VERSION ""

NS_ :

BS_:

BU_: ICC DVR EPC BBCM EAMP CMSM SBOX FLZCU_HCU_IC FLZCU_IC HCU_IC FLZCU_Signal_IC CGW TBOX BNCM CWC FRZCU

BO_ 1364 ICC_RISD_44: 64 ICC
 SG_ ICC_RISD_FrameCounter : 1|2@0+ (1,0) [0|3] "" Vector__XXX
 SG_ ICC_RISD_RollingCounter : 3|2@0+ (1,0) [0|3] "" Vector__XXX
 SG_ ICC_RISD_Pixel1_OnOff : 8|1@0+ (1,0) [0|1] "" Vector__XXX
 SG_ ICC_RISD_Pixel2_OnOff : 9|1@0+ (1,0) [0|1] "" Vector__XXX
 SG_ ICC_RISD_Pixel3_OnOff : 10|1@0+ (1,0) [0|1] "" Vector__XXX
 SG_ ICC_RISD_Pixel4_OnOff : 11|1@0+ (1,0) [0|1] "" Vector__XXX
 SG_ ICC_RISD_Pixel5_OnOff : 12|1@0+ (1,0) [0|1] "" Vector__XXX
 SG_ ICC_RISD_Pixel6_OnOff : 13|1@0+ (1,0) [0|1] "" Vector__XXX
 SG_ ICC_RISD_Pixel7_OnOff : 14|1@0+ (1,0) [0|1] "" Vector__XXX
 SG_ ICC_RISD_Pixel8_OnOff : 15|1@0+ (1,0) [0|1] "" Vector__XXX
 SG_ ICC_RISD_Pixel9_OnOff : 16|1@0+ (1,0) [0|1] "" Vector__XXX
 SG_ ICC_RISD_Pixel10_OnOff : 17|1@0+ (1,0) [0|1] "" Vector__XXX
 SG_ ICC_RISD_Pixel11_OnOff : 18|1@0+ (1,0) [0|1] "" Vector__XXX
 SG_ ICC_RISD_Pixel12_OnOff : 19|1@0+ (1,0) [0|1] "" Vector__XXX
 SG_ ICC_RISD_Pixel13_OnOff : 20|1@0+ (1,0) [0|1] "" Vector__XXX
 SG_ ICC_RISD_Pixel14_OnOff : 21|1@0+ (1,0) [0|1] "" Vector__XXX
 SG_ ICC_RISD_Pixel15_OnOff : 22|1@0+ (1,0) [0|1] "" Vector__XXX
 SG_ ICC_RISD_Pixel16_OnOff : 23|1@0+ (1,0) [0|1] "" Vector__XXX
 SG_ ICC_RISD_Pixel17_OnOff : 24|1@0+ (1,0) [0|1] "" Vector__XXX
 SG_ ICC_RISD_Pixel18_OnOff : 25|1@0+ (1,0) [0|1] "" Vector__XXX
 SG_ ICC_RISD_Pixel19_OnOff : 26|1@0+ (1,0) [0|1] "" Vector__XXX
 SG_ ICC_RISD_Pixel20_OnOff : 27|1@0+ (1,0) [0|1] "" Vector__XXX
 SG_ ICC_RISD_Pixel21_OnOff : 28|1@0+ (1,0) [0|1] "" Vector__XXX
 SG_ ICC_RISD_Pixel22_OnOff : 29|1@0+ (1,0) [0|1] "" Vector__XXX
 SG_ ICC_RISD_Pixel23_OnOff : 30|1@0+ (1,0) [0|1] "" Vector__XXX
 SG_ ICC_RISD_Pixel24_OnOff : 31|1@0+ (1,0) [0|1] "" Vector__XXX
 SG_ ICC_RISD_Pixel25_OnOff : 32|1@0+ (1,0) [0|1] "" Vector__XXX
 SG_ ICC_RISD_Pixel26_OnOff : 33|1@0+ (1,0) [0|1] "" Vector__XXX
 SG_ ICC_RISD_Pixel27_OnOff : 34|1@0+ (1,0) [0|1] "" Vector__XXX
 SG_ ICC_RISD_Pixel28_OnOff : 35|1@0+ (1,0) [0|1] "" Vector__XXX
 SG_ ICC_RISD_Pixel29_OnOff : 36|1@0+ (1,0) [0|1] "" Vector__XXX
 SG_ ICC_RISD_Pixel30_OnOff : 37|1@0+ (1,0) [0|1] "" Vector__XXX
 SG_ ICC_RISD_Pixel31_OnOff : 38|1@0+ (1,0) [0|1] "" Vector__XXX
 SG_ ICC_RISD_Pixel32_OnOff : 39|1@0+ (1,0) [0|1] "" Vector__XXX
 SG_ ICC_RISD_Pixel33_OnOff : 40|1@0+ (1,0) [0|1] "" Vector__XXX
 SG_ ICC_RISD_Pixel34_OnOff : 41|1@0+ (1,0) [0|1] "" Vector__XXX
 SG_ ICC_RISD_Pixel35_OnOff : 42|1@0+ (1,0) [0|1] "" Vector__XXX
 SG_ ICC_RISD_Pixel36_OnOff : 43|1@0+ (1,0) [0|1] "" Vector__XXX
 SG_ ICC_RISD_Pixel37_OnOff : 44|1@0+ (1,0) [0|1] "" Vector__XXX
 SG_ ICC_RISD_Pixel38_OnOff : 45|1@0+ (1,0) [0|1] "" Vector__XXX
 SG_ ICC_RISD_Pixel39_OnOff : 46|1@0+ (1,0) [0|1] "" Vector__XXX
 SG_ ICC_RISD_Pixel40_OnOff : 47|1@0+ (1,0) [0|1] "" Vector__XXX
 SG_ ICC_RISD_Pixel41_OnOff : 48|1@0+ (1,0) [0|1] "" Vector__XXX
 SG_ ICC_RISD_Pixel42_OnOff : 49|1@0+ (1,0) [0|1] "" Vector__XXX
 SG_ ICC_RISD_Pixel43_OnOff : 50|1@0+ (1,0) [0|1] "" Vector__XXX
 SG_ ICC_RISD_Pixel44_OnOff : 51|1@0+ (1,0) [0|1] "" Vector__XXX
 SG_ ICC_RISD_Pixel45_OnOff : 52|1@0+ (1,0) [0|1] "" Vector__XXX
 SG_ ICC_RISD_Pixel46_OnOff : 53|1@0+ (1,0) [0|1] "" Vector__XXX
 SG_ ICC_RISD_Pixel47_OnOff : 54|1@0+ (1,0) [0|1] "" Vector__XXX
 SG_ ICC_RISD_Pixel48_OnOff : 55|1@0+ (1,0) [0|1] "" Vector__XXX
 SG_ ICC_RISD_Pixel49_OnOff : 56|1@0+ (1,0) [0|1] "" Vector__XXX
 SG_ ICC_RISD_Pixel50_OnOff : 57|1@0+ (1,0) [0|1] "" Vector__XXX
 SG_ ICC_RISD_Pixel51_OnOff : 58|1@0+ (1,0) [0|1] "" Vector__XXX
 SG_ ICC_RISD_Pixel52_OnOff : 59|1@0+ (1,0) [0|1] "" Vector__XXX
 SG_ ICC_RISD_Pixel53_OnOff : 60|1@0+ (1,0) [0|1] "" Vector__XXX
 SG_ ICC_RISD_Pixel54_OnOff : 61|1@0+ (1,0) [0|1] "" Vector__XXX
 SG_ ICC_RISD_Pixel55_OnOff : 62|1@0+ (1,0) [0|1] "" Vector__XXX
 SG_ ICC_RISD_Pixel56_OnOff : 63|1@0+ (1,0) [0|1] "" Vector__XXX
 SG_ ICC_RISD_Pixel57_OnOff : 64|1@0+ (1,0) [0|1] "" Vector__XXX
 SG_ ICC_RISD_Pixel58_OnOff : 65|1@0+ (1,0) [0|1] "" Vector__XXX
 SG_ ICC_RISD_Pixel59_OnOff : 66|1@0+ (1,0) [0|1] "" Vector__XXX
 SG_ ICC_RISD_Pixel60_OnOff : 67|1@0+ (1,0) [0|1] "" Vector__XXX
 SG_ ICC_RISD_Pixel61_OnOff : 68|1@0+ (1,0) [0|1] "" Vector__XXX
 SG_ ICC_RISD_Pixel62_OnOff : 69|1@0+ (1,0) [0|1] "" Vector__XXX
 SG_ ICC_RISD_Pixel63_OnOff : 70|1@0+ (1,0) [0|1] "" Vector__XXX
 SG_ ICC_RISD_Pixel64_OnOff : 71|1@0+ (1,0) [0|1] "" Vector__XXX
 SG_ ICC_RISD_Pixel65_OnOff : 72|1@0+ (1,0) [0|1] "" Vector__XXX
 SG_ ICC_RISD_Pixel66_OnOff : 73|1@0+ (1,0) [0|1] "" Vector__XXX
 SG_ ICC_RISD_Pixel67_OnOff : 74|1@0+ (1,0) [0|1] "" Vector__XXX
 SG_ ICC_RISD_Pixel68_OnOff : 75|1@0+ (1,0) [0|1] "" Vector__XXX
 SG_ ICC_RISD_Pixel69_OnOff : 76|1@0+ (1,0) [0|1] "" Vector__XXX
 SG_ ICC_RISD_Pixel70_OnOff : 77|1@0+ (1,0) [0|1] "" Vector__XXX
 SG_ ICC_RISD_Pixel71_OnOff : 78|1@0+ (1,0) [0|1] "" Vector__XXX
 SG_ ICC_RISD_Pixel72_OnOff : 79|1@0+ (1,0) [0|1] "" Vector__XXX
 SG_ ICC_RISD_Pixel73_OnOff : 80|1@0+ (1,0) [0|1] "" Vector__XXX
 SG_ ICC_RISD_Pixel74_OnOff : 81|1@0+ (1,0) [0|1] "" Vector__XXX
 SG_ ICC_RISD_Pixel75_OnOff : 82|1@0+ (1,0) [0|1] "" Vector__XXX
 SG_ ICC_RISD_Pixel76_OnOff : 83|1@0+ (1,0) [0|1] "" Vector__XXX
 SG_ ICC_RISD_Pixel77_OnOff : 84|1@0+ (1,0) [0|1] "" Vector__XXX
 SG_ ICC_RISD_Pixel78_OnOff : 85|1@0+ (1,0) [0|1] "" Vector__XXX
 SG_ ICC_RISD_Pixel79_OnOff : 86|1@0+ (1,0) [0|1] "" Vector__XXX
 SG_ ICC_RISD_Pixel80_OnOff : 87|1@0+ (1,0) [0|1] "" Vector__XXX
 SG_ ICC_RISD_Pixel81_OnOff : 88|1@0+ (1,0) [0|1] "" Vector__XXX
 SG_ ICC_RISD_Pixel82_OnOff : 89|1@0+ (1,0) [0|1] "" Vector__XXX
 SG_ ICC_RISD_Pixel83_OnOff : 90|1@0+ (1,0) [0|1] "" Vector__XXX
 SG_ ICC_RISD_Pixel84_OnOff : 91|1@0+ (1,0) [0|1] "" Vector__XXX
 SG_ ICC_RISD_Pixel85_OnOff : 92|1@0+ (1,0) [0|1] "" Vector__XXX
 SG_ ICC_RISD_Pixel86_OnOff : 93|1@0+ (1,0) [0|1] "" Vector__XXX
 SG_ ICC_RISD_Pixel87_OnOff : 94|1@0+ (1,0) [0|1] "" Vector__XXX
 SG_ ICC_RISD_Pixel88_OnOff : 95|1@0+ (1,0) [0|1] "" Vector__XXX
 SG_ ICC_RISD_Pixel89_OnOff : 96|1@0+ (1,0) [0|1] "" Vector__XXX
 SG_ ICC_RISD_Pixel90_OnOff : 97|1@0+ (1,0) [0|1] "" Vector__XXX
 SG_ ICC_RISD_Pixel91_OnOff : 98|1@0+ (1,0) [0|1] "" Vector__XXX
 SG_ ICC_RISD_Pixel92_OnOff : 99|1@0+ (1,0) [0|1] "" Vector__XXX
 SG_ ICC_RISD_Pixel93_OnOff : 100|1@0+ (1,0) [0|1] "" Vector__XXX
 SG_ ICC_RISD_Pixel94_OnOff : 101|1@0+ (1,0) [0|1] "" Vector__XXX
 SG_ ICC_RISD_Pixel95_OnOff : 102|1@0+ (1,0) [0|1] "" Vector__XXX
 SG_ ICC_RISD_Pixel96_OnOff : 103|1@0+ (1,0) [0|1] "" Vector__XXX
 SG_ ICC_RISD_Pixel97_OnOff : 104|1@0+ (1,0) [0|1] "" Vector__XXX
 SG_ ICC_RISD_Pixel98_OnOff : 105|1@0+ (1,0) [0|1] "" Vector__XXX
 SG_ ICC_RISD_Pixel99_OnOff : 106|1@0+ (1,0) [0|1] "" Vector__XXX
 SG_ ICC_RISD_Pixel100_OnOff : 107|1@0+ (1,0) [0|1] "" Vector__XXX
 SG_ ICC_RISD_Pixel101_OnOff : 108|1@0+ (1,0) [0|1] "" Vector__XXX
 SG_ ICC_RISD_Pixel102_OnOff : 109|1@0+ (1,0) [0|1] "" Vector__XXX
 SG_ ICC_RISD_Pixel103_OnOff : 110|1@0+ (1,0) [0|1] "" Vector__XXX
 SG_ ICC_RISD_Pixel104_OnOff : 111|1@0+ (1,0) [0|1] "" Vector__XXX
 SG_ ICC_RISD_Pixel105_OnOff : 112|1@0+ (1,0) [0|1] "" Vector__XXX
 SG_ ICC_RISD_Pixel106_OnOff : 113|1@0+ (1,0) [0|1] "" Vector__XXX
 SG_ ICC_RISD_Pixel107_OnOff : 114|1@0+ (1,0) [0|1] "" Vector__XXX
 SG_ ICC_RISD_Pixel108_OnOff : 115|1@0+ (1,0) [0|1] "" Vector__XXX
 SG_ ICC_RISD_Pixel109_OnOff : 116|1@0+ (1,0) [0|1] "" Vector__XXX
 SG_ ICC_RISD_Pixel110_OnOff : 117|1@0+ (1,0) [0|1] "" Vector__XXX
 SG_ ICC_RISD_Pixel111_OnOff : 118|1@0+ (1,0) [0|1] "" Vector__XXX
 SG_ ICC_RISD_Pixel112_OnOff : 119|1@0+ (1,0) [0|1] "" Vector__XXX
 SG_ ICC_RISD_Pixel113_OnOff : 120|1@0+ (1,0) [0|1] "" Vector__XXX
 SG_ ICC_RISD_Pixel114_OnOff : 121|1@0+ (1,0) [0|1] "" Vector__XXX
 SG_ ICC_RISD_Pixel115_OnOff : 122|1@0+ (1,0) [0|1] "" Vector__XXX
 SG_ ICC_RISD_Pixel116_OnOff : 123|1@0+ (1,0) [0|1] "" Vector__XXX
 SG_ ICC_RISD_Pixel117_OnOff : 124|1@0+ (1,0) [0|1] "" Vector__XXX
 SG_ ICC_RISD_Pixel118_OnOff : 125|1@0+ (1,0) [0|1] "" Vector__XXX
 SG_ ICC_RISD_Pixel119_OnOff : 126|1@0+ (1,0) [0|1] "" Vector__XXX
 SG_ ICC_RISD_Pixel120_OnOff : 127|1@0+ (1,0) [0|1] "" Vector__XXX
 SG_ ICC_RISD_Pixel121_OnOff : 128|1@0+ (1,0) [0|1] "" Vector__XXX
 SG_ ICC_RISD_Pixel122_OnOff : 129|1@0+ (1,0) [0|1] "" Vector__XXX
 SG_ ICC_RISD_Pixel123_OnOff : 130|1@0+ (1,0) [0|1] "" Vector__XXX
 SG_ ICC_RISD_Pixel124_OnOff : 131|1@0+ (1,0) [0|1] "" Vector__XXX
 SG_ ICC_RISD_Pixel125_OnOff : 132|1@0+ (1,0) [0|1] "" Vector__XXX
 SG_ ICC_RISD_Pixel126_OnOff : 133|1@0+ (1,0) [0|1] "" Vector__XXX
 SG_ ICC_RISD_Pixel127_OnOff : 134|1@0+ (1,0) [0|1] "" Vector__XXX
 SG_ ICC_RISD_Pixel128_OnOff : 135|1@0+ (1,0) [0|1] "" Vector__XXX
 SG_ ICC_RISD_Pixel129_OnOff : 136|1@0+ (1,0) [0|1] "" Vector__XXX
 SG_ ICC_RISD_Pixel130_OnOff : 137|1@0+ (1,0) [0|1] "" Vector__XXX
 SG_ ICC_RISD_Pixel131_OnOff : 138|1@0+ (1,0) [0|1] "" Vector__XXX
 SG_ ICC_RISD_Pixel132_OnOff : 139|1@0+ (1,0) [0|1] "" Vector__XXX
 SG_ ICC_RISD_Pixel133_OnOff : 140|1@0+ (1,0) [0|1] "" Vector__XXX
 SG_ ICC_RISD_Pixel134_OnOff : 141|1@0+ (1,0) [0|1] "" Vector__XXX
 SG_ ICC_RISD_Pixel135_OnOff : 142|1@0+ (1,0) [0|1] "" Vector__XXX
 SG_ ICC_RISD_Pixel136_OnOff : 143|1@0+ (1,0) [0|1] "" Vector__XXX
 SG_ ICC_RISD_Pixel137_OnOff : 144|1@0+ (1,0) [0|1] "" Vector__XXX
 SG_ ICC_RISD_Pixel138_OnOff : 145|1@0+ (1,0) [0|1] "" Vector__XXX
 SG_ ICC_RISD_Pixel139_OnOff : 146|1@0+ (1,0) [0|1] "" Vector__XXX
 SG_ ICC_RISD_Pixel140_OnOff : 147|1@0+ (1,0) [0|1] "" Vector__XXX
 SG_ ICC_RISD_Pixel141_OnOff : 148|1@0+ (1,0) [0|1] "" Vector__XXX
 SG_ ICC_RISD_Pixel142_OnOff : 149|1@0+ (1,0) [0|1] "" Vector__XXX
 SG_ ICC_RISD_Pixel143_OnOff : 150|1@0+ (1,0) [0|1] "" Vector__XXX
 SG_ ICC_RISD_Pixel144_OnOff : 151|1@0+ (1,0) [0|1] "" Vector__XXX
 SG_ ICC_RISD_Pixel145_OnOff : 152|1@0+ (1,0) [0|1] "" Vector__XXX
 SG_ ICC_RISD_Pixel146_OnOff : 153|1@0+ (1,0) [0|1] "" Vector__XXX
 SG_ ICC_RISD_Pixel147_OnOff : 154|1@0+ (1,0) [0|1] "" Vector__XXX
 SG_ ICC_RISD_Pixel148_OnOff : 155|1@0+ (1,0) [0|1] "" Vector__XXX
 SG_ ICC_RISD_Pixel149_OnOff : 156|1@0+ (1,0) [0|1] "" Vector__XXX
 SG_ ICC_RISD_Pixel150_OnOff : 157|1@0+ (1,0) [0|1] "" Vector__XXX
 SG_ ICC_RISD_Pixel151_OnOff : 158|1@0+ (1,0) [0|1] "" Vector__XXX
 SG_ ICC_RISD_Pixel152_OnOff : 159|1@0+ (1,0) [0|1] "" Vector__XXX
 SG_ ICC_RISD_Pixel153_OnOff : 160|1@0+ (1,0) [0|1] "" Vector__XXX
 SG_ ICC_RISD_Pixel154_OnOff : 161|1@0+ (1,0) [0|1] "" Vector__XXX
 SG_ ICC_RISD_Pixel155_OnOff : 162|1@0+ (1,0) [0|1] "" Vector__XXX
 SG_ ICC_RISD_Pixel156_OnOff : 163|1@0+ (1,0) [0|1] "" Vector__XXX
 SG_ ICC_RISD_Pixel157_OnOff : 164|1@0+ (1,0) [0|1] "" Vector__XXX
 SG_ ICC_RISD_Pixel158_OnOff : 165|1@0+ (1,0) [0|1] "" Vector__XXX
 SG_ ICC_RISD_Pixel159_OnOff : 166|1@0+ (1,0) [0|1] "" Vector__XXX
 SG_ ICC_RISD_Pixel160_OnOff : 167|1@0+ (1,0) [0|1] "" Vector__XXX
 SG_ ICC_RISD_Pixel161_OnOff : 168|1@0+ (1,0) [0|1] "" Vector__XXX
 SG_ ICC_RISD_Pixel162_OnOff : 169|1@0+ (1,0) [0|1] "" Vector__XXX
 SG_ ICC_RISD_Pixel163_OnOff : 170|1@0+ (1,0) [0|1] "" Vector__XXX
 SG_ ICC_RISD_Pixel164_OnOff : 171|1@0+ (1,0) [0|1] "" Vector__XXX
 SG_ ICC_RISD_Pixel165_OnOff : 172|1@0+ (1,0) [0|1] "" Vector__XXX
 SG_ ICC_RISD_Pixel166_OnOff : 173|1@0+ (1,0) [0|1] "" Vector__XXX
 SG_ ICC_RISD_Pixel167_OnOff : 174|1@0+ (1,0) [0|1] "" Vector__XXX
 SG_ ICC_RISD_Pixel168_OnOff : 175|1@0+ (1,0) [0|1] "" Vector__XXX
 SG_ ICC_RISD_Pixel169_OnOff : 176|1@0+ (1,0) [0|1] "" Vector__XXX
 SG_ ICC_RISD_Pixel170_OnOff : 177|1@0+ (1,0) [0|1] "" Vector__XXX
 SG_ ICC_RISD_Pixel171_OnOff : 178|1@0+ (1,0) [0|1] "" Vector__XXX
 SG_ ICC_RISD_Pixel172_OnOff : 179|1@0+ (1,0) [0|1] "" Vector__XXX
 SG_ ICC_RISD_Pixel173_OnOff : 180|1@0+ (1,0) [0|1] "" Vector__XXX
 SG_ ICC_RISD_Pixel174_OnOff : 181|1@0+ (1,0) [0|1] "" Vector__XXX
 SG_ ICC_RISD_Pixel175_OnOff : 182|1@0+ (1,0) [0|1] "" Vector__XXX
 SG_ ICC_RISD_Pixel176_OnOff : 183|1@0+ (1,0) [0|1] "" Vector__XXX
 SG_ ICC_RISD_Pixel177_OnOff : 184|1@0+ (1,0) [0|1] "" Vector__XXX
 SG_ ICC_RISD_Pixel178_OnOff : 185|1@0+ (1,0) [0|1] "" Vector__XXX
 SG_ ICC_RISD_Pixel179_OnOff : 186|1@0+ (1,0) [0|1] "" Vector__XXX
 SG_ ICC_RISD_Pixel180_OnOff : 187|1@0+ (1,0) [0|1] "" Vector__XXX
 SG_ ICC_RISD_Pixel181_OnOff : 188|1@0+ (1,0) [0|1] "" Vector__XXX
 SG_ ICC_RISD_Pixel182_OnOff : 189|1@0+ (1,0) [0|1] "" Vector__XXX
 SG_ ICC_RISD_Pixel183_OnOff : 190|1@0+ (1,0) [0|1] "" Vector__XXX
 SG_ ICC_RISD_Pixel184_OnOff : 191|1@0+ (1,0) [0|1] "" Vector__XXX
 SG_ ICC_RISD_Pixel185_OnOff : 192|1@0+ (1,0) [0|1] "" Vector__XXX
 SG_ ICC_RISD_Pixel186_OnOff : 193|1@0+ (1,0) [0|1] "" Vector__XXX
 SG_ ICC_RISD_Pixel187_OnOff : 194|1@0+ (1,0) [0|1] "" Vector__XXX
 SG_ ICC_RISD_Pixel188_OnOff : 195|1@0+ (1,0) [0|1] "" Vector__XXX
 SG_ ICC_RISD_Pixel189_OnOff : 196|1@0+ (1,0) [0|1] "" Vector__XXX
 SG_ ICC_RISD_Pixel190_OnOff : 197|1@0+ (1,0) [0|1] "" Vector__XXX
 SG_ ICC_RISD_Pixel191_OnOff : 198|1@0+ (1,0) [0|1] "" Vector__XXX
 SG_ ICC_RISD_Pixel192_OnOff : 199|1@0+ (1,0) [0|1] "" Vector__XXX
 SG_ ICC_RISD_Pixel193_OnOff : 200|1@0+ (1,0) [0|1] "" Vector__XXX
 SG_ ICC_RISD_Pixel194_OnOff : 201|1@0+ (1,0) [0|1] "" Vector__XXX
 SG_ ICC_RISD_Pixel195_OnOff : 202|1@0+ (1,0) [0|1] "" Vector__XXX
 SG_ ICC_RISD_Pixel196_OnOff : 203|1@0+ (1,0) [0|1] "" Vector__XXX
 SG_ ICC_RISD_Pixel197_OnOff : 204|1@0+ (1,0) [0|1] "" Vector__XXX
 SG_ ICC_RISD_Pixel198_OnOff : 205|1@0+ (1,0) [0|1] "" Vector__XXX
 SG_ ICC_RISD_Pixel199_OnOff : 206|1@0+ (1,0) [0|1] "" Vector__XXX
 SG_ ICC_RISD_Pixel200_OnOff : 207|1@0+ (1,0) [0|1] "" Vector__XXX
 SG_ ICC_RISD_Pixel201_OnOff : 208|1@0+ (1,0) [0|1] "" Vector__XXX
 SG_ ICC_RISD_Pixel202_OnOff : 209|1@0+ (1,0) [0|1] "" Vector__XXX
 SG_ ICC_RISD_Pixel203_OnOff : 210|1@0+ (1,0) [0|1] "" Vector__XXX
 SG_ ICC_RISD_Pixel204_OnOff : 211|1@0+ (1,0) [0|1] "" Vector__XXX
 SG_ ICC_RISD_Pixel205_OnOff : 212|1@0+ (1,0) [0|1] "" Vector__XXX
 SG_ ICC_RISD_Pixel206_OnOff : 213|1@0+ (1,0) [0|1] "" Vector__XXX
 SG_ ICC_RISD_Pixel207_OnOff : 214|1@0+ (1,0) [0|1] "" Vector__XXX
 SG_ ICC_RISD_Pixel208_OnOff : 215|1@0+ (1,0) [0|1] "" Vector__XXX
 SG_ ICC_RISD_Pixel209_OnOff : 216|1@0+ (1,0) [0|1] "" Vector__XXX
 SG_ ICC_RISD_Pixel210_OnOff : 217|1@0+ (1,0) [0|1] "" Vector__XXX
 SG_ ICC_RISD_Pixel211_OnOff : 218|1@0+ (1,0) [0|1] "" Vector__XXX
 SG_ ICC_RISD_Pixel212_OnOff : 219|1@0+ (1,0) [0|1] "" Vector__XXX
 SG_ ICC_RISD_Pixel213_OnOff : 220|1@0+ (1,0) [0|1] "" Vector__XXX
 SG_ ICC_RISD_Pixel214_OnOff : 221|1@0+ (1,0) [0|1] "" Vector__XXX
 SG_ ICC_RISD_Pixel215_OnOff : 222|1@0+ (1,0) [0|1] "" Vector__XXX
 SG_ ICC_RISD_Pixel216_OnOff : 223|1@0+ (1,0) [0|1] "" Vector__XXX
 SG_ ICC_RISD_Pixel217_OnOff : 224|1@0+ (1,0) [0|1] "" Vector__XXX
 SG_ ICC_RISD_Pixel218_OnOff : 225|1@0+ (1,0) [0|1] "" Vector__XXX
 SG_ ICC_RISD_Pixel219_OnOff : 226|1@0+ (1,0) [0|1] "" Vector__XXX
 SG_ ICC_RISD_Pixel220_OnOff : 227|1@0+ (1,0) [0|1] "" Vector__XXX
 SG_ ICC_RISD_Pixel221_OnOff : 228|1@0+ (1,0) [0|1] "" Vector__XXX
 SG_ ICC_RISD_Pixel222_OnOff : 229|1@0+ (1,0) [0|1] "" Vector__XXX
 SG_ ICC_RISD_Pixel223_OnOff : 230|1@0+ (1,0) [0|1] "" Vector__XXX
 SG_ ICC_RISD_Pixel224_OnOff : 231|1@0+ (1,0) [0|1] "" Vector__XXX
 SG_ ICC_RISD_Pixel225_OnOff : 232|1@0+ (1,0) [0|1] "" Vector__XXX
 SG_ ICC_RISD_Pixel226_OnOff : 233|1@0+ (1,0) [0|1] "" Vector__XXX
 SG_ ICC_RISD_Pixel227_OnOff : 234|1@0+ (1,0) [0|1] "" Vector__XXX
 SG_ ICC_RISD_Pixel228_OnOff : 235|1@0+ (1,0) [0|1] "" Vector__XXX
 SG_ ICC_RISD_Pixel229_OnOff : 236|1@0+ (1,0) [0|1] "" Vector__XXX
 SG_ ICC_RISD_Pixel230_OnOff : 237|1@0+ (1,0) [0|1] "" Vector__XXX
 SG_ ICC_RISD_Pixel231_OnOff : 238|1@0+ (1,0) [0|1] "" Vector__XXX
 SG_ ICC_RISD_Pixel232_OnOff : 239|1@0+ (1,0) [0|1] "" Vector__XXX
 SG_ ICC_RISD_Pixel233_OnOff : 240|1@0+ (1,0) [0|1] "" Vector__XXX
 SG_ ICC_RISD_Pixel234_OnOff : 241|1@0+ (1,0) [0|1] "" Vector__XXX
 SG_ ICC_RISD_Pixel235_OnOff : 242|1@0+ (1,0) [0|1] "" Vector__XXX
 SG_ ICC_RISD_Pixel236_OnOff : 243|1@0+ (1,0) [0|1] "" Vector__XXX
 SG_ ICC_RISD_Pixel237_OnOff : 244|1@0+ (1,0) [0|1] "" Vector__XXX
 SG_ ICC_RISD_Pixel238_OnOff : 245|1@0+ (1,0) [0|1] "" Vector__XXX
 SG_ ICC_RISD_Pixel239_OnOff : 246|1@0+ (1,0) [0|1] "" Vector__XXX
 SG_ ICC_RISD_Pixel240_OnOff : 247|1@0+ (1,0) [0|1] "" Vector__XXX
 SG_ ICC_RISD_Pixel241_OnOff : 248|1@0+ (1,0) [0|1] "" Vector__XXX
 SG_ ICC_RISD_Pixel242_OnOff : 249|1@0+ (1,0) [0|1] "" Vector__XXX
 SG_ ICC_RISD_Pixel243_OnOff : 250|1@0+ (1,0) [0|1] "" Vector__XXX
 SG_ ICC_RISD_Pixel244_OnOff : 251|1@0+ (1,0) [0|1] "" Vector__XXX
 SG_ ICC_RISD_Pixel245_OnOff : 252|1@0+ (1,0) [0|1] "" Vector__XXX
 SG_ ICC_RISD_Pixel246_OnOff : 253|1@0+ (1,0) [0|1] "" Vector__XXX
 SG_ ICC_RISD_Pixel247_OnOff : 254|1@0+ (1,0) [0|1] "" Vector__XXX
 SG_ ICC_RISD_Pixel248_OnOff : 255|1@0+ (1,0) [0|1] "" Vector__XXX
 SG_ ICC_RISD_Pixel249_OnOff : 256|1@0+ (1,0) [0|1] "" Vector__XXX
 SG_ ICC_RISD_Pixel250_OnOff : 257|1@0+ (1,0) [0|1] "" Vector__XXX
 SG_ ICC_RISD_Pixel251_OnOff : 258|1@0+ (1,0) [0|1] "" Vector__XXX
 SG_ ICC_RISD_Pixel252_OnOff : 259|1@0+ (1,0) [0|1] "" Vector__XXX
 SG_ ICC_RISD_Pixel253_OnOff : 260|1@0+ (1,0) [0|1] "" Vector__XXX
 SG_ ICC_RISD_Pixel254_OnOff : 261|1@0+ (1,0) [0|1] "" Vector__XXX
 SG_ ICC_RISD_Pixel255_OnOff : 262|1@0+ (1,0) [0|1] "" Vector__XXX
 SG_ ICC_RISD_Pixel256_OnOff : 263|1@0+ (1,0) [0|1] "" Vector__XXX
 SG_ ICC_RISD_Pixel257_OnOff : 264|1@0+ (1,0) [0|1] "" Vector__XXX
 SG_ ICC_RISD_Pixel258_OnOff : 265|1@0+ (1,0) [0|1] "" Vector__XXX
 SG_ ICC_RISD_Pixel259_OnOff : 266|1@0+ (1,0) [0|1] "" Vector__XXX
 SG_ ICC_RISD_Pixel260_OnOff : 267|1@0+ (1,0) [0|1] "" Vector__XXX
 SG_ ICC_RISD_Pixel261_OnOff : 268|1@0+ (1,0) [0|1] "" Vector__XXX
 SG_ ICC_RISD_Pixel262_OnOff : 269|1@0+ (1,0) [0|1] "" Vector__XXX
 SG_ ICC_RISD_Pixel263_OnOff : 270|1@0+ (1,0) [0|1] "" Vector__XXX
 SG_ ICC_RISD_Pixel264_OnOff : 271|1@0+ (1,0) [0|1] "" Vector__XXX
 SG_ ICC_RISD_Pixel265_OnOff : 272|1@0+ (1,0) [0|1] "" Vector__XXX
 SG_ ICC_RISD_Pixel266_OnOff : 273|1@0+ (1,0) [0|1] "" Vector__XXX
 SG_ ICC_RISD_Pixel267_OnOff : 274|1@0+ (1,0) [0|1] "" Vector__XXX
 SG_ ICC_RISD_Pixel268_OnOff : 275|1@0+ (1,0) [0|1] "" Vector__XXX
 SG_ ICC_RISD_Pixel269_OnOff : 276|1@0+ (1,0) [0|1] "" Vector__XXX
 SG_ ICC_RISD_Pixel270_OnOff : 277|1@0+ (1,0) [0|1] "" Vector__XXX
 SG_ ICC_RISD_Pixel271_OnOff : 278|1@0+ (1,0) [0|1] "" Vector__XXX
 SG_ ICC_RISD_Pixel272_OnOff : 279|1@0+ (1,0) [0|1] "" Vector__XXX
 SG_ ICC_RISD_Pixel273_OnOff : 280|1@0+ (1,0) [0|1] "" Vector__XXX
 SG_ ICC_RISD_Pixel274_OnOff : 281|1@0+ (1,0) [0|1] "" Vector__XXX
 SG_ ICC_RISD_Pixel275_OnOff : 282|1@0+ (1,0) [0|1] "" Vector__XXX
 SG_ ICC_RISD_Pixel276_OnOff : 283|1@0+ (1,0) [0|1] "" Vector__XXX
 SG_ ICC_RISD_Pixel277_OnOff : 284|1@0+ (1,0) [0|1] "" Vector__XXX
 SG_ ICC_RISD_Pixel278_OnOff : 285|1@0+ (1,0) [0|1] "" Vector__XXX
 SG_ ICC_RISD_Pixel279_OnOff : 286|1@0+ (1,0) [0|1] "" Vector__XXX
 SG_ ICC_RISD_Pixel280_OnOff : 287|1@0+ (1,0) [0|1] "" Vector__XXX
 SG_ ICC_RISD_Pixel281_OnOff : 288|1@0+ (1,0) [0|1] "" Vector__XXX
 SG_ ICC_RISD_Pixel282_OnOff : 289|1@0+ (1,0) [0|1] "" Vector__XXX
 SG_ ICC_RISD_Pixel283_OnOff : 290|1@0+ (1,0) [0|1] "" Vector__XXX
 SG_ ICC_RISD_Pixel284_OnOff : 291|1@0+ (1,0) [0|1] "" Vector__XXX
 SG_ ICC_RISD_Pixel285_OnOff : 292|1@0+ (1,0) [0|1] "" Vector__XXX
 SG_ ICC_RISD_Pixel286_OnOff : 293|1@0+ (1,0) [0|1] "" Vector__XXX
 SG_ ICC_RISD_Pixel287_OnOff : 294|1@0+ (1,0) [0|1] "" Vector__XXX
 SG_ ICC_RISD_Pixel288_OnOff : 295|1@0+ (1,0) [0|1] "" Vector__XXX
 SG_ ICC_RISD_Pixel289_OnOff : 296|1@0+ (1,0) [0|1] "" Vector__XXX
 SG_ ICC_RISD_Pixel290_OnOff : 297|1@0+ (1,0) [0|1] "" Vector__XXX
 SG_ ICC_RISD_Pixel291_OnOff : 298|1@0+ (1,0) [0|1] "" Vector__XXX
 SG_ ICC_RISD_Pixel292_OnOff : 299|1@0+ (1,0) [0|1] "" Vector__XXX
 SG_ ICC_RISD_Pixel293_OnOff : 300|1@0+ (1,0) [0|1] "" Vector__XXX
 SG_ ICC_RISD_Pixel294_OnOff : 301|1@0+ (1,0) [0|1] "" Vector__XXX
 SG_ ICC_RISD_Pixel295_OnOff : 302|1@0+ (1,0) [0|1] "" Vector__XXX
 SG_ ICC_RISD_Pixel296_OnOff : 303|1@0+ (1,0) [0|1] "" Vector__XXX
 SG_ ICC_RISD_Pixel297_OnOff : 304|1@0+ (1,0) [0|1] "" Vector__XXX
 SG_ ICC_RISD_Pixel298_OnOff : 305|1@0+ (1,0) [0|1] "" Vector__XXX
 SG_ ICC_RISD_Pixel299_OnOff : 306|1@0+ (1,0) [0|1] "" Vector__XXX
 SG_ ICC_RISD_Pixel300_OnOff : 307|1@0+ (1,0) [0|1] "" Vector__XXX
 SG_ ICC_RISD_Pixel301_OnOff : 308|1@0+ (1,0) [0|1] "" Vector__XXX
 SG_ ICC_RISD_Pixel302_OnOff : 309|1@0+ (1,0) [0|1] "" Vector__XXX
 SG_ ICC_RISD_Pixel303_OnOff : 310|1@0+ (1,0) [0|1] "" Vector__XXX
 SG_ ICC_RISD_Pixel304_OnOff : 311|1@0+ (1,0) [0|1] "" Vector__XXX
 SG_ ICC_RISD_Pixel305_OnOff : 312|1@0+ (1,0) [0|1] "" Vector__XXX
 SG_ ICC_RISD_Pixel306_OnOff : 313|1@0+ (1,0) [0|1] "" Vector__XXX
 SG_ ICC_RISD_Pixel307_OnOff : 314|1@0+ (1,0) [0|1] "" Vector__XXX
 SG_ ICC_RISD_Pixel308_OnOff : 315|1@0+ (1,0) [0|1] "" Vector__XXX
 SG_ ICC_RISD_Pixel309_OnOff : 316|1@0+ (1,0) [0|1] "" Vector__XXX
 SG_ ICC_RISD_Pixel310_OnOff : 317|1@0+ (1,0) [0|1] "" Vector__XXX
 SG_ ICC_RISD_Pixel311_OnOff : 318|1@0+ (1,0) [0|1] "" Vector__XXX
 SG_ ICC_RISD_Pixel312_OnOff : 319|1@0+ (1,0) [0|1] "" Vector__XXX
 SG_ ICC_RISD_Pixel313_OnOff : 320|1@0+ (1,0) [0|1] "" Vector__XXX
 SG_ ICC_RISD_Pixel314_OnOff : 321|1@0+ (1,0) [0|1] "" Vector__XXX
 SG_ ICC_RISD_Pixel315_OnOff : 322|1@0+ (1,0) [0|1] "" Vector__XXX
 SG_ ICC_RISD_Pixel316_OnOff : 323|1@0+ (1,0) [0|1] "" Vector__XXX
 SG_ ICC_RISD_Pixel317_OnOff : 324|1@0+ (1,0) [0|1] "" Vector__XXX
 SG_ ICC_RISD_Pixel318_OnOff : 325|1@0+ (1,0) [0|1] "" Vector__XXX
 SG_ ICC_RISD_Pixel319_OnOff : 326|1@0+ (1,0) [0|1] "" Vector__XXX
 SG_ ICC_RISD_Pixel320_OnOff : 327|1@0+ (1,0) [0|1] "" Vector__XXX
 SG_ ICC_RISD_Pixel321_OnOff : 328|1@0+ (1,0) [0|1] "" Vector__XXX
 SG_ ICC_RISD_Pixel322_OnOff : 329|1@0+ (1,0) [0|1] "" Vector__XXX
 SG_ ICC_RISD_Pixel323_OnOff : 330|1@0+ (1,0) [0|1] "" Vector__XXX
 SG_ ICC_RISD_Pixel324_OnOff : 331|1@0+ (1,0) [0|1] "" Vector__XXX
 SG_ ICC_RISD_Pixel325_OnOff : 332|1@0+ (1,0) [0|1] "" Vector__XXX
 SG_ ICC_RISD_Pixel326_OnOff : 333|1@0+ (1,0) [0|1] "" Vector__XXX
 SG_ ICC_RISD_Pixel327_OnOff : 334|1@0+ (1,0) [0|1] "" Vector__XXX
 SG_ ICC_RISD_Pixel328_OnOff : 335|1@0+ (1,0) [0|1] "" Vector__XXX
 SG_ ICC_RISD_Pixel329_OnOff : 336|1@0+ (1,0) [0|1] "" Vector__XXX
 SG_ ICC_RISD_Pixel330_OnOff : 337|1@0+ (1,0) [0|1] "" Vector__XXX
 SG_ ICC_RISD_Pixel331_OnOff : 338|1@0+ (1,0) [0|1] "" Vector__XXX
 SG_ ICC_RISD_Pixel332_OnOff : 339|1@0+ (1,0) [0|1] "" Vector__XXX
 SG_ ICC_RISD_Pixel333_OnOff : 340|1@0+ (1,0) [0|1] "" Vector__XXX
 SG_ ICC_RISD_Pixel334_OnOff : 341|1@0+ (1,0) [0|1] "" Vector__XXX
 SG_ ICC_RISD_Pixel335_OnOff : 342|1@0+ (1,0) [0|1] "" Vector__XXX
 SG_ ICC_RISD_Pixel336_OnOff : 343|1@0+ (1,0) [0|1] "" Vector__XXX
 SG_ ICC_RISD_Pixel337_OnOff : 344|1@0+ (1,0) [0|1] "" Vector__XXX
 SG_ ICC_RISD_Pixel338_OnOff : 345|1@0+ (1,0) [0|1] "" Vector__XXX
 SG_ ICC_RISD_Pixel339_OnOff : 346|1@0+ (1,0) [0|1] "" Vector__XXX
 SG_ ICC_RISD_Pixel340_OnOff : 347|1@0+ (1,0) [0|1] "" Vector__XXX
 SG_ ICC_RISD_Pixel341_OnOff : 348|1@0+ (1,0) [0|1] "" Vector__XXX
 SG_ ICC_RISD_Pixel342_OnOff : 349|1@0+ (1,0) [0|1] "" Vector__XXX
 SG_ ICC_RISD_Pixel343_OnOff : 350|1@0+ (1,0) [0|1] "" Vector__XXX
 SG_ ICC_RISD_Pixel344_OnOff : 351|1@0+ (1,0) [0|1] "" Vector__XXX
 SG_ ICC_RISD_Pixel345_OnOff : 352|1@0+ (1,0) [0|1] "" Vector__XXX
 SG_ ICC_RISD_Pixel346_OnOff : 353|1@0+ (1,0) [0|1] "" Vector__XXX
 SG_ ICC_RISD_Pixel347_OnOff : 354|1@0+ (1,0) [0|1] "" Vector__XXX
 SG_ ICC_RISD_Pixel348_OnOff : 355|1@0+ (1,0) [0|1] "" Vector__XXX
 SG_ ICC_RISD_Pixel349_OnOff : 356|1@0+ (1,0) [0|1] "" Vector__XXX
 SG_ ICC_RISD_Pixel350_OnOff : 357|1@0+ (1,0) [0|1] "" Vector__XXX
 SG_ ICC_RISD_Pixel351_OnOff : 358|1@0+ (1,0) [0|1] "" Vector__XXX
 SG_ ICC_RISD_Pixel352_OnOff : 359|1@0+ (1,0) [0|1] "" Vector__XXX
 SG_ ICC_RISD_Pixel353_OnOff : 360|1@0+ (1,0) [0|1] "" Vector__XXX
 SG_ ICC_RISD_Pixel354_OnOff : 361|1@0+ (1,0) [0|1] "" Vector__XXX
 SG_ ICC_RISD_Pixel355_OnOff : 362|1@0+ (1,0) [0|1] "" Vector__XXX
 SG_ ICC_RISD_Pixel356_OnOff : 363|1@0+ (1,0) [0|1] "" Vector__XXX
 SG_ ICC_RISD_Pixel357_OnOff : 364|1@0+ (1,0) [0|1] "" Vector__XXX
 SG_ ICC_RISD_Pixel358_OnOff : 365|1@0+ (1,0) [0|1] "" Vector__XXX
 SG_ ICC_RISD_Pixel359_OnOff : 366|1@0+ (1,0) [0|1] "" Vector__XXX
 SG_ ICC_RISD_Pixel360_OnOff : 367|1@0+ (1,0) [0|1] "" Vector__XXX
 SG_ ICC_RISD_Pixel361_OnOff : 368|1@0+ (1,0) [0|1] "" Vector__XXX
 SG_ ICC_RISD_Pixel362_OnOff : 369|1@0+ (1,0) [0|1] "" Vector__XXX
 SG_ ICC_RISD_Pixel363_OnOff : 370|1@0+ (1,0) [0|1] "" Vector__XXX
 SG_ ICC_RISD_Pixel364_OnOff : 371|1@0+ (1,0) [0|1] "" Vector__XXX
 SG_ ICC_RISD_Pixel365_OnOff : 372|1@0+ (1,0) [0|1] "" Vector__XXX
 SG_ ICC_RISD_Pixel366_OnOff : 373|1@0+ (1,0) [0|1] "" Vector__XXX
 SG_ ICC_RISD_Pixel367_OnOff : 374|1@0+ (1,0) [0|1] "" Vector__XXX
 SG_ ICC_RISD_Pixel368_OnOff : 375|1@0+ (1,0) [0|1] "" Vector__XXX
 SG_ ICC_RISD_Pixel369_OnOff : 376|1@0+ (1,0) [0|1] "" Vector__XXX
 SG_ ICC_RISD_Pixel370_OnOff : 377|1@0+ (1,0) [0|1] "" Vector__XXX
 SG_ ICC_RISD_Pixel371_OnOff : 378|1@0+ (1,0) [0|1] "" Vector__XXX
 SG_ ICC_RISD_Pixel372_OnOff : 379|1@0+ (1,0) [0|1] "" Vector__XXX
 SG_ ICC_RISD_Pixel373_OnOff : 380|1@0+ (1,0) [0|1] "" Vector__XXX
 SG_ ICC_RISD_Pixel374_OnOff : 381|1@0+ (1,0) [0|1] "" Vector__XXX
 SG_ ICC_RISD_Pixel375_OnOff : 382|1@0+ (1,0) [0|1] "" Vector__XXX
 SG_ ICC_RISD_Pixel376_OnOff : 383|1@0+ (1,0) [0|1] "" Vector__XXX
 SG_ ICC_RISD_Pixel377_OnOff : 384|1@0+ (1,0) [0|1] "" Vector__XXX
 SG_ ICC_RISD_Pixel378_OnOff : 385|1@0+ (1,0) [0|1] "" Vector__XXX
 SG_ ICC_RISD_Pixel379_OnOff : 386|1@0+ (1,0) [0|1] "" Vector__XXX
 SG_ ICC_RISD_Pixel380_OnOff : 387|1@0+ (1,0) [0|1] "" Vector__XXX
 SG_ ICC_RISD_Pixel381_OnOff : 388|1@0+ (1,0) [0|1] "" Vector__XXX
 SG_ ICC_RISD_Pixel382_OnOff : 389|1@0+ (1,0) [0|1] "" Vector__XXX
 SG_ ICC_RISD_Pixel383_OnOff : 390|1@0+ (1,0) [0|1] "" Vector__XXX
 SG_ ICC_RISD_Pixel384_OnOff : 391|1@0+ (1,0) [0|1] "" Vector__XXX
 SG_ ICC_RISD_Pixel385_OnOff : 392|1@0+ (1,0) [0|1] "" Vector__XXX
 SG_ ICC_RISD_Pixel386_OnOff : 393|1@0+ (1,0) [0|1] "" Vector__XXX
 SG_ ICC_RISD_Pixel387_OnOff : 394|1@0+ (1,0) [0|1] "" Vector__XXX
 SG_ ICC_RISD_Pixel388_OnOff : 395|1@0+ (1,0) [0|1] "" Vector__XXX
 SG_ ICC_RISD_Pixel389_OnOff : 396|1@0+ (1,0) [0|1] "" Vector__XXX
 SG_ ICC_RISD_Pixel390_OnOff : 397|1@0+ (1,0) [0|1] "" Vector__XXX
 SG_ ICC_RISD_Pixel391_OnOff : 398|1@0+ (1,0) [0|1] "" Vector__XXX
 SG_ ICC_RISD_Pixel392_OnOff : 399|1@0+ (1,0) [0|1] "" Vector__XXX
 SG_ ICC_RISD_Pixel393_OnOff : 400|1@0+ (1,0) [0|1] "" Vector__XXX
 SG_ ICC_RISD_Pixel394_OnOff : 401|1@0+ (1,0) [0|1] "" Vector__XXX
 SG_ ICC_RISD_Pixel395_OnOff : 402|1@0+ (1,0) [0|1] "" Vector__XXX
 SG_ ICC_RISD_Pixel396_OnOff : 403|1@0+ (1,0) [0|1] "" Vector__XXX
 SG_ ICC_RISD_Pixel397_OnOff : 404|1@0+ (1,0) [0|1] "" Vector__XXX
 SG_ ICC_RISD_Pixel398_OnOff : 405|1@0+ (1,0) [0|1] "" Vector__XXX
 SG_ ICC_RISD_Pixel399_OnOff : 406|1@0+ (1,0) [0|1] "" Vector__XXX
 SG_ ICC_RISD_Pixel400_OnOff : 407|1@0+ (1,0) [0|1] "" Vector__XXX
 SG_ ICC_RISD_Pixel401_OnOff : 408|1@0+ (1,0) [0|1] "" Vector__XXX
 SG_ ICC_RISD_Pixel402_OnOff : 409|1@0+ (1,0) [0|1] "" Vector__XXX
 SG_ ICC_RISD_Pixel403_OnOff : 410|1@0+ (1,0) [0|1] "" Vector__XXX
 SG_ ICC_RISD_Pixel404_OnOff : 411|1@0+ (1,0) [0|1] "" Vector__XXX
 SG_ ICC_RISD_Pixel405_OnOff : 412|1@0+ (1,0) [0|1] "" Vector__XXX
 SG_ ICC_RISD_Pixel406_OnOff : 413|1@0+ (1,0) [0|1] "" Vector__XXX
 SG_ ICC_RISD_Pixel407_OnOff : 414|1@0+ (1,0) [0|1] "" Vector__XXX
 SG_ ICC_RISD_Pixel408_OnOff : 415|1@0+ (1,0) [0|1] "" Vector__XXX
 SG_ ICC_RISD_Pixel409_OnOff : 416|1@0+ (1,0) [0|1] "" Vector__XXX
 SG_ ICC_RISD_Pixel410_OnOff : 417|1@0+ (1,0) [0|1] "" Vector__XXX
 SG_ ICC_RISD_Pixel411_OnOff : 418|1@0+ (1,0) [0|1] "" Vector__XXX
 SG_ ICC_RISD_Pixel412_OnOff : 419|1@0+ (1,0) [0|1] "" Vector__XXX
 SG_ ICC_RISD_Pixel413_OnOff : 420|1@0+ (1,0) [0|1] "" Vector__XXX
 SG_ ICC_RISD_Pixel414_OnOff : 421|1@0+ (1,0) [0|1] "" Vector__XXX
 SG_ ICC_RISD_Pixel415_OnOff : 422|1@0+ (1,0) [0|1] "" Vector__XXX
 SG_ ICC_RISD_Pixel416_OnOff : 423|1@0+ (1,0) [0|1] "" Vector__XXX
 SG_ ICC_RISD_Pixel417_OnOff : 424|1@0+ (1,0) [0|1] "" Vector__XXX
 SG_ ICC_RISD_Pixel418_OnOff : 425|1@0+ (1,0) [0|1] "" Vector__XXX
 SG_ ICC_RISD_Pixel419_OnOff : 426|1@0+ (1,0) [0|1] "" Vector__XXX
 SG_ ICC_RISD_Pixel420_OnOff : 427|1@0+ (1,0) [0|1] "" Vector__XXX
 SG_ ICC_RISD_Pixel421_OnOff : 428|1@0+ (1,0) [0|1] "" Vector__XXX
 SG_ ICC_RISD_Pixel422_OnOff : 429|1@0+ (1,0) [0|1] "" Vector__XXX
 SG_ ICC_RISD_Pixel423_OnOff : 430|1@0+ (1,0) [0|1] "" Vector__XXX
 SG_ ICC_RISD_Pixel424_OnOff : 431|1@0+ (1,0) [0|1] "" Vector__XXX
 SG_ ICC_RISD_Pixel425_OnOff : 432|1@0+ (1,0) [0|1] "" Vector__XXX
 SG_ ICC_RISD_Pixel426_OnOff : 433|1@0+ (1,0) [0|1] "" Vector__XXX
 SG_ ICC_RISD_Pixel427_OnOff : 434|1@0+ (1,0) [0|1] "" Vector__XXX
 SG_ ICC_RISD_Pixel428_OnOff : 435|1@0+ (1,0) [0|1] "" Vector__XXX
 SG_ ICC_RISD_Pixel429_OnOff : 436|1@0+ (1,0) [0|1] "" Vector__XXX
 SG_ ICC_RISD_Pixel430_OnOff : 437|1@0+ (1,0) [0|1] "" Vector__XXX
 SG_ ICC_RISD_Pixel431_OnOff : 438|1@0+ (1,0) [0|1] "" Vector__XXX
 SG_ ICC_RISD_Pixel432_OnOff : 439|1@0+ (1,0) [0|1] "" Vector__XXX
 SG_ ICC_RISD_Pixel433_OnOff : 440|1@0+ (1,0) [0|1] "" Vector__XXX
 SG_ ICC_RISD_Pixel434_OnOff : 441|1@0+ (1,0) [0|1] "" Vector__XXX
 SG_ ICC_RISD_Pixel435_OnOff : 442|1@0+ (1,0) [0|1] "" Vector__XXX
 SG_ ICC_RISD_Pixel436_OnOff : 443|1@0+ (1,0) [0|1] "" Vector__XXX
 SG_ ICC_RISD_Pixel437_OnOff : 444|1@0+ (1,0) [0|1] "" Vector__XXX
 SG_ ICC_RISD_Pixel438_OnOff : 445|1@0+ (1,0) [0|1] "" Vector__XXX
 SG_ ICC_RISD_Pixel439_OnOff : 446|1@0+ (1,0) [0|1] "" Vector__XXX
 SG_ ICC_RISD_Pixel440_OnOff : 447|1@0+ (1,0) [0|1] "" Vector__XXX
 SG_ ICC_RISD_Pixel441_OnOff : 448|1@0+ (1,0) [0|1] "" Vector__XXX
 SG_ ICC_RISD_Pixel442_OnOff : 449|1@0+ (1,0) [0|1] "" Vector__XXX
 SG_ ICC_RISD_Pixel443_OnOff : 450|1@0+ (1,0) [0|1] "" Vector__XXX
 SG_ ICC_RISD_Pixel444_OnOff : 451|1@0+ (1,0) [0|1] "" Vector__XXX
 SG_ ICC_RISD_Pixel445_OnOff : 452|1@0+ (1,0) [0|1] "" Vector__XXX
 SG_ ICC_RISD_Pixel446_OnOff : 453|1@0+ (1,0) [0|1] "" Vector__XXX
 SG_ ICC_RISD_Pixel447_OnOff : 454|1@0+ (1,0) [0|1] "" Vector__XXX
 SG_ ICC_RISD_Pixel448_OnOff : 455|1@0+ (1,0) [0|1] "" Vector__XXX
 SG_ ICC_RISD_Pixel449_OnOff : 456|1@0+ (1,0) [0|1] "" Vector__XXX
 SG_ ICC_RISD_Pixel450_OnOff : 457|1@0+ (1,0) [0|1] "" Vector__XXX
 SG_ ICC_RISD_Pixel451_OnOff : 458|1@0+ (1,0) [0|1] "" Vector__XXX
 SG_ ICC_RISD_Pixel452_OnOff : 459|1@0+ (1,0) [0|1] "" Vector__XXX
 SG_ ICC_RISD_Pixel453_OnOff : 460|1@0+ (1,0) [0|1] "" Vector__XXX
 SG_ ICC_RISD_Pixel454_OnOff : 461|1@0+ (1,0) [0|1] "" Vector__XXX
 SG_ ICC_RISD_Pixel455_OnOff : 462|1@0+ (1,0) [0|1] "" Vector__XXX
 SG_ ICC_RISD_Pixel456_OnOff : 463|1@0+ (1,0) [0|1] "" Vector__XXX
 SG_ ICC_RISD_Pixel457_OnOff : 464|1@0+ (1,0) [0|1] "" Vector__XXX
 SG_ ICC_RISD_Pixel458_OnOff : 465|1@0+ (1,0) [0|1] "" Vector__XXX
 SG_ ICC_RISD_Pixel459_OnOff : 466|1@0+ (1,0) [0|1] "" Vector__XXX
 SG_ ICC_RISD_Pixel460_OnOff : 467|1@0+ (1,0) [0|1] "" Vector__XXX
 SG_ ICC_RISD_Pixel461_OnOff : 468|1@0+ (1,0) [0|1] "" Vector__XXX
 SG_ ICC_RISD_Pixel462_OnOff : 469|1@0+ (1,0) [0|1] "" Vector__XXX
 SG_ ICC_RISD_Pixel463_OnOff : 470|1@0+ (1,0) [0|1] "" Vector__XXX
 SG_ ICC_RISD_Pixel464_OnOff : 471|1@0+ (1,0) [0|1] "" Vector__XXX
 SG_ ICC_RISD_Pixel465_OnOff : 472|1@0+ (1,0) [0|1] "" Vector__XXX
 SG_ ICC_RISD_Pixel466_OnOff : 473|1@0+ (1,0) [0|1] "" Vector__XXX
 SG_ ICC_RISD_Pixel467_OnOff : 474|1@0+ (1,0) [0|1] "" Vector__XXX
 SG_ ICC_RISD_Pixel468_OnOff : 475|1@0+ (1,0) [0|1] "" Vector__XXX
 SG_ ICC_RISD_Pixel469_OnOff : 476|1@0+ (1,0) [0|1] "" Vector__XXX
 SG_ ICC_RISD_Pixel470_OnOff : 477|1@0+ (1,0) [0|1] "" Vector__XXX
 SG_ ICC_RISD_Pixel471_OnOff : 478|1@0+ (1,0) [0|1] "" Vector__XXX
 SG_ ICC_RISD_Pixel472_OnOff : 479|1@0+ (1,0) [0|1] "" Vector__XXX
 SG_ ICC_RISD_Pixel473_OnOff : 480|1@0+ (1,0) [0|1] "" Vector__XXX
 SG_ ICC_RISD_Pixel474_OnOff : 481|1@0+ (1,0) [0|1] "" Vector__XXX
 SG_ ICC_RISD_Pixel475_OnOff : 482|1@0+ (1,0) [0|1] "" Vector__XXX
 SG_ ICC_RISD_Pixel476_OnOff : 483|1@0+ (1,0) [0|1] "" Vector__XXX
 SG_ ICC_RISD_Pixel477_OnOff : 484|1@0+ (1,0) [0|1] "" Vector__XXX
 SG_ ICC_RISD_Pixel478_OnOff : 485|1@0+ (1,0) [0|1] "" Vector__XXX
 SG_ ICC_RISD_Pixel479_OnOff : 486|1@0+ (1,0) [0|1] "" Vector__XXX
 SG_ ICC_RISD_Pixel480_OnOff : 487|1@0+ (1,0) [0|1] "" Vector__XXX
 SG_ ICC_RISD_Pixel481_OnOff : 488|1@0+ (1,0) [0|1] "" Vector__XXX
 SG_ ICC_RISD_Pixel482_OnOff : 489|1@0+ (1,0) [0|1] "" Vector__XXX
 SG_ ICC_RISD_Pixel483_OnOff : 490|1@0+ (1,0) [0|1] "" Vector__XXX
 SG_ ICC_RISD_Pixel484_OnOff : 491|1@0+ (1,0) [0|1] "" Vector__XXX
 SG_ ICC_RISD_Pixel485_OnOff : 492|1@0+ (1,0) [0|1] "" Vector__XXX
 SG_ ICC_RISD_Pixel486_OnOff : 493|1@0+ (1,0) [0|1] "" Vector__XXX
 SG_ ICC_RISD_Pixel487_OnOff : 494|1@0+ (1,0) [0|1] "" Vector__XXX
 SG_ ICC_RISD_Pixel488_OnOff : 495|1@0+ (1,0) [0|1] "" Vector__XXX
 SG_ ICC_RISD_Pixel489_OnOff : 496|1@0+ (1,0) [0|1] "" Vector__XXX
 SG_ ICC_RISD_Pixel490_OnOff : 497|1@0+ (1,0) [0|1] "" Vector__XXX
 SG_ ICC_RISD_Pixel491_OnOff : 498|1@0+ (1,0) [0|1] "" Vector__XXX
 SG_ ICC_RISD_Pixel492_OnOff : 499|1@0+ (1,0) [0|1] "" Vector__XXX
 SG_ ICC_RISD_Pixel493_OnOff : 500|1@0+ (1,0) [0|1] "" Vector__XXX
 SG_ ICC_RISD_Pixel494_OnOff : 501|1@0+ (1,0) [0|1] "" Vector__XXX
 SG_ ICC_RISD_Pixel495_OnOff : 502|1@0+ (1,0) [0|1] "" Vector__XXX
 SG_ ICC_RISD_Pixel496_OnOff : 503|1@0+ (1,0) [0|1] "" Vector__XXX
 SG_ ICC_RISD_Pixel497_OnOff : 504|1@0+ (1,0) [0|1] "" Vector__XXX
 SG_ ICC_RISD_Pixel498_OnOff : 505|1@0+ (1,0) [0|1] "" Vector__XXX
 SG_ ICC_RISD_Pixel499_OnOff : 506|1@0+ (1,0) [0|1] "" Vector__XXX
 SG_ ICC_RISD_Pixel500_OnOff : 507|1@0+ (1,0) [0|1] "" Vector__XXX
 SG_ ICC_RISD_Pixel501_OnOff : 508|1@0+ (1,0) [0|1] "" Vector__XXX
 SG_ ICC_RISD_Pixel502_OnOff : 509|1@0+ (1,0) [0|1] "" Vector__XXX
 SG_ ICC_RISD_Pixel503_OnOff : 510|1@0+ (1,0) [0|1] "" Vector__XXX
 SG_ ICC_RISD_Pixel504_OnOff : 511|1@0+ (1,0) [0|1] "" Vector__XXX

BO_ 1366 ICC_DA_45: 64 ICC
 SG_ ReservationSentinelReq_556h : 335|2@0+ (1,0) [0|3] ""  CGW
 SG_ TimeToStopSentinelMinutSet_556h : 333|6@0+ (1,0) [0|63] ""  CGW
 SG_ SentinelMode_SensitivityReq_556h : 326|2@0+ (1,0) [0|3] ""  CGW
 SG_ TimeToStopSentinelHourSet_556h : 324|5@0+ (1,0) [0|31] ""  CGW
 SG_ SentinelModeSwitchReq_556h : 319|2@0+ (1,0) [0|3] ""  CGW
 SG_ TimeToStartSentinelMinutSet_556h : 317|6@0+ (1,0) [0|63] ""  CGW
 SG_ TimeToStartSentinelDaySet_556h : 310|2@0+ (1,0) [0|3] ""  CGW
 SG_ TimeToStartSentinelHourSet_556h : 308|5@0+ (1,0) [0|31] ""  CGW
 SG_ ICC_LKSSettingModSt : 1|2@0+ (1,0) [0|3] ""  CGW
 SG_ ICC_LDWWarnType : 3|2@0+ (1,0) [0|3] ""  CGW
 SG_ ICC_LDWLDPSnvtySet : 5|2@0+ (1,0) [0|3] ""  CGW
 SG_ ICC_ELKSettingSt : 7|2@0+ (1,0) [0|3] ""  CGW
 SG_ ICC_ICAEnableBtnSts : 15|2@0+ (1,0) [0|3] ""  CGW
 SG_ ICC_FCWSettingSt : 13|3@0+ (1,0) [0|7] ""  CGW
 SG_ ICC_AEBSettingSt : 10|2@0+ (1,0) [0|3] ""  CGW
 SG_ ICC_ISLIWarnMod : 8|2@0+ (1,0) [0|3] ""  CGW
 SG_ ICC_Reset : 22|1@0+ (1,0) [0|1] ""  CGW
 SG_ ICC_Customize_buttons : 27|3@0+ (1,0) [0|7] ""  CGW
 SG_ ICC_AVM_TouchEvt : 29|2@0+ (1,0) [0|3] ""  CGW
 SG_ ICC_AVM_BtnPressInputValueX : 39|12@0+ (1,0) [0|4095] "Pixel"  CGW
 SG_ ICC_AVM_BtnPressInputValueY : 43|12@0+ (1,0) [0|4095] "Pixel"  CGW

BO_ 1354 ICC_CFG_46: 32 ICC
 SG_ ICC_SetMsgTotal : 15|16@0+ (1,0) [0|1000] ""  SBOX
 SG_ ICC_SetMSDTotal : 31|16@0+ (1,0) [0|1000] ""  SBOX
 SG_ ICC_SetCallTimeThreshold : 55|16@0+ (1,0) [0|65535] "min"  SBOX
 SG_ ICC_SetTodayCallTimeThreshold : 71|16@0+ (1,0) [0|65535] "min"  SBOX
 SG_ ICC_SetCurretnCallTime : 87|16@0+ (1,0) [0|65535] "min"  SBOX
 SG_ ICC_SetCurretnMsgThreshold : 103|16@0+ (1,0) [0|1000] ""  SBOX
 SG_ ICC_SetMsgTotalThreshold : 119|16@0+ (1,0) [0|1000] ""  SBOX
 SG_ ICC_SetMsdThreshold : 135|16@0+ (1,0) [0|1000] ""  SBOX
 SG_ ICC_SetCurrenMsdCnt : 151|16@0+ (1,0) [0|1000] ""  SBOX
 SG_ ICC_SetCustomMsgThreshold : 167|16@0+ (1,0) [0|1000] ""  SBOX
 SG_ ICC_SetCurrentCustomMsgCnt : 183|16@0+ (1,0) [0|1000] ""  SBOX

BO_ 1356 ICC_CFG_47: 32 ICC
 SG_ ICC_flag : 1|2@0+ (1,0) [0|3] ""  SBOX
 SG_ ICC_ActiveTsp_Req : 3|2@0+ (1,0) [0|3] ""  SBOX
 SG_ ICC_ActiveSim_Req : 5|2@0+ (1,0) [0|3] ""  SBOX
 SG_ ICC_GetMac_req : 6|1@0+ (1,0) [0|1] ""  SBOX
 SG_ ICC_GetIccid_Vin : 7|1@0+ (1,0) [0|1] ""  SBOX
 SG_ ICC_GivePlatformNumber_Flag : 248|1@0+ (1,0) [0|1] ""  SBOX
 SG_ ICC_Platform_Phonenub1 : 11|4@0+ (1,0) [0|9] ""  SBOX
 SG_ ICC_Platform_Phonenub2 : 15|4@0+ (1,0) [0|9] ""  SBOX
 SG_ ICC_Platform_Phonenub3 : 19|4@0+ (1,0) [0|9] ""  SBOX
 SG_ ICC_Platform_Phonenub4 : 23|4@0+ (1,0) [0|9] ""  SBOX
 SG_ ICC_Platform_Phonenub5 : 27|4@0+ (1,0) [0|9] ""  SBOX
 SG_ ICC_Platform_Phonenub6 : 31|4@0+ (1,0) [0|9] ""  SBOX
 SG_ ICC_Platform_Phonenub7 : 35|4@0+ (1,0) [0|9] ""  SBOX
 SG_ ICC_Platform_Phonenub8 : 39|4@0+ (1,0) [0|9] ""  SBOX
 SG_ ICC_Platform_Phonenub9 : 43|4@0+ (1,0) [0|9] ""  SBOX
 SG_ ICC_Platform_Phonenub10 : 47|4@0+ (1,0) [0|9] ""  SBOX
 SG_ ICC_Platform_Phonenub11 : 51|4@0+ (1,0) [0|9] ""  SBOX
 SG_ ICC_Platform_Phonenub12 : 55|4@0+ (1,0) [0|9] ""  SBOX
 SG_ ICC_Platform_Phonenub13 : 59|4@0+ (1,0) [0|9] ""  SBOX
 SG_ ICC_Platform_Phonenub14 : 63|4@0+ (1,0) [0|9] ""  SBOX
 SG_ ICC_Platform_Phonenub15 : 67|4@0+ (1,0) [0|9] ""  SBOX
 SG_ ICC_Platform_Phonenub16 : 71|4@0+ (1,0) [0|9] ""  SBOX
 SG_ ICC_Platform_Phonenub17 : 75|4@0+ (1,0) [0|9] ""  SBOX
 SG_ ICC_Platform_Phonenub18 : 79|4@0+ (1,0) [0|9] ""  SBOX
 SG_ ICC_Platform_Phonenub19 : 83|4@0+ (1,0) [0|9] ""  SBOX
 SG_ ICC_Platform_Phonenub20 : 87|4@0+ (1,0) [0|9] ""  SBOX
 SG_ ICC_Mac_Flag : 249|1@0+ (1,0) [0|1] ""  SBOX
 SG_ ICC_Mac0 : 95|8@0+ (1,0) [0|255] ""  SBOX
 SG_ ICC_Mac1 : 103|8@0+ (1,0) [0|255] ""  SBOX
 SG_ ICC_Mac2 : 111|8@0+ (1,0) [0|255] ""  SBOX
 SG_ ICC_Mac3 : 119|8@0+ (1,0) [0|255] ""  SBOX
 SG_ ICC_Mac4 : 127|8@0+ (1,0) [0|255] ""  SBOX
 SG_ ICC_Mac5 : 135|8@0+ (1,0) [0|255] ""  SBOX

BO_ 1453 ICC_BD_49: 48 ICC
 SG_ ICC_CrossBorderMode : 33|2@0+ (1,0) [0|3] ""  FLZCU_HCU_IC
 SG_ ICC_BedStatus : 39|3@0+ (1,0) [0|7] ""  FRZCU,HCU_IC,FLZCU_HCU_IC,FLZCU_IC
 SG_ ICC_MemAttributeFL : 23|3@0+ (1,0) [0|7] ""  FLZCU_HCU_IC
 SG_ ICC_MemAttributeFR : 20|3@0+ (1,0) [0|7] ""  FLZCU_HCU_IC
 SG_ ICC_MemAttributeRL : 31|3@0+ (1,0) [0|7] ""  FLZCU_HCU_IC
 SG_ ICC_MemAttributeRR : 28|3@0+ (1,0) [0|7] ""  FLZCU_HCU_IC

BO_ 1380 ICC_BD_50: 32 ICC
 SG_ ICC_3rd_FRSeatBackAgtargetCmd : 158|7@0+ (1,-1) [-1|100] "%"  BBCM
 SG_ ICC_3rd_FLSeatBackAgtargetCmd : 150|7@0+ (1,-1) [-1|100] "%"  BBCM
 SG_ ICC_2nd_FRSeatLegSpprttargetCmd : 118|7@0+ (1,-1) [-1|100] "%"  BBCM
 SG_ ICC_2nd_FRSeatBackAgtargetCmd : 110|7@0+ (1,-1) [-1|100] "%"  BBCM
 SG_ ICC_2nd_FRSeatLvltargetCmd : 102|7@0+ (1,-1) [-1|100] "%"  BBCM
 SG_ ICC_2nd_FLSeatBackAgtargetCmd : 94|7@0+ (1,-1) [-1|100] "%"  BBCM
 SG_ ICC_2nd_FLSeatLvltargetCmd : 86|7@0+ (1,-1) [-1|100] "%"  BBCM
 SG_ ICC_QueenSeatSwitch : 61|2@0+ (1,0) [0|3] ""  BBCM
 SG_ ICC_3rd_FRFrontFlipSwitch : 59|2@0+ (1,0) [0|3] ""  BBCM
 SG_ ICC_3rd_FREnjoyableSeatSwitch : 57|2@0+ (1,0) [0|3] ""  BBCM
 SG_ ICC_3rd_FLFrontFlipSwitch : 55|2@0+ (1,0) [0|3] ""  BBCM
 SG_ ICC_3rd_FLEnjoyableSeatSwitch : 53|2@0+ (1,0) [0|3] ""  BBCM
 SG_ ICC_2nd_FREnjoyableSeatSwitch : 51|2@0+ (1,0) [0|3] ""  BBCM
 SG_ ICC_FRSeatliedownCmd2 : 49|2@0+ (1,0) [0|3] ""  FLZCU_HCU_IC,FLZCU_IC
 SG_ ICC_FLSeatHeatLvlCmd2 : 19|4@0+ (1,0) [0|15] ""  FLZCU_HCU_IC,FLZCU_IC
 SG_ ICC_RLSeatHeatLvlCmd2 : 23|4@0+ (1,0) [0|15] ""  FLZCU_HCU_IC,FLZCU_IC
 SG_ ICC_FLSeatVentLvlCmd2 : 27|4@0+ (1,0) [0|15] ""  FLZCU_HCU_IC,FLZCU_IC
 SG_ ICC_RLSeatVentLvlCmd2 : 31|4@0+ (1,0) [0|15] ""  FLZCU_HCU_IC,FLZCU_IC
 SG_ ICC_FRSeatHeatLvlCmd2 : 35|4@0+ (1,0) [0|15] ""  FRZCU
 SG_ ICC_RRSeatHeatLvlCmd2 : 39|4@0+ (1,0) [0|15] ""  FRZCU
 SG_ ICC_FRSeatVentLvlCmd2 : 43|4@0+ (1,0) [0|15] ""  FRZCU
 SG_ ICC_RRSeatVentLvlCmd2 : 47|4@0+ (1,0) [0|15] ""  FRZCU

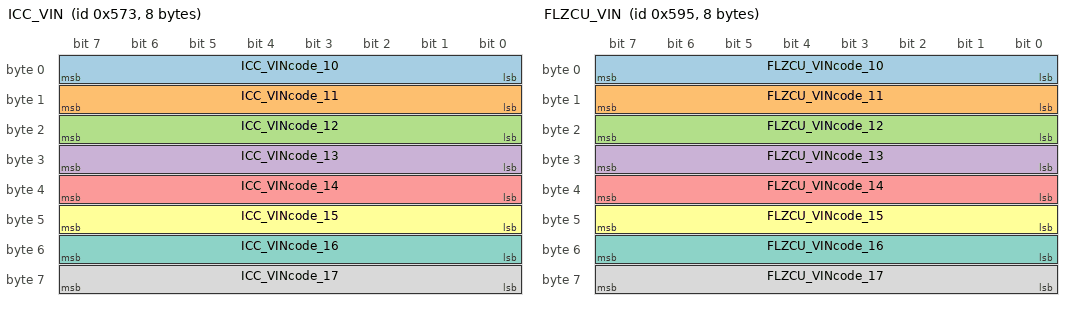
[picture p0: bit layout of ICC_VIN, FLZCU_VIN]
BO_ 1395 ICC_VIN: 8 ICC
 SG_ ICC_VINcode_10 : 7|8@0+ (1,0) [0|127] ""  FLZCU_HCU_IC,FLZCU_IC
 SG_ ICC_VINcode_11 : 15|8@0+ (1,0) [0|127] ""  FLZCU_HCU_IC,FLZCU_IC
 SG_ ICC_VINcode_12 : 23|8@0+ (1,0) [0|127] ""  FLZCU_HCU_IC,FLZCU_IC
 SG_ ICC_VINcode_13 : 31|8@0+ (1,0) [0|127] ""  FLZCU_HCU_IC,FLZCU_IC
 SG_ ICC_VINcode_14 : 39|8@0+ (1,0) [0|127] ""  FLZCU_HCU_IC,FLZCU_IC
 SG_ ICC_VINcode_15 : 47|8@0+ (1,0) [0|127] ""  FLZCU_HCU_IC,FLZCU_IC
 SG_ ICC_VINcode_16 : 55|8@0+ (1,0) [0|127] ""  FLZCU_HCU_IC,FLZCU_IC
 SG_ ICC_VINcode_17 : 63|8@0+ (1,0) [0|127] ""  FLZCU_HCU_IC,FLZCU_IC

BO_ 1116 ICC_IMMO_11: 8 ICC
 SG_ ICC_Auth_IMMO : 7|64@0+ (1,0) [0|1.84467440737096E+019] ""  CGW

BO_ 1151 VCC_IMMO_12: 8 ICC
 SG_ VCC_Teach_IMMO : 7|64@0+ (1,0) [0|1.84467440737096E+019] ""  CGW

BO_ 1312 ICC_RemoteDiag: 32 ICC
 SG_ ICC_TotalFaultNum : 7|8@0+ (1,0) [0|255] ""  TBOX
 SG_ ICC_FrameIndex : 12|5@0+ (1,0) [0|31] ""  TBOX
 SG_ ICC_SupplierNum : 15|3@0+ (1,0) [0|7] ""  TBOX
 SG_ ICC_FaultNum1 : 23|12@0+ (1,0) [0|4095] ""  TBOX
 SG_ ICC_FaultNum2 : 27|12@0+ (1,0) [0|4095] ""  TBOX
 SG_ ICC_FaultNum3 : 47|12@0+ (1,0) [0|4095] ""  TBOX
 SG_ ICC_FaultNum4 : 51|12@0+ (1,0) [0|4095] ""  TBOX
 SG_ ICC_FaultNum5 : 71|12@0+ (1,0) [0|4095] ""  TBOX
 SG_ ICC_FaultNum6 : 75|12@0+ (1,0) [0|4095] ""  TBOX
 SG_ ICC_FaultNum7 : 95|12@0+ (1,0) [0|4095] ""  TBOX
 SG_ ICC_FaultNum8 : 99|12@0+ (1,0) [0|4095] ""  TBOX
 SG_ ICC_FaultNum9 : 119|12@0+ (1,0) [0|4095] ""  TBOX
 SG_ ICC_FaultNum10 : 123|12@0+ (1,0) [0|4095] ""  TBOX
 SG_ ICC_FaultNum11 : 143|12@0+ (1,0) [0|4095] ""  TBOX
 SG_ ICC_FaultNum12 : 147|12@0+ (1,0) [0|4095] ""  TBOX
 SG_ ICC_FaultNum13 : 167|12@0+ (1,0) [0|4095] ""  TBOX
 SG_ ICC_FaultNum14 : 171|12@0+ (1,0) [0|4095] ""  TBOX
 SG_ ICC_FaultNum15 : 191|12@0+ (1,0) [0|4095] ""  TBOX
 SG_ ICC_FaultNum16 : 195|12@0+ (1,0) [0|4095] ""  TBOX
 SG_ ICC_FaultNum17 : 215|12@0+ (1,0) [0|4095] ""  TBOX
 SG_ ICC_FaultNum18 : 219|12@0+ (1,0) [0|4095] ""  TBOX
 SG_ ICC_FaultNum19 : 239|12@0+ (1,0) [0|4095] ""  TBOX
 SG_ ICC_FaultNum20 : 243|12@0+ (1,0) [0|4095] ""  TBOX

BO_ 1560 NMm_ICC: 8 ICC
 SG_ srcNodeID_ICC : 7|8@0+ (1,0) [0|255] "" Vector__XXX
 SG_ RMR_ICC : 8|1@0+ (1,0) [0|1] "" Vector__XXX
 SG_ NMm_ICC_Reserved1 : 15|7@0+ (1,0) [0|127] "" Vector__XXX
 SG_ ICC_Wakeup_Poweron : 16|1@0+ (1,0) [0|1] "" Vector__XXX
 SG_ ICC_Wakeup_NM : 17|1@0+ (1,0) [0|1] "" Vector__XXX
 SG_ ICC_Wakeup_Diag : 18|1@0+ (1,0) [0|1] "" Vector__XXX
 SG_ ICC_Wakeup_PowerComfortable : 20|1@0+ (1,0) [0|1] "" Vector__XXX
 SG_ ICC_Wakeup_HUD : 23|1@0+ (1,0) [0|1] "" Vector__XXX
 SG_ ICC_Wakeup_EAMP : 24|1@0+ (1,0) [0|1] "" Vector__XXX
 SG_ ICC_Awake_Poweron : 40|1@0+ (1,0) [0|1] "" Vector__XXX
 SG_ ICC_Awake_NM : 41|1@0+ (1,0) [0|1] "" Vector__XXX
 SG_ ICC_Awake_DiagETH : 42|1@0+ (1,0) [0|1] "" Vector__XXX
 SG_ ICC_Awake_PowerComfortable : 45|1@0+ (1,0) [0|1] "" Vector__XXX
 SG_ ICC_Awake_SentinelMode : 46|1@0+ (1,0) [0|1] "" Vector__XXX
 SG_ ICC_Awake_PetMode : 47|1@0+ (1,0) [0|1] "" Vector__XXX
 SG_ ICC_Awake_HUD : 48|1@0+ (1,0) [0|1] "" Vector__XXX
 SG_ ICC_Awake_EAMP : 49|1@0+ (1,0) [0|1] "" Vector__XXX
 SG_ ICC_Awake_FreezerFunction : 50|1@0+ (1,0) [0|1] "" Vector__XXX
 SG_ ICC_Awake_PowerOffDelay : 51|1@0+ (1,0) [0|1] "" Vector__XXX

BO_ 859 FLZCU_5: 8 FLZCU_HCU_IC
 SG_ RearDefrostSts : 21|1@0+ (1,0) [0|1] ""  ICC

BO_ 1181 FLZCU_9: 8 FLZCU_HCU_IC
 SG_ FLZCU_9_PowerMode : 17|2@0+ (1,0) [0|3] ""  ICC,DVR,EPC,BBCM,EAMP,CMSM
 SG_ FLZCU_9_ArmingSts : 25|2@0+ (1,0) [0|3] ""  ICC,EPC,BBCM,CMSM

BO_ 1030 FLZCU_12: 16 FLZCU_HCU_IC
 SG_ RearViewFoldSts : 58|2@0+ (1,0) [0|3] ""  ICC
 SG_ FLZCU_AlrmSts : 61|3@0+ (1,0) [0|7] ""  ICC,EPC,BBCM
 SG_ FLZCU_SteeringMode : 82|2@0+ (1,0) [0|3] ""  ICC
 SG_ FLZCU_SuspensionDamping : 92|2@0+ (1,0) [0|3] ""  ICC
 SG_ FLZCU_SuspensionHeight : 95|3@0+ (1,0) [0|7] ""  ICC
 SG_ FLZCU_OBDDiagOccupy : 105|2@0+ (1,0) [0|3] ""  ICC

BO_ 1071 FLZCU_15: 48 FLZCU_HCU_IC
 SG_ FLZCU_AutoFoldSts : 18|1@0+ (1,0) [0|1] ""  ICC
 SG_ FLZCU_AutolockSts : 19|1@0+ (1,0) [0|1] ""  ICC
 SG_ FLZCU_FGHeat_Req_CmdFeedback : 20|1@0+ (1,0) [0|1] ""  ICC
 SG_ FLZCU_WindowInhibitSts : 21|1@0+ (1,0) [0|1] ""  ICC
 SG_ FLZCU_AutoReadLightSts : 22|1@0+ (1,0) [0|1] ""  ICC
 SG_ FLZCU_HeatingSW : 23|1@0+ (1,0) [0|1] ""  ICC
 SG_ FLZCU_AutoHeatingFb : 24|1@0+ (1,0) [0|1] ""  ICC
 SG_ FLZCU_SteerNeedMemory : 25|1@0+ (1,0) [0|1] ""  ICC
 SG_ FLZCU_LowBeamFaults : 26|1@0+ (1,0) [0|1] ""  ICC
 SG_ FLZCU_RearNeedMemory : 27|1@0+ (1,0) [0|1] ""  ICC
 SG_ FLZCU_BrkLightFaults : 28|1@0+ (1,0) [0|1] ""  ICC
 SG_ FLZCU_TurnLiSwtSts : 31|3@0+ (1,0) [0|7] ""  ICC
 SG_ FLZCU_FLHandleFoldedStatus : 33|2@0+ (1,0) [0|3] ""  ICC
 SG_ FLZCU_RLHandleFoldedStatus : 35|2@0+ (1,0) [0|3] ""  ICC
 SG_ FLZCU_FRHandleFoldedStatus : 37|2@0+ (1,0) [0|3] ""  ICC
 SG_ FLZCU_RRHandleFoldedStatus : 39|2@0+ (1,0) [0|3] ""  ICC
 SG_ FLZCU_RvsExtMirrFbSts : 41|2@0+ (1,0) [0|3] ""  ICC
 SG_ FLZCU_LightMainSwitchSts : 44|3@0+ (1,0) [0|7] ""  ICC
 SG_ FLZCU_BeamDelaySts : 47|3@0+ (1,0) [0|7] ""  ICC
 SG_ FLZCU_LowBeamHighSts : 50|3@0+ (1,0) [0|7] ""  ICC
 SG_ FLZCU_WipeSensitivitySts : 53|3@0+ (1,0) [0|7] ""  ICC
 SG_ FLZCU_WipeMaintenanceSWSts : 55|2@0+ (1,0) [0|3] ""  ICC
 SG_ FLZCU_HiBeamSwtSts : 57|2@0+ (1,0) [0|3] ""  ICC
 SG_ FLZCU_ImmoRequest : 60|3@0+ (1,0) [0|7] ""  ICC
 SG_ FLZCU_AlarmWarnSetSW : 63|3@0+ (1,0) [0|7] ""  ICC
 SG_ FLZCU_CleanModeStatus : 81|2@0+ (1,0) [0|3] ""  ICC,EPC
 SG_ FLZCU_FLReleaseLockSts : 84|3@0+ (1,0) [0|7] ""  ICC
 SG_ FLZCU_RearFogLightSts : 85|1@0+ (1,0) [0|1] ""  ICC,DVR
 SG_ FLZCU_FRFoglightSts : 86|1@0+ (1,0) [0|1] ""  ICC
 SG_ FLZCU_FLFoglightSts : 87|1@0+ (1,0) [0|1] ""  ICC
 SG_ FLZCU_RearFogLightFaults : 88|1@0+ (1,0) [0|1] ""  ICC
 SG_ FLZCU_HighBeamFaults : 89|1@0+ (1,0) [0|1] ""  ICC
 SG_ FLZCU_HighBeamSts : 90|1@0+ (1,0) [0|1] ""  ICC,DVR
 SG_ FLZCU_LowBeamSts : 91|1@0+ (1,0) [0|1] ""  ICC,DVR
 SG_ FLZCU_ParkUnlockEnableFb : 92|1@0+ (1,0) [0|1] ""  ICC
 SG_ FLZCU_RLReleaseLockSts : 95|3@0+ (1,0) [0|7] ""  ICC
 SG_ FLZCU_EasyEntryExitFb : 97|2@0+ (1,0) [0|3] ""  ICC
 SG_ FLZCU_EmgyLiSwtSts : 98|1@0+ (1,0) [0|1] ""  ICC
 SG_ FLZCU_HMASwSts : 99|1@0+ (1,0) [0|1] ""  ICC
 SG_ FLZCU_DaytimeLight : 101|2@0+ (1,0) [0|3] ""  ICC
 SG_ FLZCU_FGHeatFaults : 102|1@0+ (1,0) [0|1] ""  ICC
 SG_ FLZCU_ParkLightFaults : 103|1@0+ (1,0) [0|1] ""  ICC
 SG_ FLZCU_LbatipVehPwrMod : 106|1@0+ (1,0) [0|1] ""  ICC
 SG_ FLZCU_LVPowICDsp : 111|3@0+ (1,0) [0|7] ""  ICC
 SG_ FLZCU_LockCarWinCloseFb : 113|2@0+ (1,0) [0|3] ""  ICC
 SG_ FLZCU_BrkLightSts : 115|2@0+ (1,0) [0|3] ""  ICC
 SG_ FLZCU_ReverseLightSts : 117|2@0+ (1,0) [0|3] ""  ICC
 SG_ FLZCU_LowWashLqdWarning : 119|2@0+ (1,0) [0|3] ""  ICC
 SG_ FLZCU_SteerWheelHeatingFb : 123|3@0+ (1,0) [0|7] ""  ICC
 SG_ FLZCU_FrontFogLightSts : 124|1@0+ (1,0) [0|1] ""  ICC
 SG_ FLZCU_NapAreaFb : 145|2@0+ (1,0) [0|3] ""  ICC
 SG_ FLZCU_NapTimeFb : 151|6@0+ (1,0) [0|60] "min"  ICC
 SG_ FLZCU_NapAlarmStatus : 153|2@0+ (1,0) [0|3] ""  ICC
 SG_ FLZCU_NapFailCause : 157|4@0+ (1,0) [0|15] ""  ICC
 SG_ FLZCU_NapStatusFb : 159|2@0+ (1,0) [0|3] ""  ICC,BBCM
 SG_ FLZCU_CleanModeFailCause : 163|2@0+ (1,0) [0|3] ""  ICC
 SG_ FLZCU_NapClosePrompt : 167|2@0+ (1,0) [0|3] ""  ICC
 SG_ FLZCU_AutoWipingInhibit : 175|2@0+ (1,0) [0|3] ""  ICC
 SG_ FLZCU_RLWinSts : 252|3@0+ (1,0) [0|7] ""  ICC
 SG_ FLZCU_FLWinSts : 255|3@0+ (1,0) [0|7] ""  ICC
 SG_ FLZCU_DaytimeLightFaults : 273|2@0+ (1,0) [0|1] ""  ICC
 SG_ FLZCU_FrontFogLightFaults : 275|2@0+ (1,0) [0|1] ""  ICC
 SG_ FLZCU_HomeLinkWelLightSetSts : 277|2@0+ (1,0) [0|3] ""  ICC
 SG_ FLZCU_HomeLinkArmHornSetSts : 279|2@0+ (1,0) [0|3] ""  ICC
 SG_ FLZCU_WelcomeOpenStas : 287|2@0+ (1,0) [0|1] ""  ICC
 SG_ FLZCU_WALOpenStas : 285|2@0+ (1,0) [0|1] ""  ICC
 SG_ FLZCU_UIROpenStas : 283|2@0+ (1,0) [0|1] ""  ICC
 SG_ FLZCU_ExtLiSwtClsSts : 359|2@0+ (1,0) [0|3] ""  ICC

BO_ 1409 FLZCU_25: 8 FLZCU_HCU_IC
 SG_ FLZCU_EVodometerbackup : 47|24@0+ (0.1,0) [0|999999.9] ""  ICC
 SG_ FLZCU_Totalodometerbackup : 23|24@0+ (0.1,0) [0|999999.9] "km"  ICC

BO_ 1211 FLZCU_26: 32 FLZCU_HCU_IC
 SG_ FLZCU_DriverSeatMovFailCause : 87|4@0+ (1,0) [0|15] ""  ICC
 SG_ FLZCU_FLSeatHeiFb : 23|7@0+ (1,-1) [-1|100] "%"  ICC,BBCM
 SG_ FLZCU_FLSeatLvlFb : 31|7@0+ (1,-1) [-1|100] "%"  ICC,BBCM
 SG_ FLZCU_FLSeatBackAgFb : 39|7@0+ (1,-1) [-1|100] "%"  ICC,BBCM
 SG_ FLZCU_FLSeatCushFb : 47|7@0+ (1,-1) [-1|100] "%"  ICC,BBCM
 SG_ FLZCU_FLSeatLegSpprtFb : 55|7@0+ (1,-1) [-1|100] "%"  ICC
 SG_ FLZCU_SeatNeedMemory : 63|2@0+ (1,0) [0|3] ""  ICC
 SG_ FLZCU_MemoryFb : 61|2@0+ (1,0) [0|3] ""  ICC
 SG_ FLZCU_RecoverFb : 59|2@0+ (1,0) [0|3] ""  ICC

BO_ 1429 FLZCU_VIN: 8 FLZCU_HCU_IC
 SG_ FLZCU_VINcode_10 : 7|8@0+ (1,0) [0|127] ""  ICC
 SG_ FLZCU_VINcode_11 : 15|8@0+ (1,0) [0|127] ""  ICC
 SG_ FLZCU_VINcode_12 : 23|8@0+ (1,0) [0|127] ""  ICC
 SG_ FLZCU_VINcode_13 : 31|8@0+ (1,0) [0|127] ""  ICC
 SG_ FLZCU_VINcode_14 : 39|8@0+ (1,0) [0|127] ""  ICC
 SG_ FLZCU_VINcode_15 : 47|8@0+ (1,0) [0|127] ""  ICC
 SG_ FLZCU_VINcode_16 : 55|8@0+ (1,0) [0|127] ""  ICC
 SG_ FLZCU_VINcode_17 : 63|8@0+ (1,0) [0|127] ""  ICC

BO_TX_BU_ 859 : FLZCU_HCU_IC,FLZCU_IC,FLZCU_Signal_IC;
BO_TX_BU_ 1181 : FLZCU_HCU_IC,FLZCU_IC,FLZCU_Signal_IC;
BO_TX_BU_ 1030 : FLZCU_HCU_IC,FLZCU_IC,HCU_IC;
BO_TX_BU_ 1071 : FLZCU_HCU_IC,FLZCU_IC;
BO_TX_BU_ 1409 : FLZCU_HCU_IC,FLZCU_IC;
BO_TX_BU_ 1211 : FLZCU_HCU_IC,FLZCU_IC;
BO_TX_BU_ 1429 : FLZCU_HCU_IC,FLZCU_IC;
CM_ SG_ 1364 ICC_RISD_RollingCounter "顺序计数器，确保图片数据按预期顺序发送、接收。";
CM_ SG_ 1364 ICC_RISD_Pixel1_OnOff "对应像素点的亮灭";
CM_ SG_ 1364 ICC_RISD_Pixel2_OnOff "对应像素点的亮灭";
CM_ SG_ 1364 ICC_RISD_Pixel3_OnOff "对应像素点的亮灭";
CM_ SG_ 1364 ICC_RISD_Pixel4_OnOff "对应像素点的亮灭";
CM_ SG_ 1364 ICC_RISD_Pixel5_OnOff "对应像素点的亮灭";
CM_ SG_ 1364 ICC_RISD_Pixel6_OnOff "对应像素点的亮灭";
CM_ SG_ 1364 ICC_RISD_Pixel7_OnOff "对应像素点的亮灭";
CM_ SG_ 1364 ICC_RISD_Pixel8_OnOff "对应像素点的亮灭";
CM_ SG_ 1364 ICC_RISD_Pixel9_OnOff "对应像素点的亮灭";
CM_ SG_ 1364 ICC_RISD_Pixel10_OnOff "对应像素点的亮灭";
CM_ SG_ 1364 ICC_RISD_Pixel11_OnOff "对应像素点的亮灭";
CM_ SG_ 1364 ICC_RISD_Pixel12_OnOff "对应像素点的亮灭";
CM_ SG_ 1364 ICC_RISD_Pixel13_OnOff "对应像素点的亮灭";
CM_ SG_ 1364 ICC_RISD_Pixel14_OnOff "对应像素点的亮灭";
CM_ SG_ 1364 ICC_RISD_Pixel15_OnOff "对应像素点的亮灭";
CM_ SG_ 1364 ICC_RISD_Pixel16_OnOff "对应像素点的亮灭";
CM_ SG_ 1364 ICC_RISD_Pixel17_OnOff "对应像素点的亮灭";
CM_ SG_ 1364 ICC_RISD_Pixel18_OnOff "对应像素点的亮灭";
CM_ SG_ 1364 ICC_RISD_Pixel19_OnOff "对应像素点的亮灭";
CM_ SG_ 1364 ICC_RISD_Pixel20_OnOff "对应像素点的亮灭";
CM_ SG_ 1364 ICC_RISD_Pixel21_OnOff "对应像素点的亮灭";
CM_ SG_ 1364 ICC_RISD_Pixel22_OnOff "对应像素点的亮灭";
CM_ SG_ 1364 ICC_RISD_Pixel23_OnOff "对应像素点的亮灭";
CM_ SG_ 1364 ICC_RISD_Pixel24_OnOff "对应像素点的亮灭";
CM_ SG_ 1364 ICC_RISD_Pixel25_OnOff "对应像素点的亮灭";
CM_ SG_ 1364 ICC_RISD_Pixel26_OnOff "对应像素点的亮灭";
CM_ SG_ 1364 ICC_RISD_Pixel27_OnOff "对应像素点的亮灭";
CM_ SG_ 1364 ICC_RISD_Pixel28_OnOff "对应像素点的亮灭";
CM_ SG_ 1364 ICC_RISD_Pixel29_OnOff "对应像素点的亮灭";
CM_ SG_ 1364 ICC_RISD_Pixel30_OnOff "对应像素点的亮灭";
CM_ SG_ 1364 ICC_RISD_Pixel31_OnOff "对应像素点的亮灭";
CM_ SG_ 1364 ICC_RISD_Pixel32_OnOff "对应像素点的亮灭";
CM_ SG_ 1364 ICC_RISD_Pixel33_OnOff "对应像素点的亮灭";
CM_ SG_ 1364 ICC_RISD_Pixel34_OnOff "对应像素点的亮灭";
CM_ SG_ 1364 ICC_RISD_Pixel35_OnOff "对应像素点的亮灭";
CM_ SG_ 1364 ICC_RISD_Pixel36_OnOff "对应像素点的亮灭";
CM_ SG_ 1364 ICC_RISD_Pixel37_OnOff "对应像素点的亮灭";
CM_ SG_ 1364 ICC_RISD_Pixel38_OnOff "对应像素点的亮灭";
CM_ SG_ 1364 ICC_RISD_Pixel39_OnOff "对应像素点的亮灭";
CM_ SG_ 1364 ICC_RISD_Pixel40_OnOff "对应像素点的亮灭";
CM_ SG_ 1364 ICC_RISD_Pixel41_OnOff "对应像素点的亮灭";
CM_ SG_ 1364 ICC_RISD_Pixel42_OnOff "对应像素点的亮灭";
CM_ SG_ 1364 ICC_RISD_Pixel43_OnOff "对应像素点的亮灭";
CM_ SG_ 1364 ICC_RISD_Pixel44_OnOff "对应像素点的亮灭";
CM_ SG_ 1364 ICC_RISD_Pixel45_OnOff "对应像素点的亮灭";
CM_ SG_ 1364 ICC_RISD_Pixel46_OnOff "对应像素点的亮灭";
CM_ SG_ 1364 ICC_RISD_Pixel47_OnOff "对应像素点的亮灭";
CM_ SG_ 1364 ICC_RISD_Pixel48_OnOff "对应像素点的亮灭";
CM_ SG_ 1364 ICC_RISD_Pixel49_OnOff "对应像素点的亮灭";
CM_ SG_ 1364 ICC_RISD_Pixel50_OnOff "对应像素点的亮灭";
CM_ SG_ 1364 ICC_RISD_Pixel51_OnOff "对应像素点的亮灭";
CM_ SG_ 1364 ICC_RISD_Pixel52_OnOff "对应像素点的亮灭";
CM_ SG_ 1364 ICC_RISD_Pixel53_OnOff "对应像素点的亮灭";
CM_ SG_ 1364 ICC_RISD_Pixel54_OnOff "对应像素点的亮灭";
CM_ SG_ 1364 ICC_RISD_Pixel55_OnOff "对应像素点的亮灭";
CM_ SG_ 1364 ICC_RISD_Pixel56_OnOff "对应像素点的亮灭";
CM_ SG_ 1364 ICC_RISD_Pixel57_OnOff "对应像素点的亮灭";
CM_ SG_ 1364 ICC_RISD_Pixel58_OnOff "对应像素点的亮灭";
CM_ SG_ 1364 ICC_RISD_Pixel59_OnOff "对应像素点的亮灭";
CM_ SG_ 1364 ICC_RISD_Pixel60_OnOff "对应像素点的亮灭";
CM_ SG_ 1364 ICC_RISD_Pixel61_OnOff "对应像素点的亮灭";
CM_ SG_ 1364 ICC_RISD_Pixel62_OnOff "对应像素点的亮灭";
CM_ SG_ 1364 ICC_RISD_Pixel63_OnOff "对应像素点的亮灭";
CM_ SG_ 1364 ICC_RISD_Pixel64_OnOff "对应像素点的亮灭";
CM_ SG_ 1364 ICC_RISD_Pixel65_OnOff "对应像素点的亮灭";
CM_ SG_ 1364 ICC_RISD_Pixel66_OnOff "对应像素点的亮灭";
CM_ SG_ 1364 ICC_RISD_Pixel67_OnOff "对应像素点的亮灭";
CM_ SG_ 1364 ICC_RISD_Pixel68_OnOff "对应像素点的亮灭";
CM_ SG_ 1364 ICC_RISD_Pixel69_OnOff "对应像素点的亮灭";
CM_ SG_ 1364 ICC_RISD_Pixel70_OnOff "对应像素点的亮灭";
CM_ SG_ 1364 ICC_RISD_Pixel71_OnOff "对应像素点的亮灭";
CM_ SG_ 1364 ICC_RISD_Pixel72_OnOff "对应像素点的亮灭";
CM_ SG_ 1364 ICC_RISD_Pixel73_OnOff "对应像素点的亮灭";
CM_ SG_ 1364 ICC_RISD_Pixel74_OnOff "对应像素点的亮灭";
CM_ SG_ 1364 ICC_RISD_Pixel75_OnOff "对应像素点的亮灭";
CM_ SG_ 1364 ICC_RISD_Pixel76_OnOff "对应像素点的亮灭";
CM_ SG_ 1364 ICC_RISD_Pixel77_OnOff "对应像素点的亮灭";
CM_ SG_ 1364 ICC_RISD_Pixel78_OnOff "对应像素点的亮灭";
CM_ SG_ 1364 ICC_RISD_Pixel79_OnOff "对应像素点的亮灭";
CM_ SG_ 1364 ICC_RISD_Pixel80_OnOff "对应像素点的亮灭";
CM_ SG_ 1364 ICC_RISD_Pixel81_OnOff "对应像素点的亮灭";
CM_ SG_ 1364 ICC_RISD_Pixel82_OnOff "对应像素点的亮灭";
CM_ SG_ 1364 ICC_RISD_Pixel83_OnOff "对应像素点的亮灭";
CM_ SG_ 1364 ICC_RISD_Pixel84_OnOff "对应像素点的亮灭";
CM_ SG_ 1364 ICC_RISD_Pixel85_OnOff "对应像素点的亮灭";
CM_ SG_ 1364 ICC_RISD_Pixel86_OnOff "对应像素点的亮灭";
CM_ SG_ 1364 ICC_RISD_Pixel87_OnOff "对应像素点的亮灭";
CM_ SG_ 1364 ICC_RISD_Pixel88_OnOff "对应像素点的亮灭";
CM_ SG_ 1364 ICC_RISD_Pixel89_OnOff "对应像素点的亮灭";
CM_ SG_ 1364 ICC_RISD_Pixel90_OnOff "对应像素点的亮灭";
CM_ SG_ 1364 ICC_RISD_Pixel91_OnOff "对应像素点的亮灭";
CM_ SG_ 1364 ICC_RISD_Pixel92_OnOff "对应像素点的亮灭";
CM_ SG_ 1364 ICC_RISD_Pixel93_OnOff "对应像素点的亮灭";
CM_ SG_ 1364 ICC_RISD_Pixel94_OnOff "对应像素点的亮灭";
CM_ SG_ 1364 ICC_RISD_Pixel95_OnOff "对应像素点的亮灭";
CM_ SG_ 1364 ICC_RISD_Pixel96_OnOff "对应像素点的亮灭";
CM_ SG_ 1364 ICC_RISD_Pixel97_OnOff "对应像素点的亮灭";
CM_ SG_ 1364 ICC_RISD_Pixel98_OnOff "对应像素点的亮灭";
CM_ SG_ 1364 ICC_RISD_Pixel99_OnOff "对应像素点的亮灭";
CM_ SG_ 1364 ICC_RISD_Pixel100_OnOff "对应像素点的亮灭";
CM_ SG_ 1364 ICC_RISD_Pixel101_OnOff "对应像素点的亮灭";
CM_ SG_ 1364 ICC_RISD_Pixel102_OnOff "对应像素点的亮灭";
CM_ SG_ 1364 ICC_RISD_Pixel103_OnOff "对应像素点的亮灭";
CM_ SG_ 1364 ICC_RISD_Pixel104_OnOff "对应像素点的亮灭";
CM_ SG_ 1364 ICC_RISD_Pixel105_OnOff "对应像素点的亮灭";
CM_ SG_ 1364 ICC_RISD_Pixel106_OnOff "对应像素点的亮灭";
CM_ SG_ 1364 ICC_RISD_Pixel107_OnOff "对应像素点的亮灭";
CM_ SG_ 1364 ICC_RISD_Pixel108_OnOff "对应像素点的亮灭";
CM_ SG_ 1364 ICC_RISD_Pixel109_OnOff "对应像素点的亮灭";
CM_ SG_ 1364 ICC_RISD_Pixel110_OnOff "对应像素点的亮灭";
CM_ SG_ 1364 ICC_RISD_Pixel111_OnOff "对应像素点的亮灭";
CM_ SG_ 1364 ICC_RISD_Pixel112_OnOff "对应像素点的亮灭";
CM_ SG_ 1364 ICC_RISD_Pixel113_OnOff "对应像素点的亮灭";
CM_ SG_ 1364 ICC_RISD_Pixel114_OnOff "对应像素点的亮灭";
CM_ SG_ 1364 ICC_RISD_Pixel115_OnOff "对应像素点的亮灭";
CM_ SG_ 1364 ICC_RISD_Pixel116_OnOff "对应像素点的亮灭";
CM_ SG_ 1364 ICC_RISD_Pixel117_OnOff "对应像素点的亮灭";
CM_ SG_ 1364 ICC_RISD_Pixel118_OnOff "对应像素点的亮灭";
CM_ SG_ 1364 ICC_RISD_Pixel119_OnOff "对应像素点的亮灭";
CM_ SG_ 1364 ICC_RISD_Pixel120_OnOff "对应像素点的亮灭";
CM_ SG_ 1364 ICC_RISD_Pixel121_OnOff "对应像素点的亮灭";
CM_ SG_ 1364 ICC_RISD_Pixel122_OnOff "对应像素点的亮灭";
CM_ SG_ 1364 ICC_RISD_Pixel123_OnOff "对应像素点的亮灭";
CM_ SG_ 1364 ICC_RISD_Pixel124_OnOff "对应像素点的亮灭";
CM_ SG_ 1364 ICC_RISD_Pixel125_OnOff "对应像素点的亮灭";
CM_ SG_ 1364 ICC_RISD_Pixel126_OnOff "对应像素点的亮灭";
CM_ SG_ 1364 ICC_RISD_Pixel127_OnOff "对应像素点的亮灭";
CM_ SG_ 1364 ICC_RISD_Pixel128_OnOff "对应像素点的亮灭";
CM_ SG_ 1364 ICC_RISD_Pixel129_OnOff "对应像素点的亮灭";
CM_ SG_ 1364 ICC_RISD_Pixel130_OnOff "对应像素点的亮灭";
CM_ SG_ 1364 ICC_RISD_Pixel131_OnOff "对应像素点的亮灭";
CM_ SG_ 1364 ICC_RISD_Pixel132_OnOff "对应像素点的亮灭";
CM_ SG_ 1364 ICC_RISD_Pixel133_OnOff "对应像素点的亮灭";
CM_ SG_ 1364 ICC_RISD_Pixel134_OnOff "对应像素点的亮灭";
CM_ SG_ 1364 ICC_RISD_Pixel135_OnOff "对应像素点的亮灭";
CM_ SG_ 1364 ICC_RISD_Pixel136_OnOff "对应像素点的亮灭";
CM_ SG_ 1364 ICC_RISD_Pixel137_OnOff "对应像素点的亮灭";
CM_ SG_ 1364 ICC_RISD_Pixel138_OnOff "对应像素点的亮灭";
CM_ SG_ 1364 ICC_RISD_Pixel139_OnOff "对应像素点的亮灭";
CM_ SG_ 1364 ICC_RISD_Pixel140_OnOff "对应像素点的亮灭";
CM_ SG_ 1364 ICC_RISD_Pixel141_OnOff "对应像素点的亮灭";
CM_ SG_ 1364 ICC_RISD_Pixel142_OnOff "对应像素点的亮灭";
CM_ SG_ 1364 ICC_RISD_Pixel143_OnOff "对应像素点的亮灭";
CM_ SG_ 1364 ICC_RISD_Pixel144_OnOff "对应像素点的亮灭";
CM_ SG_ 1364 ICC_RISD_Pixel145_OnOff "对应像素点的亮灭";
CM_ SG_ 1364 ICC_RISD_Pixel146_OnOff "对应像素点的亮灭";
CM_ SG_ 1364 ICC_RISD_Pixel147_OnOff "对应像素点的亮灭";
CM_ SG_ 1364 ICC_RISD_Pixel148_OnOff "对应像素点的亮灭";
CM_ SG_ 1364 ICC_RISD_Pixel149_OnOff "对应像素点的亮灭";
CM_ SG_ 1364 ICC_RISD_Pixel150_OnOff "对应像素点的亮灭";
CM_ SG_ 1364 ICC_RISD_Pixel151_OnOff "对应像素点的亮灭";
CM_ SG_ 1364 ICC_RISD_Pixel152_OnOff "对应像素点的亮灭";
CM_ SG_ 1364 ICC_RISD_Pixel153_OnOff "对应像素点的亮灭";
CM_ SG_ 1364 ICC_RISD_Pixel154_OnOff "对应像素点的亮灭";
CM_ SG_ 1364 ICC_RISD_Pixel155_OnOff "对应像素点的亮灭";
CM_ SG_ 1364 ICC_RISD_Pixel156_OnOff "对应像素点的亮灭";
CM_ SG_ 1364 ICC_RISD_Pixel157_OnOff "对应像素点的亮灭";
CM_ SG_ 1364 ICC_RISD_Pixel158_OnOff "对应像素点的亮灭";
CM_ SG_ 1364 ICC_RISD_Pixel159_OnOff "对应像素点的亮灭";
CM_ SG_ 1364 ICC_RISD_Pixel160_OnOff "对应像素点的亮灭";
CM_ SG_ 1364 ICC_RISD_Pixel161_OnOff "对应像素点的亮灭";
CM_ SG_ 1364 ICC_RISD_Pixel162_OnOff "对应像素点的亮灭";
CM_ SG_ 1364 ICC_RISD_Pixel163_OnOff "对应像素点的亮灭";
CM_ SG_ 1364 ICC_RISD_Pixel164_OnOff "对应像素点的亮灭";
CM_ SG_ 1364 ICC_RISD_Pixel165_OnOff "对应像素点的亮灭";
CM_ SG_ 1364 ICC_RISD_Pixel166_OnOff "对应像素点的亮灭";
CM_ SG_ 1364 ICC_RISD_Pixel167_OnOff "对应像素点的亮灭";
CM_ SG_ 1364 ICC_RISD_Pixel168_OnOff "对应像素点的亮灭";
CM_ SG_ 1364 ICC_RISD_Pixel169_OnOff "对应像素点的亮灭";
CM_ SG_ 1364 ICC_RISD_Pixel170_OnOff "对应像素点的亮灭";
CM_ SG_ 1364 ICC_RISD_Pixel171_OnOff "对应像素点的亮灭";
CM_ SG_ 1364 ICC_RISD_Pixel172_OnOff "对应像素点的亮灭";
CM_ SG_ 1364 ICC_RISD_Pixel173_OnOff "对应像素点的亮灭";
CM_ SG_ 1364 ICC_RISD_Pixel174_OnOff "对应像素点的亮灭";
CM_ SG_ 1364 ICC_RISD_Pixel175_OnOff "对应像素点的亮灭";
CM_ SG_ 1364 ICC_RISD_Pixel176_OnOff "对应像素点的亮灭";
CM_ SG_ 1364 ICC_RISD_Pixel177_OnOff "对应像素点的亮灭";
CM_ SG_ 1364 ICC_RISD_Pixel178_OnOff "对应像素点的亮灭";
CM_ SG_ 1364 ICC_RISD_Pixel179_OnOff "对应像素点的亮灭";
CM_ SG_ 1364 ICC_RISD_Pixel180_OnOff "对应像素点的亮灭";
CM_ SG_ 1364 ICC_RISD_Pixel181_OnOff "对应像素点的亮灭";
CM_ SG_ 1364 ICC_RISD_Pixel182_OnOff "对应像素点的亮灭";
CM_ SG_ 1364 ICC_RISD_Pixel183_OnOff "对应像素点的亮灭";
CM_ SG_ 1364 ICC_RISD_Pixel184_OnOff "对应像素点的亮灭";
CM_ SG_ 1364 ICC_RISD_Pixel185_OnOff "对应像素点的亮灭";
CM_ SG_ 1364 ICC_RISD_Pixel186_OnOff "对应像素点的亮灭";
CM_ SG_ 1364 ICC_RISD_Pixel187_OnOff "对应像素点的亮灭";
CM_ SG_ 1364 ICC_RISD_Pixel188_OnOff "对应像素点的亮灭";
CM_ SG_ 1364 ICC_RISD_Pixel189_OnOff "对应像素点的亮灭";
CM_ SG_ 1364 ICC_RISD_Pixel190_OnOff "对应像素点的亮灭";
CM_ SG_ 1364 ICC_RISD_Pixel191_OnOff "对应像素点的亮灭";
CM_ SG_ 1364 ICC_RISD_Pixel192_OnOff "对应像素点的亮灭";
CM_ SG_ 1364 ICC_RISD_Pixel193_OnOff "对应像素点的亮灭";
CM_ SG_ 1364 ICC_RISD_Pixel194_OnOff "对应像素点的亮灭";
CM_ SG_ 1364 ICC_RISD_Pixel195_OnOff "对应像素点的亮灭";
CM_ SG_ 1364 ICC_RISD_Pixel196_OnOff "对应像素点的亮灭";
CM_ SG_ 1364 ICC_RISD_Pixel197_OnOff "对应像素点的亮灭";
CM_ SG_ 1364 ICC_RISD_Pixel198_OnOff "对应像素点的亮灭";
CM_ SG_ 1364 ICC_RISD_Pixel199_OnOff "对应像素点的亮灭";
CM_ SG_ 1364 ICC_RISD_Pixel200_OnOff "对应像素点的亮灭";
CM_ SG_ 1364 ICC_RISD_Pixel201_OnOff "对应像素点的亮灭";
CM_ SG_ 1364 ICC_RISD_Pixel202_OnOff "对应像素点的亮灭";
CM_ SG_ 1364 ICC_RISD_Pixel203_OnOff "对应像素点的亮灭";
CM_ SG_ 1364 ICC_RISD_Pixel204_OnOff "对应像素点的亮灭";
CM_ SG_ 1364 ICC_RISD_Pixel205_OnOff "对应像素点的亮灭";
CM_ SG_ 1364 ICC_RISD_Pixel206_OnOff "对应像素点的亮灭";
CM_ SG_ 1364 ICC_RISD_Pixel207_OnOff "对应像素点的亮灭";
CM_ SG_ 1364 ICC_RISD_Pixel208_OnOff "对应像素点的亮灭";
CM_ SG_ 1364 ICC_RISD_Pixel209_OnOff "对应像素点的亮灭";
CM_ SG_ 1364 ICC_RISD_Pixel210_OnOff "对应像素点的亮灭";
CM_ SG_ 1364 ICC_RISD_Pixel211_OnOff "对应像素点的亮灭";
CM_ SG_ 1364 ICC_RISD_Pixel212_OnOff "对应像素点的亮灭";
CM_ SG_ 1364 ICC_RISD_Pixel213_OnOff "对应像素点的亮灭";
CM_ SG_ 1364 ICC_RISD_Pixel214_OnOff "对应像素点的亮灭";
CM_ SG_ 1364 ICC_RISD_Pixel215_OnOff "对应像素点的亮灭";
CM_ SG_ 1364 ICC_RISD_Pixel216_OnOff "对应像素点的亮灭";
CM_ SG_ 1364 ICC_RISD_Pixel217_OnOff "对应像素点的亮灭";
CM_ SG_ 1364 ICC_RISD_Pixel218_OnOff "对应像素点的亮灭";
CM_ SG_ 1364 ICC_RISD_Pixel219_OnOff "对应像素点的亮灭";
CM_ SG_ 1364 ICC_RISD_Pixel220_OnOff "对应像素点的亮灭";
CM_ SG_ 1364 ICC_RISD_Pixel221_OnOff "对应像素点的亮灭";
CM_ SG_ 1364 ICC_RISD_Pixel222_OnOff "对应像素点的亮灭";
CM_ SG_ 1364 ICC_RISD_Pixel223_OnOff "对应像素点的亮灭";
CM_ SG_ 1364 ICC_RISD_Pixel224_OnOff "对应像素点的亮灭";
CM_ SG_ 1364 ICC_RISD_Pixel225_OnOff "对应像素点的亮灭";
CM_ SG_ 1364 ICC_RISD_Pixel226_OnOff "对应像素点的亮灭";
CM_ SG_ 1364 ICC_RISD_Pixel227_OnOff "对应像素点的亮灭";
CM_ SG_ 1364 ICC_RISD_Pixel228_OnOff "对应像素点的亮灭";
CM_ SG_ 1364 ICC_RISD_Pixel229_OnOff "对应像素点的亮灭";
CM_ SG_ 1364 ICC_RISD_Pixel230_OnOff "对应像素点的亮灭";
CM_ SG_ 1364 ICC_RISD_Pixel231_OnOff "对应像素点的亮灭";
CM_ SG_ 1364 ICC_RISD_Pixel232_OnOff "对应像素点的亮灭";
CM_ SG_ 1364 ICC_RISD_Pixel233_OnOff "对应像素点的亮灭";
CM_ SG_ 1364 ICC_RISD_Pixel234_OnOff "对应像素点的亮灭";
CM_ SG_ 1364 ICC_RISD_Pixel235_OnOff "对应像素点的亮灭";
CM_ SG_ 1364 ICC_RISD_Pixel236_OnOff "对应像素点的亮灭";
CM_ SG_ 1364 ICC_RISD_Pixel237_OnOff "对应像素点的亮灭";
CM_ SG_ 1364 ICC_RISD_Pixel238_OnOff "对应像素点的亮灭";
CM_ SG_ 1364 ICC_RISD_Pixel239_OnOff "对应像素点的亮灭";
CM_ SG_ 1364 ICC_RISD_Pixel240_OnOff "对应像素点的亮灭";
CM_ SG_ 1364 ICC_RISD_Pixel241_OnOff "对应像素点的亮灭";
CM_ SG_ 1364 ICC_RISD_Pixel242_OnOff "对应像素点的亮灭";
CM_ SG_ 1364 ICC_RISD_Pixel243_OnOff "对应像素点的亮灭";
CM_ SG_ 1364 ICC_RISD_Pixel244_OnOff "对应像素点的亮灭";
CM_ SG_ 1364 ICC_RISD_Pixel245_OnOff "对应像素点的亮灭";
CM_ SG_ 1364 ICC_RISD_Pixel246_OnOff "对应像素点的亮灭";
CM_ SG_ 1364 ICC_RISD_Pixel247_OnOff "对应像素点的亮灭";
CM_ SG_ 1364 ICC_RISD_Pixel248_OnOff "对应像素点的亮灭";
CM_ SG_ 1364 ICC_RISD_Pixel249_OnOff "对应像素点的亮灭";
CM_ SG_ 1364 ICC_RISD_Pixel250_OnOff "对应像素点的亮灭";
CM_ SG_ 1364 ICC_RISD_Pixel251_OnOff "对应像素点的亮灭";
CM_ SG_ 1364 ICC_RISD_Pixel252_OnOff "对应像素点的亮灭";
CM_ SG_ 1364 ICC_RISD_Pixel253_OnOff "对应像素点的亮灭";
CM_ SG_ 1364 ICC_RISD_Pixel254_OnOff "对应像素点的亮灭";
CM_ SG_ 1364 ICC_RISD_Pixel255_OnOff "对应像素点的亮灭";
CM_ SG_ 1364 ICC_RISD_Pixel256_OnOff "对应像素点的亮灭";
CM_ SG_ 1364 ICC_RISD_Pixel257_OnOff "对应像素点的亮灭";
CM_ SG_ 1364 ICC_RISD_Pixel258_OnOff "对应像素点的亮灭";
CM_ SG_ 1364 ICC_RISD_Pixel259_OnOff "对应像素点的亮灭";
CM_ SG_ 1364 ICC_RISD_Pixel260_OnOff "对应像素点的亮灭";
CM_ SG_ 1364 ICC_RISD_Pixel261_OnOff "对应像素点的亮灭";
CM_ SG_ 1364 ICC_RISD_Pixel262_OnOff "对应像素点的亮灭";
CM_ SG_ 1364 ICC_RISD_Pixel263_OnOff "对应像素点的亮灭";
CM_ SG_ 1364 ICC_RISD_Pixel264_OnOff "对应像素点的亮灭";
CM_ SG_ 1364 ICC_RISD_Pixel265_OnOff "对应像素点的亮灭";
CM_ SG_ 1364 ICC_RISD_Pixel266_OnOff "对应像素点的亮灭";
CM_ SG_ 1364 ICC_RISD_Pixel267_OnOff "对应像素点的亮灭";
CM_ SG_ 1364 ICC_RISD_Pixel268_OnOff "对应像素点的亮灭";
CM_ SG_ 1364 ICC_RISD_Pixel269_OnOff "对应像素点的亮灭";
CM_ SG_ 1364 ICC_RISD_Pixel270_OnOff "对应像素点的亮灭";
CM_ SG_ 1364 ICC_RISD_Pixel271_OnOff "对应像素点的亮灭";
CM_ SG_ 1364 ICC_RISD_Pixel272_OnOff "对应像素点的亮灭";
CM_ SG_ 1364 ICC_RISD_Pixel273_OnOff "对应像素点的亮灭";
CM_ SG_ 1364 ICC_RISD_Pixel274_OnOff "对应像素点的亮灭";
CM_ SG_ 1364 ICC_RISD_Pixel275_OnOff "对应像素点的亮灭";
CM_ SG_ 1364 ICC_RISD_Pixel276_OnOff "对应像素点的亮灭";
CM_ SG_ 1364 ICC_RISD_Pixel277_OnOff "对应像素点的亮灭";
CM_ SG_ 1364 ICC_RISD_Pixel278_OnOff "对应像素点的亮灭";
CM_ SG_ 1364 ICC_RISD_Pixel279_OnOff "对应像素点的亮灭";
CM_ SG_ 1364 ICC_RISD_Pixel280_OnOff "对应像素点的亮灭";
CM_ SG_ 1364 ICC_RISD_Pixel281_OnOff "对应像素点的亮灭";
CM_ SG_ 1364 ICC_RISD_Pixel282_OnOff "对应像素点的亮灭";
CM_ SG_ 1364 ICC_RISD_Pixel283_OnOff "对应像素点的亮灭";
CM_ SG_ 1364 ICC_RISD_Pixel284_OnOff "对应像素点的亮灭";
CM_ SG_ 1364 ICC_RISD_Pixel285_OnOff "对应像素点的亮灭";
CM_ SG_ 1364 ICC_RISD_Pixel286_OnOff "对应像素点的亮灭";
CM_ SG_ 1364 ICC_RISD_Pixel287_OnOff "对应像素点的亮灭";
CM_ SG_ 1364 ICC_RISD_Pixel288_OnOff "对应像素点的亮灭";
CM_ SG_ 1364 ICC_RISD_Pixel289_OnOff "对应像素点的亮灭";
CM_ SG_ 1364 ICC_RISD_Pixel290_OnOff "对应像素点的亮灭";
CM_ SG_ 1364 ICC_RISD_Pixel291_OnOff "对应像素点的亮灭";
CM_ SG_ 1364 ICC_RISD_Pixel292_OnOff "对应像素点的亮灭";
CM_ SG_ 1364 ICC_RISD_Pixel293_OnOff "对应像素点的亮灭";
CM_ SG_ 1364 ICC_RISD_Pixel294_OnOff "对应像素点的亮灭";
CM_ SG_ 1364 ICC_RISD_Pixel295_OnOff "对应像素点的亮灭";
CM_ SG_ 1364 ICC_RISD_Pixel296_OnOff "对应像素点的亮灭";
CM_ SG_ 1364 ICC_RISD_Pixel297_OnOff "对应像素点的亮灭";
CM_ SG_ 1364 ICC_RISD_Pixel298_OnOff "对应像素点的亮灭";
CM_ SG_ 1364 ICC_RISD_Pixel299_OnOff "对应像素点的亮灭";
CM_ SG_ 1364 ICC_RISD_Pixel300_OnOff "对应像素点的亮灭";
CM_ SG_ 1364 ICC_RISD_Pixel301_OnOff "对应像素点的亮灭";
CM_ SG_ 1364 ICC_RISD_Pixel302_OnOff "对应像素点的亮灭";
CM_ SG_ 1364 ICC_RISD_Pixel303_OnOff "对应像素点的亮灭";
CM_ SG_ 1364 ICC_RISD_Pixel304_OnOff "对应像素点的亮灭";
CM_ SG_ 1364 ICC_RISD_Pixel305_OnOff "对应像素点的亮灭";
CM_ SG_ 1364 ICC_RISD_Pixel306_OnOff "对应像素点的亮灭";
CM_ SG_ 1364 ICC_RISD_Pixel307_OnOff "对应像素点的亮灭";
CM_ SG_ 1364 ICC_RISD_Pixel308_OnOff "对应像素点的亮灭";
CM_ SG_ 1364 ICC_RISD_Pixel309_OnOff "对应像素点的亮灭";
CM_ SG_ 1364 ICC_RISD_Pixel310_OnOff "对应像素点的亮灭";
CM_ SG_ 1364 ICC_RISD_Pixel311_OnOff "对应像素点的亮灭";
CM_ SG_ 1364 ICC_RISD_Pixel312_OnOff "对应像素点的亮灭";
CM_ SG_ 1364 ICC_RISD_Pixel313_OnOff "对应像素点的亮灭";
CM_ SG_ 1364 ICC_RISD_Pixel314_OnOff "对应像素点的亮灭";
CM_ SG_ 1364 ICC_RISD_Pixel315_OnOff "对应像素点的亮灭";
CM_ SG_ 1364 ICC_RISD_Pixel316_OnOff "对应像素点的亮灭";
CM_ SG_ 1364 ICC_RISD_Pixel317_OnOff "对应像素点的亮灭";
CM_ SG_ 1364 ICC_RISD_Pixel318_OnOff "对应像素点的亮灭";
CM_ SG_ 1364 ICC_RISD_Pixel319_OnOff "对应像素点的亮灭";
CM_ SG_ 1364 ICC_RISD_Pixel320_OnOff "对应像素点的亮灭";
CM_ SG_ 1364 ICC_RISD_Pixel321_OnOff "对应像素点的亮灭";
CM_ SG_ 1364 ICC_RISD_Pixel322_OnOff "对应像素点的亮灭";
CM_ SG_ 1364 ICC_RISD_Pixel323_OnOff "对应像素点的亮灭";
CM_ SG_ 1364 ICC_RISD_Pixel324_OnOff "对应像素点的亮灭";
CM_ SG_ 1364 ICC_RISD_Pixel325_OnOff "对应像素点的亮灭";
CM_ SG_ 1364 ICC_RISD_Pixel326_OnOff "对应像素点的亮灭";
CM_ SG_ 1364 ICC_RISD_Pixel327_OnOff "对应像素点的亮灭";
CM_ SG_ 1364 ICC_RISD_Pixel328_OnOff "对应像素点的亮灭";
CM_ SG_ 1364 ICC_RISD_Pixel329_OnOff "对应像素点的亮灭";
CM_ SG_ 1364 ICC_RISD_Pixel330_OnOff "对应像素点的亮灭";
CM_ SG_ 1364 ICC_RISD_Pixel331_OnOff "对应像素点的亮灭";
CM_ SG_ 1364 ICC_RISD_Pixel332_OnOff "对应像素点的亮灭";
CM_ SG_ 1364 ICC_RISD_Pixel333_OnOff "对应像素点的亮灭";
CM_ SG_ 1364 ICC_RISD_Pixel334_OnOff "对应像素点的亮灭";
CM_ SG_ 1364 ICC_RISD_Pixel335_OnOff "对应像素点的亮灭";
CM_ SG_ 1364 ICC_RISD_Pixel336_OnOff "对应像素点的亮灭";
CM_ SG_ 1364 ICC_RISD_Pixel337_OnOff "对应像素点的亮灭";
CM_ SG_ 1364 ICC_RISD_Pixel338_OnOff "对应像素点的亮灭";
CM_ SG_ 1364 ICC_RISD_Pixel339_OnOff "对应像素点的亮灭";
CM_ SG_ 1364 ICC_RISD_Pixel340_OnOff "对应像素点的亮灭";
CM_ SG_ 1364 ICC_RISD_Pixel341_OnOff "对应像素点的亮灭";
CM_ SG_ 1364 ICC_RISD_Pixel342_OnOff "对应像素点的亮灭";
CM_ SG_ 1364 ICC_RISD_Pixel343_OnOff "对应像素点的亮灭";
CM_ SG_ 1364 ICC_RISD_Pixel344_OnOff "对应像素点的亮灭";
CM_ SG_ 1364 ICC_RISD_Pixel345_OnOff "对应像素点的亮灭";
CM_ SG_ 1364 ICC_RISD_Pixel346_OnOff "对应像素点的亮灭";
CM_ SG_ 1364 ICC_RISD_Pixel347_OnOff "对应像素点的亮灭";
CM_ SG_ 1364 ICC_RISD_Pixel348_OnOff "对应像素点的亮灭";
CM_ SG_ 1364 ICC_RISD_Pixel349_OnOff "对应像素点的亮灭";
CM_ SG_ 1364 ICC_RISD_Pixel350_OnOff "对应像素点的亮灭";
CM_ SG_ 1364 ICC_RISD_Pixel351_OnOff "对应像素点的亮灭";
CM_ SG_ 1364 ICC_RISD_Pixel352_OnOff "对应像素点的亮灭";
CM_ SG_ 1364 ICC_RISD_Pixel353_OnOff "对应像素点的亮灭";
CM_ SG_ 1364 ICC_RISD_Pixel354_OnOff "对应像素点的亮灭";
CM_ SG_ 1364 ICC_RISD_Pixel355_OnOff "对应像素点的亮灭";
CM_ SG_ 1364 ICC_RISD_Pixel356_OnOff "对应像素点的亮灭";
CM_ SG_ 1364 ICC_RISD_Pixel357_OnOff "对应像素点的亮灭";
CM_ SG_ 1364 ICC_RISD_Pixel358_OnOff "对应像素点的亮灭";
CM_ SG_ 1364 ICC_RISD_Pixel359_OnOff "对应像素点的亮灭";
CM_ SG_ 1364 ICC_RISD_Pixel360_OnOff "对应像素点的亮灭";
CM_ SG_ 1364 ICC_RISD_Pixel361_OnOff "对应像素点的亮灭";
CM_ SG_ 1364 ICC_RISD_Pixel362_OnOff "对应像素点的亮灭";
CM_ SG_ 1364 ICC_RISD_Pixel363_OnOff "对应像素点的亮灭";
CM_ SG_ 1364 ICC_RISD_Pixel364_OnOff "对应像素点的亮灭";
CM_ SG_ 1364 ICC_RISD_Pixel365_OnOff "对应像素点的亮灭";
CM_ SG_ 1364 ICC_RISD_Pixel366_OnOff "对应像素点的亮灭";
CM_ SG_ 1364 ICC_RISD_Pixel367_OnOff "对应像素点的亮灭";
CM_ SG_ 1364 ICC_RISD_Pixel368_OnOff "对应像素点的亮灭";
CM_ SG_ 1364 ICC_RISD_Pixel369_OnOff "对应像素点的亮灭";
CM_ SG_ 1364 ICC_RISD_Pixel370_OnOff "对应像素点的亮灭";
CM_ SG_ 1364 ICC_RISD_Pixel371_OnOff "对应像素点的亮灭";
CM_ SG_ 1364 ICC_RISD_Pixel372_OnOff "对应像素点的亮灭";
CM_ SG_ 1364 ICC_RISD_Pixel373_OnOff "对应像素点的亮灭";
CM_ SG_ 1364 ICC_RISD_Pixel374_OnOff "对应像素点的亮灭";
CM_ SG_ 1364 ICC_RISD_Pixel375_OnOff "对应像素点的亮灭";
CM_ SG_ 1364 ICC_RISD_Pixel376_OnOff "对应像素点的亮灭";
CM_ SG_ 1364 ICC_RISD_Pixel377_OnOff "对应像素点的亮灭";
CM_ SG_ 1364 ICC_RISD_Pixel378_OnOff "对应像素点的亮灭";
CM_ SG_ 1364 ICC_RISD_Pixel379_OnOff "对应像素点的亮灭";
CM_ SG_ 1364 ICC_RISD_Pixel380_OnOff "对应像素点的亮灭";
CM_ SG_ 1364 ICC_RISD_Pixel381_OnOff "对应像素点的亮灭";
CM_ SG_ 1364 ICC_RISD_Pixel382_OnOff "对应像素点的亮灭";
CM_ SG_ 1364 ICC_RISD_Pixel383_OnOff "对应像素点的亮灭";
CM_ SG_ 1364 ICC_RISD_Pixel384_OnOff "对应像素点的亮灭";
CM_ SG_ 1364 ICC_RISD_Pixel385_OnOff "对应像素点的亮灭";
CM_ SG_ 1364 ICC_RISD_Pixel386_OnOff "对应像素点的亮灭";
CM_ SG_ 1364 ICC_RISD_Pixel387_OnOff "对应像素点的亮灭";
CM_ SG_ 1364 ICC_RISD_Pixel388_OnOff "对应像素点的亮灭";
CM_ SG_ 1364 ICC_RISD_Pixel389_OnOff "对应像素点的亮灭";
CM_ SG_ 1364 ICC_RISD_Pixel390_OnOff "对应像素点的亮灭";
CM_ SG_ 1364 ICC_RISD_Pixel391_OnOff "对应像素点的亮灭";
CM_ SG_ 1364 ICC_RISD_Pixel392_OnOff "对应像素点的亮灭";
CM_ SG_ 1364 ICC_RISD_Pixel393_OnOff "对应像素点的亮灭";
CM_ SG_ 1364 ICC_RISD_Pixel394_OnOff "对应像素点的亮灭";
CM_ SG_ 1364 ICC_RISD_Pixel395_OnOff "对应像素点的亮灭";
CM_ SG_ 1364 ICC_RISD_Pixel396_OnOff "对应像素点的亮灭";
CM_ SG_ 1364 ICC_RISD_Pixel397_OnOff "对应像素点的亮灭";
CM_ SG_ 1364 ICC_RISD_Pixel398_OnOff "对应像素点的亮灭";
CM_ SG_ 1364 ICC_RISD_Pixel399_OnOff "对应像素点的亮灭";
CM_ SG_ 1364 ICC_RISD_Pixel400_OnOff "对应像素点的亮灭";
CM_ SG_ 1364 ICC_RISD_Pixel401_OnOff "对应像素点的亮灭";
CM_ SG_ 1364 ICC_RISD_Pixel402_OnOff "对应像素点的亮灭";
CM_ SG_ 1364 ICC_RISD_Pixel403_OnOff "对应像素点的亮灭";
CM_ SG_ 1364 ICC_RISD_Pixel404_OnOff "对应像素点的亮灭";
CM_ SG_ 1364 ICC_RISD_Pixel405_OnOff "对应像素点的亮灭";
CM_ SG_ 1364 ICC_RISD_Pixel406_OnOff "对应像素点的亮灭";
CM_ SG_ 1364 ICC_RISD_Pixel407_OnOff "对应像素点的亮灭";
CM_ SG_ 1364 ICC_RISD_Pixel408_OnOff "对应像素点的亮灭";
CM_ SG_ 1364 ICC_RISD_Pixel409_OnOff "对应像素点的亮灭";
CM_ SG_ 1364 ICC_RISD_Pixel410_OnOff "对应像素点的亮灭";
CM_ SG_ 1364 ICC_RISD_Pixel411_OnOff "对应像素点的亮灭";
CM_ SG_ 1364 ICC_RISD_Pixel412_OnOff "对应像素点的亮灭";
CM_ SG_ 1364 ICC_RISD_Pixel413_OnOff "对应像素点的亮灭";
CM_ SG_ 1364 ICC_RISD_Pixel414_OnOff "对应像素点的亮灭";
CM_ SG_ 1364 ICC_RISD_Pixel415_OnOff "对应像素点的亮灭";
CM_ SG_ 1364 ICC_RISD_Pixel416_OnOff "对应像素点的亮灭";
CM_ SG_ 1364 ICC_RISD_Pixel417_OnOff "对应像素点的亮灭";
CM_ SG_ 1364 ICC_RISD_Pixel418_OnOff "对应像素点的亮灭";
CM_ SG_ 1364 ICC_RISD_Pixel419_OnOff "对应像素点的亮灭";
CM_ SG_ 1364 ICC_RISD_Pixel420_OnOff "对应像素点的亮灭";
CM_ SG_ 1364 ICC_RISD_Pixel421_OnOff "对应像素点的亮灭";
CM_ SG_ 1364 ICC_RISD_Pixel422_OnOff "对应像素点的亮灭";
CM_ SG_ 1364 ICC_RISD_Pixel423_OnOff "对应像素点的亮灭";
CM_ SG_ 1364 ICC_RISD_Pixel424_OnOff "对应像素点的亮灭";
CM_ SG_ 1364 ICC_RISD_Pixel425_OnOff "对应像素点的亮灭";
CM_ SG_ 1364 ICC_RISD_Pixel426_OnOff "对应像素点的亮灭";
CM_ SG_ 1364 ICC_RISD_Pixel427_OnOff "对应像素点的亮灭";
CM_ SG_ 1364 ICC_RISD_Pixel428_OnOff "对应像素点的亮灭";
CM_ SG_ 1364 ICC_RISD_Pixel429_OnOff "对应像素点的亮灭";
CM_ SG_ 1364 ICC_RISD_Pixel430_OnOff "对应像素点的亮灭";
CM_ SG_ 1364 ICC_RISD_Pixel431_OnOff "对应像素点的亮灭";
CM_ SG_ 1364 ICC_RISD_Pixel432_OnOff "对应像素点的亮灭";
CM_ SG_ 1364 ICC_RISD_Pixel433_OnOff "对应像素点的亮灭";
CM_ SG_ 1364 ICC_RISD_Pixel434_OnOff "对应像素点的亮灭";
CM_ SG_ 1364 ICC_RISD_Pixel435_OnOff "对应像素点的亮灭";
CM_ SG_ 1364 ICC_RISD_Pixel436_OnOff "对应像素点的亮灭";
CM_ SG_ 1364 ICC_RISD_Pixel437_OnOff "对应像素点的亮灭";
CM_ SG_ 1364 ICC_RISD_Pixel438_OnOff "对应像素点的亮灭";
CM_ SG_ 1364 ICC_RISD_Pixel439_OnOff "对应像素点的亮灭";
CM_ SG_ 1364 ICC_RISD_Pixel440_OnOff "对应像素点的亮灭";
CM_ SG_ 1364 ICC_RISD_Pixel441_OnOff "对应像素点的亮灭";
CM_ SG_ 1364 ICC_RISD_Pixel442_OnOff "对应像素点的亮灭";
CM_ SG_ 1364 ICC_RISD_Pixel443_OnOff "对应像素点的亮灭";
CM_ SG_ 1364 ICC_RISD_Pixel444_OnOff "对应像素点的亮灭";
CM_ SG_ 1364 ICC_RISD_Pixel445_OnOff "对应像素点的亮灭";
CM_ SG_ 1364 ICC_RISD_Pixel446_OnOff "对应像素点的亮灭";
CM_ SG_ 1364 ICC_RISD_Pixel447_OnOff "对应像素点的亮灭";
CM_ SG_ 1364 ICC_RISD_Pixel448_OnOff "对应像素点的亮灭";
CM_ SG_ 1364 ICC_RISD_Pixel449_OnOff "对应像素点的亮灭";
CM_ SG_ 1364 ICC_RISD_Pixel450_OnOff "对应像素点的亮灭";
CM_ SG_ 1364 ICC_RISD_Pixel451_OnOff "对应像素点的亮灭";
CM_ SG_ 1364 ICC_RISD_Pixel452_OnOff "对应像素点的亮灭";
CM_ SG_ 1364 ICC_RISD_Pixel453_OnOff "对应像素点的亮灭";
CM_ SG_ 1364 ICC_RISD_Pixel454_OnOff "对应像素点的亮灭";
CM_ SG_ 1364 ICC_RISD_Pixel455_OnOff "对应像素点的亮灭";
CM_ SG_ 1364 ICC_RISD_Pixel456_OnOff "对应像素点的亮灭";
CM_ SG_ 1364 ICC_RISD_Pixel457_OnOff "对应像素点的亮灭";
CM_ SG_ 1364 ICC_RISD_Pixel458_OnOff "对应像素点的亮灭";
CM_ SG_ 1364 ICC_RISD_Pixel459_OnOff "对应像素点的亮灭";
CM_ SG_ 1364 ICC_RISD_Pixel460_OnOff "对应像素点的亮灭";
CM_ SG_ 1364 ICC_RISD_Pixel461_OnOff "对应像素点的亮灭";
CM_ SG_ 1364 ICC_RISD_Pixel462_OnOff "对应像素点的亮灭";
CM_ SG_ 1364 ICC_RISD_Pixel463_OnOff "对应像素点的亮灭";
CM_ SG_ 1364 ICC_RISD_Pixel464_OnOff "对应像素点的亮灭";
CM_ SG_ 1364 ICC_RISD_Pixel465_OnOff "对应像素点的亮灭";
CM_ SG_ 1364 ICC_RISD_Pixel466_OnOff "对应像素点的亮灭";
CM_ SG_ 1364 ICC_RISD_Pixel467_OnOff "对应像素点的亮灭";
CM_ SG_ 1364 ICC_RISD_Pixel468_OnOff "对应像素点的亮灭";
CM_ SG_ 1364 ICC_RISD_Pixel469_OnOff "对应像素点的亮灭";
CM_ SG_ 1364 ICC_RISD_Pixel470_OnOff "对应像素点的亮灭";
CM_ SG_ 1364 ICC_RISD_Pixel471_OnOff "对应像素点的亮灭";
CM_ SG_ 1364 ICC_RISD_Pixel472_OnOff "对应像素点的亮灭";
CM_ SG_ 1364 ICC_RISD_Pixel473_OnOff "对应像素点的亮灭";
CM_ SG_ 1364 ICC_RISD_Pixel474_OnOff "对应像素点的亮灭";
CM_ SG_ 1364 ICC_RISD_Pixel475_OnOff "对应像素点的亮灭";
CM_ SG_ 1364 ICC_RISD_Pixel476_OnOff "对应像素点的亮灭";
CM_ SG_ 1364 ICC_RISD_Pixel477_OnOff "对应像素点的亮灭";
CM_ SG_ 1364 ICC_RISD_Pixel478_OnOff "对应像素点的亮灭";
CM_ SG_ 1364 ICC_RISD_Pixel479_OnOff "对应像素点的亮灭";
CM_ SG_ 1364 ICC_RISD_Pixel480_OnOff "对应像素点的亮灭";
CM_ SG_ 1364 ICC_RISD_Pixel481_OnOff "对应像素点的亮灭";
CM_ SG_ 1364 ICC_RISD_Pixel482_OnOff "对应像素点的亮灭";
CM_ SG_ 1364 ICC_RISD_Pixel483_OnOff "对应像素点的亮灭";
CM_ SG_ 1364 ICC_RISD_Pixel484_OnOff "对应像素点的亮灭";
CM_ SG_ 1364 ICC_RISD_Pixel485_OnOff "对应像素点的亮灭";
CM_ SG_ 1364 ICC_RISD_Pixel486_OnOff "对应像素点的亮灭";
CM_ SG_ 1364 ICC_RISD_Pixel487_OnOff "对应像素点的亮灭";
CM_ SG_ 1364 ICC_RISD_Pixel488_OnOff "对应像素点的亮灭";
CM_ SG_ 1364 ICC_RISD_Pixel489_OnOff "对应像素点的亮灭";
CM_ SG_ 1364 ICC_RISD_Pixel490_OnOff "对应像素点的亮灭";
CM_ SG_ 1364 ICC_RISD_Pixel491_OnOff "对应像素点的亮灭";
CM_ SG_ 1364 ICC_RISD_Pixel492_OnOff "对应像素点的亮灭";
CM_ SG_ 1364 ICC_RISD_Pixel493_OnOff "对应像素点的亮灭";
CM_ SG_ 1364 ICC_RISD_Pixel494_OnOff "对应像素点的亮灭";
CM_ SG_ 1364 ICC_RISD_Pixel495_OnOff "对应像素点的亮灭";
CM_ SG_ 1364 ICC_RISD_Pixel496_OnOff "对应像素点的亮灭";
CM_ SG_ 1364 ICC_RISD_Pixel497_OnOff "对应像素点的亮灭";
CM_ SG_ 1364 ICC_RISD_Pixel498_OnOff "对应像素点的亮灭";
CM_ SG_ 1364 ICC_RISD_Pixel499_OnOff "对应像素点的亮灭";
CM_ SG_ 1364 ICC_RISD_Pixel500_OnOff "对应像素点的亮灭";
CM_ SG_ 1364 ICC_RISD_Pixel501_OnOff "对应像素点的亮灭";
CM_ SG_ 1364 ICC_RISD_Pixel502_OnOff "对应像素点的亮灭";
CM_ SG_ 1364 ICC_RISD_Pixel503_OnOff "对应像素点的亮灭";
CM_ SG_ 1364 ICC_RISD_Pixel504_OnOff "对应像素点的亮灭";
CM_ SG_ 1366 ICC_LKSSettingModSt "车道辅助模式";
CM_ SG_ 1366 ICC_LDWWarnType "LDW/LDP报警方式";
CM_ SG_ 1366 ICC_LDWLDPSnvtySet "车道偏离敏感度";
CM_ SG_ 1366 ICC_ELKSettingSt "ELK功能设置状态";
CM_ SG_ 1366 ICC_ICAEnableBtnSts "ICA功能使能开关（车道居中辅助";
CM_ SG_ 1366 ICC_FCWSettingSt "FCW功能设置状态";
CM_ SG_ 1366 ICC_AEBSettingSt "AEB功能设置状态";
CM_ SG_ 1366 ICC_ISLIWarnMod "智能限速提醒方式";
CM_ SG_ 1366 ICC_Reset "整车恢复出厂设置";
CM_ SG_ 1366 ICC_Customize_buttons "自定义按键大屏设置设置项
0x4:记忆泊车";
CM_ SG_ 1366 ICC_AVM_TouchEvt "触碰事件";
CM_ SG_ 1366 ICC_AVM_BtnPressInputValueX "触碰坐标X";
CM_ SG_ 1366 ICC_AVM_BtnPressInputValueY "触碰坐标Y";
CM_ SG_ 1354 ICC_SetMsgTotal "当前短信总条数";
CM_ SG_ 1354 ICC_SetMSDTotal "设置MSD短信阈值";
CM_ SG_ 1354 ICC_SetCallTimeThreshold "设置通话总时长阈值";
CM_ SG_ 1354 ICC_SetTodayCallTimeThreshold "设置当日通话时长阈值";
CM_ SG_ 1354 ICC_SetCurretnCallTime "设置当前通话总时长";
CM_ SG_ 1354 ICC_SetCurretnMsgThreshold "设置当前短信总条数";
CM_ SG_ 1354 ICC_SetMsgTotalThreshold "设置短信总条数阈值";
CM_ SG_ 1354 ICC_SetMsdThreshold "设置MSD短信阈值";
CM_ SG_ 1354 ICC_SetCurrenMsdCnt "设置当前MSD短条数";
CM_ SG_ 1354 ICC_SetCustomMsgThreshold "设置客户短信阈值";
CM_ SG_ 1354 ICC_SetCurrentCustomMsgCnt "设置当前客户短信条数";
CM_ SG_ 1356 ICC_flag "选择激活类型";
CM_ SG_ 1356 ICC_ActiveTsp_Req "车机发起SBOX端的TSP注册";
CM_ SG_ 1356 ICC_ActiveSim_Req "车机切换sbox sim卡激活与未激活状态";
CM_ SG_ 1356 ICC_GetMac_req "请求查询MAC地址";
CM_ SG_ 1356 ICC_GetIccid_Vin "查询VIN和ICCID请求";
CM_ SG_ 1356 ICC_GivePlatformNumber_Flag "平台号码是否有效";
CM_ SG_ 1356 ICC_Platform_Phonenub1 "平台号码第1个数（从最左边开始）";
CM_ SG_ 1356 ICC_Platform_Phonenub2 "平台号码第2个数";
CM_ SG_ 1356 ICC_Platform_Phonenub3 "平台号码第3个数";
CM_ SG_ 1356 ICC_Platform_Phonenub4 "平台号码第4个数";
CM_ SG_ 1356 ICC_Platform_Phonenub5 "平台号码第5个数";
CM_ SG_ 1356 ICC_Platform_Phonenub6 "平台号码第6个数";
CM_ SG_ 1356 ICC_Platform_Phonenub7 "平台号码第7个数";
CM_ SG_ 1356 ICC_Platform_Phonenub8 "平台号码第8个数";
CM_ SG_ 1356 ICC_Platform_Phonenub9 "平台号码第9个数";
CM_ SG_ 1356 ICC_Platform_Phonenub10 "平台号码第10个数";
CM_ SG_ 1356 ICC_Platform_Phonenub11 "平台号码第11个数";
CM_ SG_ 1356 ICC_Platform_Phonenub12 "平台号码第12个数";
CM_ SG_ 1356 ICC_Platform_Phonenub13 "平台号码第13个数";
CM_ SG_ 1356 ICC_Platform_Phonenub14 "平台号码第14个数";
CM_ SG_ 1356 ICC_Platform_Phonenub15 "平台号码第15个数";
CM_ SG_ 1356 ICC_Platform_Phonenub16 "平台号码第16个数";
CM_ SG_ 1356 ICC_Platform_Phonenub17 "平台号码第17个数";
CM_ SG_ 1356 ICC_Platform_Phonenub18 "平台号码第18个数";
CM_ SG_ 1356 ICC_Platform_Phonenub19 "平台号码第19个数";
CM_ SG_ 1356 ICC_Platform_Phonenub20 "平台号码第20个数";
CM_ SG_ 1356 ICC_Mac_Flag "车机蓝牙MAC是否有效";
CM_ SG_ 1356 ICC_Mac0 "车机MAC第0个字节";
CM_ SG_ 1356 ICC_Mac1 "车机MAC第1个字节";
CM_ SG_ 1356 ICC_Mac2 "车机MAC第2个字节";
CM_ SG_ 1356 ICC_Mac3 "车机MAC第3个字节";
CM_ SG_ 1356 ICC_Mac4 "车机MAC第4个字节";
CM_ SG_ 1356 ICC_Mac5 "车机MAC第5个字节";
CM_ SG_ 1453 ICC_BedStatus "大床模式开关请求
0x1:居家大床
0x2:副驾单人床
0x3:驻车沙发";
CM_ SG_ 1453 ICC_MemAttributeFL "DriverSeatMemberAttribute
驾驶位成员属性";
CM_ SG_ 1453 ICC_MemAttributeFR "CoDriverSeatMemberAttribute
副驾驶位成员属性";
CM_ SG_ 1453 ICC_MemAttributeRL "SecondRowLeftSeatMemberAttribute
二排左成员属性";
CM_ SG_ 1453 ICC_MemAttributeRR "SecondRowRightSeatMemberAttribute
二排右成员属性";
CM_ SG_ 1380 ICC_FLSeatHeatLvlCmd2 "一排主驾座椅加热信号-捷途使用";
CM_ SG_ 1380 ICC_RLSeatHeatLvlCmd2 "二排左座椅加热-捷途使用";
CM_ SG_ 1380 ICC_FLSeatVentLvlCmd2 "主驾座椅通风-捷途使用";
CM_ SG_ 1380 ICC_RLSeatVentLvlCmd2 "二排左座椅通风-捷途使用";
CM_ SG_ 1380 ICC_FRSeatHeatLvlCmd2 "一排副驾座椅加热信号-捷途使用";
CM_ SG_ 1380 ICC_RRSeatHeatLvlCmd2 "二排右座椅加热-捷途使用";
CM_ SG_ 1380 ICC_FRSeatVentLvlCmd2 "副驾座椅通风-捷途使用";
CM_ SG_ 1380 ICC_RRSeatVentLvlCmd2 "二排右座椅通风-捷途使用";
CM_ SG_ 1312 ICC_TotalFaultNum "当前故障总数";
CM_ SG_ 1312 ICC_FrameIndex "帧序号";
CM_ SG_ 1312 ICC_SupplierNum "供应商代码";
CM_ SG_ 1312 ICC_FaultNum1 "故障列表1";
CM_ SG_ 1312 ICC_FaultNum2 "故障列表2";
CM_ SG_ 1312 ICC_FaultNum3 "故障列表3";
CM_ SG_ 1312 ICC_FaultNum4 "故障列表4";
CM_ SG_ 1312 ICC_FaultNum5 "故障列表5";
CM_ SG_ 1312 ICC_FaultNum6 "故障列表6";
CM_ SG_ 1312 ICC_FaultNum7 "故障列表7";
CM_ SG_ 1312 ICC_FaultNum8 "故障列表8";
CM_ SG_ 1312 ICC_FaultNum9 "故障列表9";
CM_ SG_ 1312 ICC_FaultNum10 "故障列表10";
CM_ SG_ 1312 ICC_FaultNum11 "故障列表11";
CM_ SG_ 1312 ICC_FaultNum12 "故障列表12";
CM_ SG_ 1312 ICC_FaultNum13 "故障列表13";
CM_ SG_ 1312 ICC_FaultNum14 "故障列表14";
CM_ SG_ 1312 ICC_FaultNum15 "故障列表15";
CM_ SG_ 1312 ICC_FaultNum16 "故障列表16";
CM_ SG_ 1312 ICC_FaultNum17 "故障列表17";
CM_ SG_ 1312 ICC_FaultNum18 "故障列表18";
CM_ SG_ 1312 ICC_FaultNum19 "故障列表19";
CM_ SG_ 1312 ICC_FaultNum20 "故障列表20";
CM_ SG_ 1560 srcNodeID_ICC "The srcNodeID of IHU is 0x18";
CM_ SG_ 1560 RMR_ICC "If set to 1 to force the network management of all other nodes on the bus into the re-peat message state.";
CM_ SG_ 1560 ICC_Wakeup_Poweron "整车电源档位为on档（KL15硬线）";
CM_ SG_ 1560 ICC_Wakeup_NM "NM报文";
CM_ SG_ 1560 ICC_Wakeup_Diag "Wakeup Source3 Reserved";
CM_ SG_ 1560 ICC_Wakeup_PowerComfortable "整车电源档位为Comfortable档（KL15硬线）";
CM_ SG_ 1560 ICC_Wakeup_HUD "HUD唤醒（0x63E）股份信号，捷途预留";
CM_ SG_ 1560 ICC_Wakeup_EAMP "EAMP唤醒（0x62A）股份信号，捷途预留";
CM_ SG_ 1560 ICC_Awake_Poweron "整车电源档位为on档（KL15硬线）";
CM_ SG_ 1560 ICC_Awake_NM "Awake Reason2 Reserved";
CM_ SG_ 1560 ICC_Awake_DiagETH "接收到本部件相关的以太诊断报文";
CM_ SG_ 1560 ICC_Awake_PowerComfortable "整车电源档位为Comfortable档（KL15硬线）";
CM_ SG_ 1560 ICC_Awake_SentinelMode "哨兵模式激活（股份信号，捷途预留）";
CM_ SG_ 1560 ICC_Awake_PetMode "宠物模式";
CM_ SG_ 1560 ICC_Awake_HUD "HUD维持网络（超时2.5s)股份信号，捷途预留";
CM_ SG_ 1560 ICC_Awake_EAMP "EAMP维持网络（超时2.5s)股份信号，捷途预留";
CM_ SG_ 1560 ICC_Awake_FreezerFunction "冰箱功能激活（股份信号，捷途预留）";
CM_ SG_ 1560 ICC_Awake_PowerOffDelay "退电延迟功能激活";
CM_ SG_ 859 RearDefrostSts "后除霜状态";
CM_ SG_ 1181 FLZCU_9_PowerMode "低压电源状态(由0x27E拆帧)";
CM_ SG_ 1181 FLZCU_9_ArmingSts "整车设防/解防成功状态信号
设防成功0x1,解防成功0x2
设防成功/解放成功后0x1或0x2值连续发送";
CM_ SG_ 1030 RearViewFoldSts "后视镜折叠状态";
CM_ SG_ 1030 FLZCU_AlrmSts "解防设防动作信号";
CM_ SG_ 1030 FLZCU_SteeringMode "个性化-转向模式反馈";
CM_ SG_ 1030 FLZCU_SuspensionDamping "个性化-悬架阻尼反馈";
CM_ SG_ 1030 FLZCU_SuspensionHeight "个性化-悬架高度反馈";
CM_ SG_ 1030 FLZCU_OBDDiagOccupy "OBD诊断占用指示";
CM_ SG_ 1071 FLZCU_AutoFoldSts "后视镜自动折叠状态";
CM_ SG_ 1071 FLZCU_AutolockSts "设置自动落锁模式";
CM_ SG_ 1071 FLZCU_FGHeat_Req_CmdFeedback "前风挡加热反馈信号";
CM_ SG_ 1071 FLZCU_WindowInhibitSts "车窗禁止状态";
CM_ SG_ 1071 FLZCU_AutoReadLightSts "自动顶灯开关状态";
CM_ SG_ 1071 FLZCU_HeatingSW "后视镜加热开关状态";
CM_ SG_ 1071 FLZCU_AutoHeatingFb "雨天后视镜自动加热设置项";
CM_ SG_ 1071 FLZCU_SteerNeedMemory "方向盘停止调节，是否需要记忆";
CM_ SG_ 1071 FLZCU_LowBeamFaults "近光灯故障";
CM_ SG_ 1071 FLZCU_RearNeedMemory "后视镜停止调节，是否需要记忆";
CM_ SG_ 1071 FLZCU_BrkLightFaults "制动灯故障";
CM_ SG_ 1071 FLZCU_TurnLiSwtSts "转向灯开关状态信号（需可自动复位）";
CM_ SG_ 1071 FLZCU_FLHandleFoldedStatus "（股份信号，捷途D01预留）";
CM_ SG_ 1071 FLZCU_RLHandleFoldedStatus "（股份信号，捷途D01预留）";
CM_ SG_ 1071 FLZCU_FRHandleFoldedStatus "（股份信号，捷途D01预留）";
CM_ SG_ 1071 FLZCU_RRHandleFoldedStatus "（股份信号，捷途D01预留）";
CM_ SG_ 1071 FLZCU_RvsExtMirrFbSts "后视镜倒车自动下翻开启关闭";
CM_ SG_ 1071 FLZCU_LightMainSwitchSts "小灯、近光、Auto开关位置";
CM_ SG_ 1071 FLZCU_BeamDelaySts "前照灯延迟时间";
CM_ SG_ 1071 FLZCU_LowBeamHighSts "反馈当前大灯高度调节等级";
CM_ SG_ 1071 FLZCU_WipeSensitivitySts "雨刮灵敏度当前状态";
CM_ SG_ 1071 FLZCU_WipeMaintenanceSWSts "雨刮维修开关当前状态";
CM_ SG_ 1071 FLZCU_HiBeamSwtSts "远光灯开关状态";
CM_ SG_ 1071 FLZCU_ImmoRequest "防盗认证需求";
CM_ SG_ 1071 FLZCU_AlarmWarnSetSW "设防提示设置项";
CM_ SG_ 1071 FLZCU_CleanModeStatus "洗车模式状态反馈给大屏";
CM_ SG_ 1071 FLZCU_FLReleaseLockSts "左前电释放状态
0x0:None
0x1:已释放
0x2:释放中
0x3:已复位
0x4:复位中";
CM_ SG_ 1071 FLZCU_RearFogLightSts "后雾灯状态反馈";
CM_ SG_ 1071 FLZCU_FRFoglightSts "右前雾灯状态反馈";
CM_ SG_ 1071 FLZCU_FLFoglightSts "左前雾灯状态,用于右前雾灯开关判断";
CM_ SG_ 1071 FLZCU_RearFogLightFaults "后雾灯故障";
CM_ SG_ 1071 FLZCU_HighBeamFaults "远光灯故障";
CM_ SG_ 1071 FLZCU_HighBeamSts "远光灯状态";
CM_ SG_ 1071 FLZCU_LowBeamSts "近光灯状态";
CM_ SG_ 1071 FLZCU_ParkUnlockEnableFb "驻车解锁设置反馈";
CM_ SG_ 1071 FLZCU_RLReleaseLockSts "左后电释放状态
0x0:None
0x1:已释放
0x2:释放中
0x3:已复位
0x4:复位中";
CM_ SG_ 1071 FLZCU_EasyEntryExitFb "便捷进入\离车";
CM_ SG_ 1071 FLZCU_EmgyLiSwtSts "紧急报警灯开关";
CM_ SG_ 1071 FLZCU_HMASwSts "IHC激活状态";
CM_ SG_ 1071 FLZCU_DaytimeLight "日行灯状态";
CM_ SG_ 1071 FLZCU_FGHeatFaults "前风挡加热故障";
CM_ SG_ 1071 FLZCU_ParkLightFaults "位置灯故障";
CM_ SG_ 1071 FLZCU_LbatipVehPwrMod "负载限制仪表提示";
CM_ SG_ 1071 FLZCU_LVPowICDsp "低压电池故障仪表指示灯显示";
CM_ SG_ 1071 FLZCU_LockCarWinCloseFb "锁车关窗";
CM_ SG_ 1071 FLZCU_BrkLightSts "制动灯状态";
CM_ SG_ 1071 FLZCU_ReverseLightSts "倒车灯状态";
CM_ SG_ 1071 FLZCU_LowWashLqdWarning "清洗液液位低报警";
CM_ SG_ 1071 FLZCU_SteerWheelHeatingFb "方向盘加热反馈";
CM_ SG_ 1071 FLZCU_FrontFogLightSts "前雾灯状态反馈";
CM_ SG_ 1071 FLZCU_NapAreaFb "小憩模式开启区域设置反馈";
CM_ SG_ 1071 FLZCU_NapTimeFb "小憩模式时长设置反馈";
CM_ SG_ 1071 FLZCU_NapAlarmStatus "小憩模式闹铃提醒";
CM_ SG_ 1071 FLZCU_NapFailCause "小憩模式开启失败原因反馈
0x0:Not Active
0x1:档位非P档
0x2:车速≠0km/h
0x3:前舱盖未关
0x4:后背门未关
0x5:左前门未关
0x6:右前门未关
0x7:左后门未关
0x8:右后门未关
0x9:低压电池电压低，不满足开启条件
0xA:高压电池电量低，不满足开启条件
0xB:制动踏板被踩下，不满足开启条件
0xC:电源档位非Comfortable档，不满足开启条件-捷途特有";
CM_ SG_ 1071 FLZCU_NapStatusFb "小憩模式开关设置反馈";
CM_ SG_ 1071 FLZCU_CleanModeFailCause "洗车模式开启失败提示";
CM_ SG_ 1071 FLZCU_NapClosePrompt "小憩模式关闭提示信号
0x0:Not Active
0x1:低压电池电量低，退出小憩模式
0x2:高压电池电量低，退出小憩模式";
CM_ SG_ 1071 FLZCU_AutoWipingInhibit "洗车模式自动雨刮禁用状态";
CM_ SG_ 1071 FLZCU_RLWinSts "左后车窗运行状态反馈";
CM_ SG_ 1071 FLZCU_FLWinSts "左前车窗运行状态反馈";
CM_ SG_ 1071 FLZCU_DaytimeLightFaults "日行灯故障";
CM_ SG_ 1071 FLZCU_FrontFogLightFaults "前雾灯故障";
CM_ SG_ 1071 FLZCU_HomeLinkWelLightSetSts "HomeLink 迎宾灯设置状态";
CM_ SG_ 1071 FLZCU_HomeLinkArmHornSetSts "HomeLink设防鸣笛设置状态";
CM_ SG_ 1071 FLZCU_WelcomeOpenStas "迎宾灯状态";
CM_ SG_ 1071 FLZCU_WALOpenStas "远离闭锁状态";
CM_ SG_ 1071 FLZCU_UIROpenStas "走近开关状态";
CM_ SG_ 1071 FLZCU_ExtLiSwtClsSts "0x0: Not Active
0x1:外部灯全关
0x2:外部灯未全关";
CM_ SG_ 1409 FLZCU_Totalodometerbackup "总里程备份信号";
CM_ SG_ 1211 FLZCU_FLSeatHeiFb "主驾座椅高度调节目标位置";
CM_ SG_ 1211 FLZCU_FLSeatLvlFb "主驾座椅水平调节目标值";
CM_ SG_ 1211 FLZCU_FLSeatBackAgFb "主驾座椅靠背角度调节目标值";
CM_ SG_ 1211 FLZCU_FLSeatCushFb "主驾座椅坐垫角度调节目标值";
CM_ SG_ 1211 FLZCU_FLSeatLegSpprtFb "主驾座椅腿托";
CM_ SG_ 1211 FLZCU_SeatNeedMemory "主驾座椅记忆弹框请求";
CM_ SG_ 1211 FLZCU_MemoryFb "记忆保存状态";
CM_ SG_ 1211 FLZCU_RecoverFb "记忆恢复状态";
BA_DEF_ BO_  "GenMsgCycleTimeFast" INT 0 50000;
BA_DEF_ BO_  "GenMsgNrOfRepetition" INT 0 999999;
BA_DEF_ BO_  "GenMsgDelayTime" INT 0 1000;
BA_DEF_ BO_  "VFrameFormat" ENUM  "StandardCAN","ExtendedCAN","reserved","reserved","reserved","reserved","reserved","reserved","reserved","reserved","reserved","reserved","reserved","reserved","StandardCAN_FD","ExtendedCAN_FD";
BA_DEF_ BO_  "GenMsgILSupport" ENUM  "No","Yes";
BA_DEF_ BO_  "NmMessage" ENUM  "No","Yes";
BA_DEF_ BO_  "GenMsgSendType" ENUM  "Cycle","Event","IfActive","CE","CA","NoMsgSendType";
BA_DEF_ BO_  "GenMsgCycleTime" INT 0 50000;
BA_DEF_ BO_  "CANFD_BRS" INT 0 1;
BA_DEF_ BO_  "NmAsrMessage" ENUM  "No","Yes";
BA_DEF_ BO_  "GRC_ASIL" ENUM  "vector_leerstring","QM","A","B","C","D";
BA_DEF_ BO_  "GRC_History" STRING ;
BA_DEF_ SG_  "GenSigStartValue" FLOAT 0 100000000000;
BA_DEF_ SG_  "GenSigInactiveValue" INT 0 100000;
BA_DEF_ SG_  "GenSigInvalidValue" INT 0 251610920;
BA_DEF_ SG_  "GenSigSendType" ENUM  "Cycle","OnChange","OnWrite","IfActive","OnChangeWithRepetition","OnWriteWithRepetition","IfActiveWithRepetition","NoSigSendType","OnChangeAndIfActive","OnChangeAndIfActiveWithRepetition","CA","CE","Event";
BA_DEF_ SG_  "GRC_Sig_ASIL" ENUM  "vector_leerstring","QM","A","B","C","D";
BA_DEF_ SG_  "E2EDataId" INT 0 0;
BA_DEF_ SG_  "E2EProfile" STRING ;
BA_DEF_ SG_  "E2EDataLength" INT 0 512;
BA_DEF_DEF_  "GenMsgCycleTimeFast" 0;
BA_DEF_DEF_  "GenMsgNrOfRepetition" 0;
BA_DEF_DEF_  "GenMsgDelayTime" 0;
BA_DEF_DEF_  "VFrameFormat" "StandardCAN";
BA_DEF_DEF_  "GenMsgILSupport" "No";
BA_DEF_DEF_  "NmMessage" "No";
BA_DEF_DEF_  "GenMsgSendType" "NoMsgSendType";
BA_DEF_DEF_  "GenMsgCycleTime" 0;
BA_DEF_DEF_  "CANFD_BRS" 0;
BA_DEF_DEF_  "NmAsrMessage" "No";
BA_DEF_DEF_  "GRC_ASIL" "";
BA_DEF_DEF_  "GRC_History" "";
BA_DEF_DEF_  "GenSigStartValue" 0;
BA_DEF_DEF_  "GenSigInactiveValue" 0;
BA_DEF_DEF_  "GenSigInvalidValue" 0;
BA_DEF_DEF_  "GenSigSendType" "NoSigSendType";
BA_DEF_DEF_  "GRC_Sig_ASIL" "";
BA_DEF_DEF_  "E2EDataId" 0;
BA_DEF_DEF_  "E2EProfile" "";
BA_DEF_DEF_  "E2EDataLength" 0;
BA_ "CANFD_BRS" BO_ 1364 1;
BA_ "GenMsgSendType" BO_ 1364 1;
BA_ "GenMsgCycleTimeFast" BO_ 1364 100;
BA_ "GenMsgDelayTime" BO_ 1364 5;
BA_ "GenMsgILSupport" BO_ 1364 1;
BA_ "VFrameFormat" BO_ 1364 14;
BA_ "CANFD_BRS" BO_ 1366 1;
BA_ "GenMsgSendType" BO_ 1366 3;
BA_ "GenMsgCycleTime" BO_ 1366 100;
BA_ "GenMsgCycleTimeFast" BO_ 1366 20;
BA_ "GenMsgNrOfRepetition" BO_ 1366 2;
BA_ "GenMsgDelayTime" BO_ 1366 5;
BA_ "GenMsgILSupport" BO_ 1366 1;
BA_ "GRC_History" BO_ 1366 "[{'approvedBy':'贾少辉','author':'吴慧','changesComments':'报文快发周期由50ms改为20ms汪苇ADCC需求\n枚举值新增ICC_Customize_buttons信号0x4:HPA记忆泊车','date':'2024/11/22','ecu':'ICC_DA_45(0x556)','ecuName':'ICC','reviewedBy':'杨华','revision':'V2.0'},{'a";
BA_ "VFrameFormat" BO_ 1366 14;
BA_ "CANFD_BRS" BO_ 1354 1;
BA_ "GenMsgSendType" BO_ 1354 1;
BA_ "GenMsgCycleTimeFast" BO_ 1354 100;
BA_ "GenMsgNrOfRepetition" BO_ 1354 2;
BA_ "GenMsgDelayTime" BO_ 1354 5;
BA_ "GenMsgILSupport" BO_ 1354 1;
BA_ "GRC_History" BO_ 1354 "[{'approvedBy':'贾少辉','author':'吴慧','changesComments':'报文名称ICC_CFG_MSG_46更改为ICC_CFG_46','date':'2024/11/21','ecu':'ICC_CFG_46(0x54A)','ecuName':'ICC,SBOX','reviewedBy':'杨华','revision':'V2.0'}]";
BA_ "VFrameFormat" BO_ 1354 14;
BA_ "CANFD_BRS" BO_ 1356 1;
BA_ "GenMsgSendType" BO_ 1356 1;
BA_ "GenMsgCycleTimeFast" BO_ 1356 100;
BA_ "GenMsgNrOfRepetition" BO_ 1356 2;
BA_ "GenMsgDelayTime" BO_ 1356 5;
BA_ "GenMsgILSupport" BO_ 1356 1;
BA_ "GRC_History" BO_ 1356 "[{'approvedBy':'贾少辉','author':'吴慧','changesComments':'报文名称ICC_CFG_PARA_REQ_47更改为ICC_CFG_47\n新增车机自身蓝牙MAC信息，车机MAC字节6个信息','date':'2024/11/21','ecu':'ICC_CFG_47(0x54C)','ecuName':'ICC,SBOX','reviewedBy':'杨华','revision':'V2.0'}";
BA_ "VFrameFormat" BO_ 1356 14;
BA_ "CANFD_BRS" BO_ 1453 1;
BA_ "GenMsgSendType" BO_ 1453 0;
BA_ "GenMsgCycleTime" BO_ 1453 500;
BA_ "GenMsgILSupport" BO_ 1453 1;
BA_ "VFrameFormat" BO_ 1453 14;
BA_ "CANFD_BRS" BO_ 1380 1;
BA_ "GenMsgSendType" BO_ 1380 1;
BA_ "GenMsgCycleTimeFast" BO_ 1380 100;
BA_ "GenMsgNrOfRepetition" BO_ 1380 2;
BA_ "GenMsgDelayTime" BO_ 1380 5;
BA_ "GenMsgILSupport" BO_ 1380 1;
BA_ "VFrameFormat" BO_ 1380 14;
BA_ "CANFD_BRS" BO_ 1395 1;
BA_ "GenMsgSendType" BO_ 1395 0;
BA_ "GenMsgCycleTime" BO_ 1395 1000;
BA_ "GenMsgILSupport" BO_ 1395 1;
BA_ "VFrameFormat" BO_ 1395 14;
BA_ "CANFD_BRS" BO_ 1116 1;
BA_ "GenMsgSendType" BO_ 1116 1;
BA_ "GenMsgILSupport" BO_ 1116 1;
BA_ "VFrameFormat" BO_ 1116 14;
BA_ "CANFD_BRS" BO_ 1151 1;
BA_ "GenMsgSendType" BO_ 1151 1;
BA_ "GenMsgILSupport" BO_ 1151 1;
BA_ "VFrameFormat" BO_ 1151 14;
BA_ "CANFD_BRS" BO_ 1312 1;
BA_ "GenMsgSendType" BO_ 1312 0;
BA_ "GenMsgCycleTime" BO_ 1312 500;
BA_ "GenMsgILSupport" BO_ 1312 1;
BA_ "VFrameFormat" BO_ 1312 14;
BA_ "GenMsgSendType" BO_ 1560 0;
BA_ "GenMsgCycleTime" BO_ 1560 1000;
BA_ "NmMessage" BO_ 1560 1;
BA_ "NmAsrMessage" BO_ 1560 1;
BA_ "CANFD_BRS" BO_ 859 1;
BA_ "GenMsgSendType" BO_ 859 0;
BA_ "GenMsgCycleTime" BO_ 859 50;
BA_ "GenMsgILSupport" BO_ 859 1;
BA_ "GRC_History" BO_ 859 "[{'approvedBy':'贾少辉','author':'吴慧','changesComments':'同步GL网段，补充所有未填写的初始值,补充为0x0','date':'2024/12/13','ecu':'FLZCU_5(0x35B)','ecuName':'ICC,FLZCU','reviewedBy':'杨华','revision':'V2.1'}]";
BA_ "VFrameFormat" BO_ 859 14;
BA_ "CANFD_BRS" BO_ 1181 1;
BA_ "GenMsgSendType" BO_ 1181 0;
BA_ "GenMsgCycleTime" BO_ 1181 100;
BA_ "GenMsgILSupport" BO_ 1181 1;
BA_ "GRC_History" BO_ 1181 "[{'approvedBy':'贾少辉','author':'吴慧','changesComments':'李思思BBCM新增接收E2E信号CRC计数信号','date':'2024/11/1','ecu':'FLZCU_9(0x49D)','ecuName':'FLZCU,BBCM','reviewedBy':'杨华','revision':'V1.3.1'},{'approvedBy':'贾少辉','author':'吴慧','changesComm";
BA_ "VFrameFormat" BO_ 1181 14;
BA_ "CANFD_BRS" BO_ 1030 1;
BA_ "GenMsgSendType" BO_ 1030 0;
BA_ "GenMsgCycleTime" BO_ 1030 100;
BA_ "GenMsgILSupport" BO_ 1030 1;
BA_ "GRC_History" BO_ 1030 "[{'approvedBy':'贾少辉','author':'吴慧','changesComments':'与刘标黄诚刚达成共识：HCU不发送FLZCU_BrakePedalFeelMode信号\nHCU仅发送FLZCU_SteeringMode、FLZCU_SuspensionDamping、FLZCU_SuspensionHeight信号\n与刘标魏睿确认：ICC只收RearViewFoldSts和FLZCU_Steeri";
BA_ "VFrameFormat" BO_ 1030 14;
BA_ "CANFD_BRS" BO_ 1071 1;
BA_ "GenMsgSendType" BO_ 1071 0;
BA_ "GenMsgCycleTime" BO_ 1071 100;
BA_ "GenMsgILSupport" BO_ 1071 1;
BA_ "GRC_History" BO_ 1071 "[{'approvedBy':'贾少辉','author':'吴慧','changesComments':'ICC新增接收FLZCU_CleanModeFailCause边瑾程永芳','date':'2024/11/7','ecu':'FLZCU_15(0x42F)','ecuName':'FLZCU,ICC','reviewedBy':'杨华','revision':'V1.3.1'},{'approvedBy':'贾少辉','author':'吴慧','ch";
BA_ "VFrameFormat" BO_ 1071 14;
BA_ "CANFD_BRS" BO_ 1409 1;
BA_ "GenMsgSendType" BO_ 1409 0;
BA_ "GenMsgCycleTime" BO_ 1409 500;
BA_ "GenMsgILSupport" BO_ 1409 1;
BA_ "VFrameFormat" BO_ 1409 14;
BA_ "CANFD_BRS" BO_ 1211 1;
BA_ "GenMsgSendType" BO_ 1211 0;
BA_ "GenMsgCycleTime" BO_ 1211 100;
BA_ "GenMsgILSupport" BO_ 1211 1;
BA_ "GRC_History" BO_ 1211 "[{'approvedBy':'贾少辉','author':'吴慧','changesComments':'李思思BBCM新增接收FLZCU_FLSeatHeiFb和FLZCU_FLSeatLvlFb和FLZCU_FLSeatBackAgFb和FLZCU_FLSeatCushFb因一、二排座椅会有干涉的区间','date':'2024/12/23','ecu':'FLZCU_26(0x4BB)','ecuName':'FLZCU,BBCM','r";
BA_ "VFrameFormat" BO_ 1211 14;
BA_ "CANFD_BRS" BO_ 1429 1;
BA_ "GenMsgSendType" BO_ 1429 0;
BA_ "GenMsgCycleTime" BO_ 1429 1000;
BA_ "GenMsgILSupport" BO_ 1429 1;
BA_ "VFrameFormat" BO_ 1429 14;
BA_ "GenSigSendType" SG_ 1364 ICC_RISD_FrameCounter 5;
BA_ "GenSigSendType" SG_ 1364 ICC_RISD_RollingCounter 5;
BA_ "GenSigSendType" SG_ 1364 ICC_RISD_Pixel1_OnOff 5;
BA_ "GenSigSendType" SG_ 1364 ICC_RISD_Pixel2_OnOff 5;
BA_ "GenSigSendType" SG_ 1364 ICC_RISD_Pixel3_OnOff 5;
BA_ "GenSigSendType" SG_ 1364 ICC_RISD_Pixel4_OnOff 5;
BA_ "GenSigSendType" SG_ 1364 ICC_RISD_Pixel5_OnOff 5;
BA_ "GenSigSendType" SG_ 1364 ICC_RISD_Pixel6_OnOff 5;
BA_ "GenSigSendType" SG_ 1364 ICC_RISD_Pixel7_OnOff 5;
BA_ "GenSigSendType" SG_ 1364 ICC_RISD_Pixel8_OnOff 5;
BA_ "GenSigSendType" SG_ 1364 ICC_RISD_Pixel9_OnOff 5;
BA_ "GenSigSendType" SG_ 1364 ICC_RISD_Pixel10_OnOff 5;
BA_ "GenSigSendType" SG_ 1364 ICC_RISD_Pixel11_OnOff 5;
BA_ "GenSigSendType" SG_ 1364 ICC_RISD_Pixel12_OnOff 5;
BA_ "GenSigSendType" SG_ 1364 ICC_RISD_Pixel13_OnOff 5;
BA_ "GenSigSendType" SG_ 1364 ICC_RISD_Pixel14_OnOff 5;
BA_ "GenSigSendType" SG_ 1364 ICC_RISD_Pixel15_OnOff 5;
BA_ "GenSigSendType" SG_ 1364 ICC_RISD_Pixel16_OnOff 5;
BA_ "GenSigSendType" SG_ 1364 ICC_RISD_Pixel17_OnOff 5;
BA_ "GenSigSendType" SG_ 1364 ICC_RISD_Pixel18_OnOff 5;
BA_ "GenSigSendType" SG_ 1364 ICC_RISD_Pixel19_OnOff 5;
BA_ "GenSigSendType" SG_ 1364 ICC_RISD_Pixel20_OnOff 5;
BA_ "GenSigSendType" SG_ 1364 ICC_RISD_Pixel21_OnOff 5;
BA_ "GenSigSendType" SG_ 1364 ICC_RISD_Pixel22_OnOff 5;
BA_ "GenSigSendType" SG_ 1364 ICC_RISD_Pixel23_OnOff 5;
BA_ "GenSigSendType" SG_ 1364 ICC_RISD_Pixel24_OnOff 5;
BA_ "GenSigSendType" SG_ 1364 ICC_RISD_Pixel25_OnOff 5;
BA_ "GenSigSendType" SG_ 1364 ICC_RISD_Pixel26_OnOff 5;
BA_ "GenSigSendType" SG_ 1364 ICC_RISD_Pixel27_OnOff 5;
BA_ "GenSigSendType" SG_ 1364 ICC_RISD_Pixel28_OnOff 5;
BA_ "GenSigSendType" SG_ 1364 ICC_RISD_Pixel29_OnOff 5;
BA_ "GenSigSendType" SG_ 1364 ICC_RISD_Pixel30_OnOff 5;
BA_ "GenSigSendType" SG_ 1364 ICC_RISD_Pixel31_OnOff 5;
BA_ "GenSigSendType" SG_ 1364 ICC_RISD_Pixel32_OnOff 5;
BA_ "GenSigSendType" SG_ 1364 ICC_RISD_Pixel33_OnOff 5;
BA_ "GenSigSendType" SG_ 1364 ICC_RISD_Pixel34_OnOff 5;
BA_ "GenSigSendType" SG_ 1364 ICC_RISD_Pixel35_OnOff 5;
BA_ "GenSigSendType" SG_ 1364 ICC_RISD_Pixel36_OnOff 5;
BA_ "GenSigSendType" SG_ 1364 ICC_RISD_Pixel37_OnOff 5;
BA_ "GenSigSendType" SG_ 1364 ICC_RISD_Pixel38_OnOff 5;
BA_ "GenSigSendType" SG_ 1364 ICC_RISD_Pixel39_OnOff 5;
BA_ "GenSigSendType" SG_ 1364 ICC_RISD_Pixel40_OnOff 5;
BA_ "GenSigSendType" SG_ 1364 ICC_RISD_Pixel41_OnOff 5;
BA_ "GenSigSendType" SG_ 1364 ICC_RISD_Pixel42_OnOff 5;
BA_ "GenSigSendType" SG_ 1364 ICC_RISD_Pixel43_OnOff 5;
BA_ "GenSigSendType" SG_ 1364 ICC_RISD_Pixel44_OnOff 5;
BA_ "GenSigSendType" SG_ 1364 ICC_RISD_Pixel45_OnOff 5;
BA_ "GenSigSendType" SG_ 1364 ICC_RISD_Pixel46_OnOff 5;
BA_ "GenSigSendType" SG_ 1364 ICC_RISD_Pixel47_OnOff 5;
BA_ "GenSigSendType" SG_ 1364 ICC_RISD_Pixel48_OnOff 5;
BA_ "GenSigSendType" SG_ 1364 ICC_RISD_Pixel49_OnOff 5;
BA_ "GenSigSendType" SG_ 1364 ICC_RISD_Pixel50_OnOff 5;
BA_ "GenSigSendType" SG_ 1364 ICC_RISD_Pixel51_OnOff 5;
BA_ "GenSigSendType" SG_ 1364 ICC_RISD_Pixel52_OnOff 5;
BA_ "GenSigSendType" SG_ 1364 ICC_RISD_Pixel53_OnOff 5;
BA_ "GenSigSendType" SG_ 1364 ICC_RISD_Pixel54_OnOff 5;
BA_ "GenSigSendType" SG_ 1364 ICC_RISD_Pixel55_OnOff 5;
BA_ "GenSigSendType" SG_ 1364 ICC_RISD_Pixel56_OnOff 5;
BA_ "GenSigSendType" SG_ 1364 ICC_RISD_Pixel57_OnOff 5;
BA_ "GenSigSendType" SG_ 1364 ICC_RISD_Pixel58_OnOff 5;
BA_ "GenSigSendType" SG_ 1364 ICC_RISD_Pixel59_OnOff 5;
BA_ "GenSigSendType" SG_ 1364 ICC_RISD_Pixel60_OnOff 5;
BA_ "GenSigSendType" SG_ 1364 ICC_RISD_Pixel61_OnOff 5;
BA_ "GenSigSendType" SG_ 1364 ICC_RISD_Pixel62_OnOff 5;
BA_ "GenSigSendType" SG_ 1364 ICC_RISD_Pixel63_OnOff 5;
BA_ "GenSigSendType" SG_ 1364 ICC_RISD_Pixel64_OnOff 5;
BA_ "GenSigSendType" SG_ 1364 ICC_RISD_Pixel65_OnOff 5;
BA_ "GenSigSendType" SG_ 1364 ICC_RISD_Pixel66_OnOff 5;
BA_ "GenSigSendType" SG_ 1364 ICC_RISD_Pixel67_OnOff 5;
BA_ "GenSigSendType" SG_ 1364 ICC_RISD_Pixel68_OnOff 5;
BA_ "GenSigSendType" SG_ 1364 ICC_RISD_Pixel69_OnOff 5;
BA_ "GenSigSendType" SG_ 1364 ICC_RISD_Pixel70_OnOff 5;
BA_ "GenSigSendType" SG_ 1364 ICC_RISD_Pixel71_OnOff 5;
BA_ "GenSigSendType" SG_ 1364 ICC_RISD_Pixel72_OnOff 5;
BA_ "GenSigSendType" SG_ 1364 ICC_RISD_Pixel73_OnOff 5;
BA_ "GenSigSendType" SG_ 1364 ICC_RISD_Pixel74_OnOff 5;
BA_ "GenSigSendType" SG_ 1364 ICC_RISD_Pixel75_OnOff 5;
BA_ "GenSigSendType" SG_ 1364 ICC_RISD_Pixel76_OnOff 5;
BA_ "GenSigSendType" SG_ 1364 ICC_RISD_Pixel77_OnOff 5;
BA_ "GenSigSendType" SG_ 1364 ICC_RISD_Pixel78_OnOff 5;
BA_ "GenSigSendType" SG_ 1364 ICC_RISD_Pixel79_OnOff 5;
BA_ "GenSigSendType" SG_ 1364 ICC_RISD_Pixel80_OnOff 5;
BA_ "GenSigSendType" SG_ 1364 ICC_RISD_Pixel81_OnOff 5;
BA_ "GenSigSendType" SG_ 1364 ICC_RISD_Pixel82_OnOff 5;
BA_ "GenSigSendType" SG_ 1364 ICC_RISD_Pixel83_OnOff 5;
BA_ "GenSigSendType" SG_ 1364 ICC_RISD_Pixel84_OnOff 5;
BA_ "GenSigSendType" SG_ 1364 ICC_RISD_Pixel85_OnOff 5;
BA_ "GenSigSendType" SG_ 1364 ICC_RISD_Pixel86_OnOff 5;
BA_ "GenSigSendType" SG_ 1364 ICC_RISD_Pixel87_OnOff 5;
BA_ "GenSigSendType" SG_ 1364 ICC_RISD_Pixel88_OnOff 5;
BA_ "GenSigSendType" SG_ 1364 ICC_RISD_Pixel89_OnOff 5;
BA_ "GenSigSendType" SG_ 1364 ICC_RISD_Pixel90_OnOff 5;
BA_ "GenSigSendType" SG_ 1364 ICC_RISD_Pixel91_OnOff 5;
BA_ "GenSigSendType" SG_ 1364 ICC_RISD_Pixel92_OnOff 5;
BA_ "GenSigSendType" SG_ 1364 ICC_RISD_Pixel93_OnOff 5;
BA_ "GenSigSendType" SG_ 1364 ICC_RISD_Pixel94_OnOff 5;
BA_ "GenSigSendType" SG_ 1364 ICC_RISD_Pixel95_OnOff 5;
BA_ "GenSigSendType" SG_ 1364 ICC_RISD_Pixel96_OnOff 5;
BA_ "GenSigSendType" SG_ 1364 ICC_RISD_Pixel97_OnOff 5;
BA_ "GenSigSendType" SG_ 1364 ICC_RISD_Pixel98_OnOff 5;
BA_ "GenSigSendType" SG_ 1364 ICC_RISD_Pixel99_OnOff 5;
BA_ "GenSigSendType" SG_ 1364 ICC_RISD_Pixel100_OnOff 5;
BA_ "GenSigSendType" SG_ 1364 ICC_RISD_Pixel101_OnOff 5;
BA_ "GenSigSendType" SG_ 1364 ICC_RISD_Pixel102_OnOff 5;
BA_ "GenSigSendType" SG_ 1364 ICC_RISD_Pixel103_OnOff 5;
BA_ "GenSigSendType" SG_ 1364 ICC_RISD_Pixel104_OnOff 5;
BA_ "GenSigSendType" SG_ 1364 ICC_RISD_Pixel105_OnOff 5;
BA_ "GenSigSendType" SG_ 1364 ICC_RISD_Pixel106_OnOff 5;
BA_ "GenSigSendType" SG_ 1364 ICC_RISD_Pixel107_OnOff 5;
BA_ "GenSigSendType" SG_ 1364 ICC_RISD_Pixel108_OnOff 5;
BA_ "GenSigSendType" SG_ 1364 ICC_RISD_Pixel109_OnOff 5;
BA_ "GenSigSendType" SG_ 1364 ICC_RISD_Pixel110_OnOff 5;
BA_ "GenSigSendType" SG_ 1364 ICC_RISD_Pixel111_OnOff 5;
BA_ "GenSigSendType" SG_ 1364 ICC_RISD_Pixel112_OnOff 5;
BA_ "GenSigSendType" SG_ 1364 ICC_RISD_Pixel113_OnOff 5;
BA_ "GenSigSendType" SG_ 1364 ICC_RISD_Pixel114_OnOff 5;
BA_ "GenSigSendType" SG_ 1364 ICC_RISD_Pixel115_OnOff 5;
BA_ "GenSigSendType" SG_ 1364 ICC_RISD_Pixel116_OnOff 5;
BA_ "GenSigSendType" SG_ 1364 ICC_RISD_Pixel117_OnOff 5;
BA_ "GenSigSendType" SG_ 1364 ICC_RISD_Pixel118_OnOff 5;
BA_ "GenSigSendType" SG_ 1364 ICC_RISD_Pixel119_OnOff 5;
BA_ "GenSigSendType" SG_ 1364 ICC_RISD_Pixel120_OnOff 5;
BA_ "GenSigSendType" SG_ 1364 ICC_RISD_Pixel121_OnOff 5;
BA_ "GenSigSendType" SG_ 1364 ICC_RISD_Pixel122_OnOff 5;
BA_ "GenSigSendType" SG_ 1364 ICC_RISD_Pixel123_OnOff 5;
BA_ "GenSigSendType" SG_ 1364 ICC_RISD_Pixel124_OnOff 5;
BA_ "GenSigSendType" SG_ 1364 ICC_RISD_Pixel125_OnOff 5;
BA_ "GenSigSendType" SG_ 1364 ICC_RISD_Pixel126_OnOff 5;
BA_ "GenSigSendType" SG_ 1364 ICC_RISD_Pixel127_OnOff 5;
BA_ "GenSigSendType" SG_ 1364 ICC_RISD_Pixel128_OnOff 5;
BA_ "GenSigSendType" SG_ 1364 ICC_RISD_Pixel129_OnOff 5;
BA_ "GenSigSendType" SG_ 1364 ICC_RISD_Pixel130_OnOff 5;
BA_ "GenSigSendType" SG_ 1364 ICC_RISD_Pixel131_OnOff 5;
BA_ "GenSigSendType" SG_ 1364 ICC_RISD_Pixel132_OnOff 5;
BA_ "GenSigSendType" SG_ 1364 ICC_RISD_Pixel133_OnOff 5;
BA_ "GenSigSendType" SG_ 1364 ICC_RISD_Pixel134_OnOff 5;
BA_ "GenSigSendType" SG_ 1364 ICC_RISD_Pixel135_OnOff 5;
BA_ "GenSigSendType" SG_ 1364 ICC_RISD_Pixel136_OnOff 5;
BA_ "GenSigSendType" SG_ 1364 ICC_RISD_Pixel137_OnOff 5;
BA_ "GenSigSendType" SG_ 1364 ICC_RISD_Pixel138_OnOff 5;
BA_ "GenSigSendType" SG_ 1364 ICC_RISD_Pixel139_OnOff 5;
BA_ "GenSigSendType" SG_ 1364 ICC_RISD_Pixel140_OnOff 5;
BA_ "GenSigSendType" SG_ 1364 ICC_RISD_Pixel141_OnOff 5;
BA_ "GenSigSendType" SG_ 1364 ICC_RISD_Pixel142_OnOff 5;
BA_ "GenSigSendType" SG_ 1364 ICC_RISD_Pixel143_OnOff 5;
BA_ "GenSigSendType" SG_ 1364 ICC_RISD_Pixel144_OnOff 5;
BA_ "GenSigSendType" SG_ 1364 ICC_RISD_Pixel145_OnOff 5;
BA_ "GenSigSendType" SG_ 1364 ICC_RISD_Pixel146_OnOff 5;
BA_ "GenSigSendType" SG_ 1364 ICC_RISD_Pixel147_OnOff 5;
BA_ "GenSigSendType" SG_ 1364 ICC_RISD_Pixel148_OnOff 5;
BA_ "GenSigSendType" SG_ 1364 ICC_RISD_Pixel149_OnOff 5;
BA_ "GenSigSendType" SG_ 1364 ICC_RISD_Pixel150_OnOff 5;
BA_ "GenSigSendType" SG_ 1364 ICC_RISD_Pixel151_OnOff 5;
BA_ "GenSigSendType" SG_ 1364 ICC_RISD_Pixel152_OnOff 5;
BA_ "GenSigSendType" SG_ 1364 ICC_RISD_Pixel153_OnOff 5;
BA_ "GenSigSendType" SG_ 1364 ICC_RISD_Pixel154_OnOff 5;
BA_ "GenSigSendType" SG_ 1364 ICC_RISD_Pixel155_OnOff 5;
BA_ "GenSigSendType" SG_ 1364 ICC_RISD_Pixel156_OnOff 5;
BA_ "GenSigSendType" SG_ 1364 ICC_RISD_Pixel157_OnOff 5;
BA_ "GenSigSendType" SG_ 1364 ICC_RISD_Pixel158_OnOff 5;
BA_ "GenSigSendType" SG_ 1364 ICC_RISD_Pixel159_OnOff 5;
BA_ "GenSigSendType" SG_ 1364 ICC_RISD_Pixel160_OnOff 5;
BA_ "GenSigSendType" SG_ 1364 ICC_RISD_Pixel161_OnOff 5;
BA_ "GenSigSendType" SG_ 1364 ICC_RISD_Pixel162_OnOff 5;
BA_ "GenSigSendType" SG_ 1364 ICC_RISD_Pixel163_OnOff 5;
BA_ "GenSigSendType" SG_ 1364 ICC_RISD_Pixel164_OnOff 5;
BA_ "GenSigSendType" SG_ 1364 ICC_RISD_Pixel165_OnOff 5;
BA_ "GenSigSendType" SG_ 1364 ICC_RISD_Pixel166_OnOff 5;
BA_ "GenSigSendType" SG_ 1364 ICC_RISD_Pixel167_OnOff 5;
BA_ "GenSigSendType" SG_ 1364 ICC_RISD_Pixel168_OnOff 5;
BA_ "GenSigSendType" SG_ 1364 ICC_RISD_Pixel169_OnOff 5;
BA_ "GenSigSendType" SG_ 1364 ICC_RISD_Pixel170_OnOff 5;
BA_ "GenSigSendType" SG_ 1364 ICC_RISD_Pixel171_OnOff 5;
BA_ "GenSigSendType" SG_ 1364 ICC_RISD_Pixel172_OnOff 5;
BA_ "GenSigSendType" SG_ 1364 ICC_RISD_Pixel173_OnOff 5;
BA_ "GenSigSendType" SG_ 1364 ICC_RISD_Pixel174_OnOff 5;
BA_ "GenSigSendType" SG_ 1364 ICC_RISD_Pixel175_OnOff 5;
BA_ "GenSigSendType" SG_ 1364 ICC_RISD_Pixel176_OnOff 5;
BA_ "GenSigSendType" SG_ 1364 ICC_RISD_Pixel177_OnOff 5;
BA_ "GenSigSendType" SG_ 1364 ICC_RISD_Pixel178_OnOff 5;
BA_ "GenSigSendType" SG_ 1364 ICC_RISD_Pixel179_OnOff 5;
BA_ "GenSigSendType" SG_ 1364 ICC_RISD_Pixel180_OnOff 5;
BA_ "GenSigSendType" SG_ 1364 ICC_RISD_Pixel181_OnOff 5;
BA_ "GenSigSendType" SG_ 1364 ICC_RISD_Pixel182_OnOff 5;
BA_ "GenSigSendType" SG_ 1364 ICC_RISD_Pixel183_OnOff 5;
BA_ "GenSigSendType" SG_ 1364 ICC_RISD_Pixel184_OnOff 5;
BA_ "GenSigSendType" SG_ 1364 ICC_RISD_Pixel185_OnOff 5;
BA_ "GenSigSendType" SG_ 1364 ICC_RISD_Pixel186_OnOff 5;
BA_ "GenSigSendType" SG_ 1364 ICC_RISD_Pixel187_OnOff 5;
BA_ "GenSigSendType" SG_ 1364 ICC_RISD_Pixel188_OnOff 5;
BA_ "GenSigSendType" SG_ 1364 ICC_RISD_Pixel189_OnOff 5;
BA_ "GenSigSendType" SG_ 1364 ICC_RISD_Pixel190_OnOff 5;
BA_ "GenSigSendType" SG_ 1364 ICC_RISD_Pixel191_OnOff 5;
BA_ "GenSigSendType" SG_ 1364 ICC_RISD_Pixel192_OnOff 5;
BA_ "GenSigSendType" SG_ 1364 ICC_RISD_Pixel193_OnOff 5;
BA_ "GenSigSendType" SG_ 1364 ICC_RISD_Pixel194_OnOff 5;
BA_ "GenSigSendType" SG_ 1364 ICC_RISD_Pixel195_OnOff 5;
BA_ "GenSigSendType" SG_ 1364 ICC_RISD_Pixel196_OnOff 5;
BA_ "GenSigSendType" SG_ 1364 ICC_RISD_Pixel197_OnOff 5;
BA_ "GenSigSendType" SG_ 1364 ICC_RISD_Pixel198_OnOff 5;
BA_ "GenSigSendType" SG_ 1364 ICC_RISD_Pixel199_OnOff 5;
BA_ "GenSigSendType" SG_ 1364 ICC_RISD_Pixel200_OnOff 5;
BA_ "GenSigSendType" SG_ 1364 ICC_RISD_Pixel201_OnOff 5;
BA_ "GenSigSendType" SG_ 1364 ICC_RISD_Pixel202_OnOff 5;
BA_ "GenSigSendType" SG_ 1364 ICC_RISD_Pixel203_OnOff 5;
BA_ "GenSigSendType" SG_ 1364 ICC_RISD_Pixel204_OnOff 5;
BA_ "GenSigSendType" SG_ 1364 ICC_RISD_Pixel205_OnOff 5;
BA_ "GenSigSendType" SG_ 1364 ICC_RISD_Pixel206_OnOff 5;
BA_ "GenSigSendType" SG_ 1364 ICC_RISD_Pixel207_OnOff 5;
BA_ "GenSigSendType" SG_ 1364 ICC_RISD_Pixel208_OnOff 5;
BA_ "GenSigSendType" SG_ 1364 ICC_RISD_Pixel209_OnOff 5;
BA_ "GenSigSendType" SG_ 1364 ICC_RISD_Pixel210_OnOff 5;
BA_ "GenSigSendType" SG_ 1364 ICC_RISD_Pixel211_OnOff 5;
BA_ "GenSigSendType" SG_ 1364 ICC_RISD_Pixel212_OnOff 5;
BA_ "GenSigSendType" SG_ 1364 ICC_RISD_Pixel213_OnOff 5;
BA_ "GenSigSendType" SG_ 1364 ICC_RISD_Pixel214_OnOff 5;
BA_ "GenSigSendType" SG_ 1364 ICC_RISD_Pixel215_OnOff 5;
BA_ "GenSigSendType" SG_ 1364 ICC_RISD_Pixel216_OnOff 5;
BA_ "GenSigSendType" SG_ 1364 ICC_RISD_Pixel217_OnOff 5;
BA_ "GenSigSendType" SG_ 1364 ICC_RISD_Pixel218_OnOff 5;
BA_ "GenSigSendType" SG_ 1364 ICC_RISD_Pixel219_OnOff 5;
BA_ "GenSigSendType" SG_ 1364 ICC_RISD_Pixel220_OnOff 5;
BA_ "GenSigSendType" SG_ 1364 ICC_RISD_Pixel221_OnOff 5;
BA_ "GenSigSendType" SG_ 1364 ICC_RISD_Pixel222_OnOff 5;
BA_ "GenSigSendType" SG_ 1364 ICC_RISD_Pixel223_OnOff 5;
BA_ "GenSigSendType" SG_ 1364 ICC_RISD_Pixel224_OnOff 5;
BA_ "GenSigSendType" SG_ 1364 ICC_RISD_Pixel225_OnOff 5;
BA_ "GenSigSendType" SG_ 1364 ICC_RISD_Pixel226_OnOff 5;
BA_ "GenSigSendType" SG_ 1364 ICC_RISD_Pixel227_OnOff 5;
BA_ "GenSigSendType" SG_ 1364 ICC_RISD_Pixel228_OnOff 5;
BA_ "GenSigSendType" SG_ 1364 ICC_RISD_Pixel229_OnOff 5;
BA_ "GenSigSendType" SG_ 1364 ICC_RISD_Pixel230_OnOff 5;
BA_ "GenSigSendType" SG_ 1364 ICC_RISD_Pixel231_OnOff 5;
BA_ "GenSigSendType" SG_ 1364 ICC_RISD_Pixel232_OnOff 5;
BA_ "GenSigSendType" SG_ 1364 ICC_RISD_Pixel233_OnOff 5;
BA_ "GenSigSendType" SG_ 1364 ICC_RISD_Pixel234_OnOff 5;
BA_ "GenSigSendType" SG_ 1364 ICC_RISD_Pixel235_OnOff 5;
BA_ "GenSigSendType" SG_ 1364 ICC_RISD_Pixel236_OnOff 5;
BA_ "GenSigSendType" SG_ 1364 ICC_RISD_Pixel237_OnOff 5;
BA_ "GenSigSendType" SG_ 1364 ICC_RISD_Pixel238_OnOff 5;
BA_ "GenSigSendType" SG_ 1364 ICC_RISD_Pixel239_OnOff 5;
BA_ "GenSigSendType" SG_ 1364 ICC_RISD_Pixel240_OnOff 5;
BA_ "GenSigSendType" SG_ 1364 ICC_RISD_Pixel241_OnOff 5;
BA_ "GenSigSendType" SG_ 1364 ICC_RISD_Pixel242_OnOff 5;
BA_ "GenSigSendType" SG_ 1364 ICC_RISD_Pixel243_OnOff 5;
BA_ "GenSigSendType" SG_ 1364 ICC_RISD_Pixel244_OnOff 5;
BA_ "GenSigSendType" SG_ 1364 ICC_RISD_Pixel245_OnOff 5;
BA_ "GenSigSendType" SG_ 1364 ICC_RISD_Pixel246_OnOff 5;
BA_ "GenSigSendType" SG_ 1364 ICC_RISD_Pixel247_OnOff 5;
BA_ "GenSigSendType" SG_ 1364 ICC_RISD_Pixel248_OnOff 5;
BA_ "GenSigSendType" SG_ 1364 ICC_RISD_Pixel249_OnOff 5;
BA_ "GenSigSendType" SG_ 1364 ICC_RISD_Pixel250_OnOff 5;
BA_ "GenSigSendType" SG_ 1364 ICC_RISD_Pixel251_OnOff 5;
BA_ "GenSigSendType" SG_ 1364 ICC_RISD_Pixel252_OnOff 5;
BA_ "GenSigSendType" SG_ 1364 ICC_RISD_Pixel253_OnOff 5;
BA_ "GenSigSendType" SG_ 1364 ICC_RISD_Pixel254_OnOff 5;
BA_ "GenSigSendType" SG_ 1364 ICC_RISD_Pixel255_OnOff 5;
BA_ "GenSigSendType" SG_ 1364 ICC_RISD_Pixel256_OnOff 5;
BA_ "GenSigSendType" SG_ 1364 ICC_RISD_Pixel257_OnOff 5;
BA_ "GenSigSendType" SG_ 1364 ICC_RISD_Pixel258_OnOff 5;
BA_ "GenSigSendType" SG_ 1364 ICC_RISD_Pixel259_OnOff 5;
BA_ "GenSigSendType" SG_ 1364 ICC_RISD_Pixel260_OnOff 5;
BA_ "GenSigSendType" SG_ 1364 ICC_RISD_Pixel261_OnOff 5;
BA_ "GenSigSendType" SG_ 1364 ICC_RISD_Pixel262_OnOff 5;
BA_ "GenSigSendType" SG_ 1364 ICC_RISD_Pixel263_OnOff 5;
BA_ "GenSigSendType" SG_ 1364 ICC_RISD_Pixel264_OnOff 5;
BA_ "GenSigSendType" SG_ 1364 ICC_RISD_Pixel265_OnOff 5;
BA_ "GenSigSendType" SG_ 1364 ICC_RISD_Pixel266_OnOff 5;
BA_ "GenSigSendType" SG_ 1364 ICC_RISD_Pixel267_OnOff 5;
BA_ "GenSigSendType" SG_ 1364 ICC_RISD_Pixel268_OnOff 5;
BA_ "GenSigSendType" SG_ 1364 ICC_RISD_Pixel269_OnOff 5;
BA_ "GenSigSendType" SG_ 1364 ICC_RISD_Pixel270_OnOff 5;
BA_ "GenSigSendType" SG_ 1364 ICC_RISD_Pixel271_OnOff 5;
BA_ "GenSigSendType" SG_ 1364 ICC_RISD_Pixel272_OnOff 5;
BA_ "GenSigSendType" SG_ 1364 ICC_RISD_Pixel273_OnOff 5;
BA_ "GenSigSendType" SG_ 1364 ICC_RISD_Pixel274_OnOff 5;
BA_ "GenSigSendType" SG_ 1364 ICC_RISD_Pixel275_OnOff 5;
BA_ "GenSigSendType" SG_ 1364 ICC_RISD_Pixel276_OnOff 5;
BA_ "GenSigSendType" SG_ 1364 ICC_RISD_Pixel277_OnOff 5;
BA_ "GenSigSendType" SG_ 1364 ICC_RISD_Pixel278_OnOff 5;
BA_ "GenSigSendType" SG_ 1364 ICC_RISD_Pixel279_OnOff 5;
BA_ "GenSigSendType" SG_ 1364 ICC_RISD_Pixel280_OnOff 5;
BA_ "GenSigSendType" SG_ 1364 ICC_RISD_Pixel281_OnOff 5;
BA_ "GenSigSendType" SG_ 1364 ICC_RISD_Pixel282_OnOff 5;
BA_ "GenSigSendType" SG_ 1364 ICC_RISD_Pixel283_OnOff 5;
BA_ "GenSigSendType" SG_ 1364 ICC_RISD_Pixel284_OnOff 5;
BA_ "GenSigSendType" SG_ 1364 ICC_RISD_Pixel285_OnOff 5;
BA_ "GenSigSendType" SG_ 1364 ICC_RISD_Pixel286_OnOff 5;
BA_ "GenSigSendType" SG_ 1364 ICC_RISD_Pixel287_OnOff 5;
BA_ "GenSigSendType" SG_ 1364 ICC_RISD_Pixel288_OnOff 5;
BA_ "GenSigSendType" SG_ 1364 ICC_RISD_Pixel289_OnOff 5;
BA_ "GenSigSendType" SG_ 1364 ICC_RISD_Pixel290_OnOff 5;
BA_ "GenSigSendType" SG_ 1364 ICC_RISD_Pixel291_OnOff 5;
BA_ "GenSigSendType" SG_ 1364 ICC_RISD_Pixel292_OnOff 5;
BA_ "GenSigSendType" SG_ 1364 ICC_RISD_Pixel293_OnOff 5;
BA_ "GenSigSendType" SG_ 1364 ICC_RISD_Pixel294_OnOff 5;
BA_ "GenSigSendType" SG_ 1364 ICC_RISD_Pixel295_OnOff 5;
BA_ "GenSigSendType" SG_ 1364 ICC_RISD_Pixel296_OnOff 5;
BA_ "GenSigSendType" SG_ 1364 ICC_RISD_Pixel297_OnOff 5;
BA_ "GenSigSendType" SG_ 1364 ICC_RISD_Pixel298_OnOff 5;
BA_ "GenSigSendType" SG_ 1364 ICC_RISD_Pixel299_OnOff 5;
BA_ "GenSigSendType" SG_ 1364 ICC_RISD_Pixel300_OnOff 5;
BA_ "GenSigSendType" SG_ 1364 ICC_RISD_Pixel301_OnOff 5;
BA_ "GenSigSendType" SG_ 1364 ICC_RISD_Pixel302_OnOff 5;
BA_ "GenSigSendType" SG_ 1364 ICC_RISD_Pixel303_OnOff 5;
BA_ "GenSigSendType" SG_ 1364 ICC_RISD_Pixel304_OnOff 5;
BA_ "GenSigSendType" SG_ 1364 ICC_RISD_Pixel305_OnOff 5;
BA_ "GenSigSendType" SG_ 1364 ICC_RISD_Pixel306_OnOff 5;
BA_ "GenSigSendType" SG_ 1364 ICC_RISD_Pixel307_OnOff 5;
BA_ "GenSigSendType" SG_ 1364 ICC_RISD_Pixel308_OnOff 5;
BA_ "GenSigSendType" SG_ 1364 ICC_RISD_Pixel309_OnOff 5;
BA_ "GenSigSendType" SG_ 1364 ICC_RISD_Pixel310_OnOff 5;
BA_ "GenSigSendType" SG_ 1364 ICC_RISD_Pixel311_OnOff 5;
BA_ "GenSigSendType" SG_ 1364 ICC_RISD_Pixel312_OnOff 5;
BA_ "GenSigSendType" SG_ 1364 ICC_RISD_Pixel313_OnOff 5;
BA_ "GenSigSendType" SG_ 1364 ICC_RISD_Pixel314_OnOff 5;
BA_ "GenSigSendType" SG_ 1364 ICC_RISD_Pixel315_OnOff 5;
BA_ "GenSigSendType" SG_ 1364 ICC_RISD_Pixel316_OnOff 5;
BA_ "GenSigSendType" SG_ 1364 ICC_RISD_Pixel317_OnOff 5;
BA_ "GenSigSendType" SG_ 1364 ICC_RISD_Pixel318_OnOff 5;
BA_ "GenSigSendType" SG_ 1364 ICC_RISD_Pixel319_OnOff 5;
BA_ "GenSigSendType" SG_ 1364 ICC_RISD_Pixel320_OnOff 5;
BA_ "GenSigSendType" SG_ 1364 ICC_RISD_Pixel321_OnOff 5;
BA_ "GenSigSendType" SG_ 1364 ICC_RISD_Pixel322_OnOff 5;
BA_ "GenSigSendType" SG_ 1364 ICC_RISD_Pixel323_OnOff 5;
BA_ "GenSigSendType" SG_ 1364 ICC_RISD_Pixel324_OnOff 5;
BA_ "GenSigSendType" SG_ 1364 ICC_RISD_Pixel325_OnOff 5;
BA_ "GenSigSendType" SG_ 1364 ICC_RISD_Pixel326_OnOff 5;
BA_ "GenSigSendType" SG_ 1364 ICC_RISD_Pixel327_OnOff 5;
BA_ "GenSigSendType" SG_ 1364 ICC_RISD_Pixel328_OnOff 5;
BA_ "GenSigSendType" SG_ 1364 ICC_RISD_Pixel329_OnOff 5;
BA_ "GenSigSendType" SG_ 1364 ICC_RISD_Pixel330_OnOff 5;
BA_ "GenSigSendType" SG_ 1364 ICC_RISD_Pixel331_OnOff 5;
BA_ "GenSigSendType" SG_ 1364 ICC_RISD_Pixel332_OnOff 5;
BA_ "GenSigSendType" SG_ 1364 ICC_RISD_Pixel333_OnOff 5;
BA_ "GenSigSendType" SG_ 1364 ICC_RISD_Pixel334_OnOff 5;
BA_ "GenSigSendType" SG_ 1364 ICC_RISD_Pixel335_OnOff 5;
BA_ "GenSigSendType" SG_ 1364 ICC_RISD_Pixel336_OnOff 5;
BA_ "GenSigSendType" SG_ 1364 ICC_RISD_Pixel337_OnOff 5;
BA_ "GenSigSendType" SG_ 1364 ICC_RISD_Pixel338_OnOff 5;
BA_ "GenSigSendType" SG_ 1364 ICC_RISD_Pixel339_OnOff 5;
BA_ "GenSigSendType" SG_ 1364 ICC_RISD_Pixel340_OnOff 5;
BA_ "GenSigSendType" SG_ 1364 ICC_RISD_Pixel341_OnOff 5;
BA_ "GenSigSendType" SG_ 1364 ICC_RISD_Pixel342_OnOff 5;
BA_ "GenSigSendType" SG_ 1364 ICC_RISD_Pixel343_OnOff 5;
BA_ "GenSigSendType" SG_ 1364 ICC_RISD_Pixel344_OnOff 5;
BA_ "GenSigSendType" SG_ 1364 ICC_RISD_Pixel345_OnOff 5;
BA_ "GenSigSendType" SG_ 1364 ICC_RISD_Pixel346_OnOff 5;
BA_ "GenSigSendType" SG_ 1364 ICC_RISD_Pixel347_OnOff 5;
BA_ "GenSigSendType" SG_ 1364 ICC_RISD_Pixel348_OnOff 5;
BA_ "GenSigSendType" SG_ 1364 ICC_RISD_Pixel349_OnOff 5;
BA_ "GenSigSendType" SG_ 1364 ICC_RISD_Pixel350_OnOff 5;
BA_ "GenSigSendType" SG_ 1364 ICC_RISD_Pixel351_OnOff 5;
BA_ "GenSigSendType" SG_ 1364 ICC_RISD_Pixel352_OnOff 5;
BA_ "GenSigSendType" SG_ 1364 ICC_RISD_Pixel353_OnOff 5;
BA_ "GenSigSendType" SG_ 1364 ICC_RISD_Pixel354_OnOff 5;
BA_ "GenSigSendType" SG_ 1364 ICC_RISD_Pixel355_OnOff 5;
BA_ "GenSigSendType" SG_ 1364 ICC_RISD_Pixel356_OnOff 5;
BA_ "GenSigSendType" SG_ 1364 ICC_RISD_Pixel357_OnOff 5;
BA_ "GenSigSendType" SG_ 1364 ICC_RISD_Pixel358_OnOff 5;
BA_ "GenSigSendType" SG_ 1364 ICC_RISD_Pixel359_OnOff 5;
BA_ "GenSigSendType" SG_ 1364 ICC_RISD_Pixel360_OnOff 5;
BA_ "GenSigSendType" SG_ 1364 ICC_RISD_Pixel361_OnOff 5;
BA_ "GenSigSendType" SG_ 1364 ICC_RISD_Pixel362_OnOff 5;
BA_ "GenSigSendType" SG_ 1364 ICC_RISD_Pixel363_OnOff 5;
BA_ "GenSigSendType" SG_ 1364 ICC_RISD_Pixel364_OnOff 5;
BA_ "GenSigSendType" SG_ 1364 ICC_RISD_Pixel365_OnOff 5;
BA_ "GenSigSendType" SG_ 1364 ICC_RISD_Pixel366_OnOff 5;
BA_ "GenSigSendType" SG_ 1364 ICC_RISD_Pixel367_OnOff 5;
BA_ "GenSigSendType" SG_ 1364 ICC_RISD_Pixel368_OnOff 5;
BA_ "GenSigSendType" SG_ 1364 ICC_RISD_Pixel369_OnOff 5;
BA_ "GenSigSendType" SG_ 1364 ICC_RISD_Pixel370_OnOff 5;
BA_ "GenSigSendType" SG_ 1364 ICC_RISD_Pixel371_OnOff 5;
BA_ "GenSigSendType" SG_ 1364 ICC_RISD_Pixel372_OnOff 5;
BA_ "GenSigSendType" SG_ 1364 ICC_RISD_Pixel373_OnOff 5;
BA_ "GenSigSendType" SG_ 1364 ICC_RISD_Pixel374_OnOff 5;
BA_ "GenSigSendType" SG_ 1364 ICC_RISD_Pixel375_OnOff 5;
BA_ "GenSigSendType" SG_ 1364 ICC_RISD_Pixel376_OnOff 5;
BA_ "GenSigSendType" SG_ 1364 ICC_RISD_Pixel377_OnOff 5;
BA_ "GenSigSendType" SG_ 1364 ICC_RISD_Pixel378_OnOff 5;
BA_ "GenSigSendType" SG_ 1364 ICC_RISD_Pixel379_OnOff 5;
BA_ "GenSigSendType" SG_ 1364 ICC_RISD_Pixel380_OnOff 5;
BA_ "GenSigSendType" SG_ 1364 ICC_RISD_Pixel381_OnOff 5;
BA_ "GenSigSendType" SG_ 1364 ICC_RISD_Pixel382_OnOff 5;
BA_ "GenSigSendType" SG_ 1364 ICC_RISD_Pixel383_OnOff 5;
BA_ "GenSigSendType" SG_ 1364 ICC_RISD_Pixel384_OnOff 5;
BA_ "GenSigSendType" SG_ 1364 ICC_RISD_Pixel385_OnOff 5;
BA_ "GenSigSendType" SG_ 1364 ICC_RISD_Pixel386_OnOff 5;
BA_ "GenSigSendType" SG_ 1364 ICC_RISD_Pixel387_OnOff 5;
BA_ "GenSigSendType" SG_ 1364 ICC_RISD_Pixel388_OnOff 5;
BA_ "GenSigSendType" SG_ 1364 ICC_RISD_Pixel389_OnOff 5;
BA_ "GenSigSendType" SG_ 1364 ICC_RISD_Pixel390_OnOff 5;
BA_ "GenSigSendType" SG_ 1364 ICC_RISD_Pixel391_OnOff 5;
BA_ "GenSigSendType" SG_ 1364 ICC_RISD_Pixel392_OnOff 5;
BA_ "GenSigSendType" SG_ 1364 ICC_RISD_Pixel393_OnOff 5;
BA_ "GenSigSendType" SG_ 1364 ICC_RISD_Pixel394_OnOff 5;
BA_ "GenSigSendType" SG_ 1364 ICC_RISD_Pixel395_OnOff 5;
BA_ "GenSigSendType" SG_ 1364 ICC_RISD_Pixel396_OnOff 5;
BA_ "GenSigSendType" SG_ 1364 ICC_RISD_Pixel397_OnOff 5;
BA_ "GenSigSendType" SG_ 1364 ICC_RISD_Pixel398_OnOff 5;
BA_ "GenSigSendType" SG_ 1364 ICC_RISD_Pixel399_OnOff 5;
BA_ "GenSigSendType" SG_ 1364 ICC_RISD_Pixel400_OnOff 5;
BA_ "GenSigSendType" SG_ 1364 ICC_RISD_Pixel401_OnOff 5;
BA_ "GenSigSendType" SG_ 1364 ICC_RISD_Pixel402_OnOff 5;
BA_ "GenSigSendType" SG_ 1364 ICC_RISD_Pixel403_OnOff 5;
BA_ "GenSigSendType" SG_ 1364 ICC_RISD_Pixel404_OnOff 5;
BA_ "GenSigSendType" SG_ 1364 ICC_RISD_Pixel405_OnOff 5;
BA_ "GenSigSendType" SG_ 1364 ICC_RISD_Pixel406_OnOff 5;
BA_ "GenSigSendType" SG_ 1364 ICC_RISD_Pixel407_OnOff 5;
BA_ "GenSigSendType" SG_ 1364 ICC_RISD_Pixel408_OnOff 5;
BA_ "GenSigSendType" SG_ 1364 ICC_RISD_Pixel409_OnOff 5;
BA_ "GenSigSendType" SG_ 1364 ICC_RISD_Pixel410_OnOff 5;
BA_ "GenSigSendType" SG_ 1364 ICC_RISD_Pixel411_OnOff 5;
BA_ "GenSigSendType" SG_ 1364 ICC_RISD_Pixel412_OnOff 5;
BA_ "GenSigSendType" SG_ 1364 ICC_RISD_Pixel413_OnOff 5;
BA_ "GenSigSendType" SG_ 1364 ICC_RISD_Pixel414_OnOff 5;
BA_ "GenSigSendType" SG_ 1364 ICC_RISD_Pixel415_OnOff 5;
BA_ "GenSigSendType" SG_ 1364 ICC_RISD_Pixel416_OnOff 5;
BA_ "GenSigSendType" SG_ 1364 ICC_RISD_Pixel417_OnOff 5;
BA_ "GenSigSendType" SG_ 1364 ICC_RISD_Pixel418_OnOff 5;
BA_ "GenSigSendType" SG_ 1364 ICC_RISD_Pixel419_OnOff 5;
BA_ "GenSigSendType" SG_ 1364 ICC_RISD_Pixel420_OnOff 5;
BA_ "GenSigSendType" SG_ 1364 ICC_RISD_Pixel421_OnOff 5;
BA_ "GenSigSendType" SG_ 1364 ICC_RISD_Pixel422_OnOff 5;
BA_ "GenSigSendType" SG_ 1364 ICC_RISD_Pixel423_OnOff 5;
BA_ "GenSigSendType" SG_ 1364 ICC_RISD_Pixel424_OnOff 5;
BA_ "GenSigSendType" SG_ 1364 ICC_RISD_Pixel425_OnOff 5;
BA_ "GenSigSendType" SG_ 1364 ICC_RISD_Pixel426_OnOff 5;
BA_ "GenSigSendType" SG_ 1364 ICC_RISD_Pixel427_OnOff 5;
BA_ "GenSigSendType" SG_ 1364 ICC_RISD_Pixel428_OnOff 5;
BA_ "GenSigSendType" SG_ 1364 ICC_RISD_Pixel429_OnOff 5;
BA_ "GenSigSendType" SG_ 1364 ICC_RISD_Pixel430_OnOff 5;
BA_ "GenSigSendType" SG_ 1364 ICC_RISD_Pixel431_OnOff 5;
BA_ "GenSigSendType" SG_ 1364 ICC_RISD_Pixel432_OnOff 5;
BA_ "GenSigSendType" SG_ 1364 ICC_RISD_Pixel433_OnOff 5;
BA_ "GenSigSendType" SG_ 1364 ICC_RISD_Pixel434_OnOff 5;
BA_ "GenSigSendType" SG_ 1364 ICC_RISD_Pixel435_OnOff 5;
BA_ "GenSigSendType" SG_ 1364 ICC_RISD_Pixel436_OnOff 5;
BA_ "GenSigSendType" SG_ 1364 ICC_RISD_Pixel437_OnOff 5;
BA_ "GenSigSendType" SG_ 1364 ICC_RISD_Pixel438_OnOff 5;
BA_ "GenSigSendType" SG_ 1364 ICC_RISD_Pixel439_OnOff 5;
BA_ "GenSigSendType" SG_ 1364 ICC_RISD_Pixel440_OnOff 5;
BA_ "GenSigSendType" SG_ 1364 ICC_RISD_Pixel441_OnOff 5;
BA_ "GenSigSendType" SG_ 1364 ICC_RISD_Pixel442_OnOff 5;
BA_ "GenSigSendType" SG_ 1364 ICC_RISD_Pixel443_OnOff 5;
BA_ "GenSigSendType" SG_ 1364 ICC_RISD_Pixel444_OnOff 5;
BA_ "GenSigSendType" SG_ 1364 ICC_RISD_Pixel445_OnOff 5;
BA_ "GenSigSendType" SG_ 1364 ICC_RISD_Pixel446_OnOff 5;
BA_ "GenSigSendType" SG_ 1364 ICC_RISD_Pixel447_OnOff 5;
BA_ "GenSigSendType" SG_ 1364 ICC_RISD_Pixel448_OnOff 5;
BA_ "GenSigSendType" SG_ 1364 ICC_RISD_Pixel449_OnOff 5;
BA_ "GenSigSendType" SG_ 1364 ICC_RISD_Pixel450_OnOff 5;
BA_ "GenSigSendType" SG_ 1364 ICC_RISD_Pixel451_OnOff 5;
BA_ "GenSigSendType" SG_ 1364 ICC_RISD_Pixel452_OnOff 5;
BA_ "GenSigSendType" SG_ 1364 ICC_RISD_Pixel453_OnOff 5;
BA_ "GenSigSendType" SG_ 1364 ICC_RISD_Pixel454_OnOff 5;
BA_ "GenSigSendType" SG_ 1364 ICC_RISD_Pixel455_OnOff 5;
BA_ "GenSigSendType" SG_ 1364 ICC_RISD_Pixel456_OnOff 5;
BA_ "GenSigSendType" SG_ 1364 ICC_RISD_Pixel457_OnOff 5;
BA_ "GenSigSendType" SG_ 1364 ICC_RISD_Pixel458_OnOff 5;
BA_ "GenSigSendType" SG_ 1364 ICC_RISD_Pixel459_OnOff 5;
BA_ "GenSigSendType" SG_ 1364 ICC_RISD_Pixel460_OnOff 5;
BA_ "GenSigSendType" SG_ 1364 ICC_RISD_Pixel461_OnOff 5;
BA_ "GenSigSendType" SG_ 1364 ICC_RISD_Pixel462_OnOff 5;
BA_ "GenSigSendType" SG_ 1364 ICC_RISD_Pixel463_OnOff 5;
BA_ "GenSigSendType" SG_ 1364 ICC_RISD_Pixel464_OnOff 5;
BA_ "GenSigSendType" SG_ 1364 ICC_RISD_Pixel465_OnOff 5;
BA_ "GenSigSendType" SG_ 1364 ICC_RISD_Pixel466_OnOff 5;
BA_ "GenSigSendType" SG_ 1364 ICC_RISD_Pixel467_OnOff 5;
BA_ "GenSigSendType" SG_ 1364 ICC_RISD_Pixel468_OnOff 5;
BA_ "GenSigSendType" SG_ 1364 ICC_RISD_Pixel469_OnOff 5;
BA_ "GenSigSendType" SG_ 1364 ICC_RISD_Pixel470_OnOff 5;
BA_ "GenSigSendType" SG_ 1364 ICC_RISD_Pixel471_OnOff 5;
BA_ "GenSigSendType" SG_ 1364 ICC_RISD_Pixel472_OnOff 5;
BA_ "GenSigSendType" SG_ 1364 ICC_RISD_Pixel473_OnOff 5;
BA_ "GenSigSendType" SG_ 1364 ICC_RISD_Pixel474_OnOff 5;
BA_ "GenSigSendType" SG_ 1364 ICC_RISD_Pixel475_OnOff 5;
BA_ "GenSigSendType" SG_ 1364 ICC_RISD_Pixel476_OnOff 5;
BA_ "GenSigSendType" SG_ 1364 ICC_RISD_Pixel477_OnOff 5;
BA_ "GenSigSendType" SG_ 1364 ICC_RISD_Pixel478_OnOff 5;
BA_ "GenSigSendType" SG_ 1364 ICC_RISD_Pixel479_OnOff 5;
BA_ "GenSigSendType" SG_ 1364 ICC_RISD_Pixel480_OnOff 5;
BA_ "GenSigSendType" SG_ 1364 ICC_RISD_Pixel481_OnOff 5;
BA_ "GenSigSendType" SG_ 1364 ICC_RISD_Pixel482_OnOff 5;
BA_ "GenSigSendType" SG_ 1364 ICC_RISD_Pixel483_OnOff 5;
BA_ "GenSigSendType" SG_ 1364 ICC_RISD_Pixel484_OnOff 5;
BA_ "GenSigSendType" SG_ 1364 ICC_RISD_Pixel485_OnOff 5;
BA_ "GenSigSendType" SG_ 1364 ICC_RISD_Pixel486_OnOff 5;
BA_ "GenSigSendType" SG_ 1364 ICC_RISD_Pixel487_OnOff 5;
BA_ "GenSigSendType" SG_ 1364 ICC_RISD_Pixel488_OnOff 5;
BA_ "GenSigSendType" SG_ 1364 ICC_RISD_Pixel489_OnOff 5;
BA_ "GenSigSendType" SG_ 1364 ICC_RISD_Pixel490_OnOff 5;
BA_ "GenSigSendType" SG_ 1364 ICC_RISD_Pixel491_OnOff 5;
BA_ "GenSigSendType" SG_ 1364 ICC_RISD_Pixel492_OnOff 5;
BA_ "GenSigSendType" SG_ 1364 ICC_RISD_Pixel493_OnOff 5;
BA_ "GenSigSendType" SG_ 1364 ICC_RISD_Pixel494_OnOff 5;
BA_ "GenSigSendType" SG_ 1364 ICC_RISD_Pixel495_OnOff 5;
BA_ "GenSigSendType" SG_ 1364 ICC_RISD_Pixel496_OnOff 5;
BA_ "GenSigSendType" SG_ 1364 ICC_RISD_Pixel497_OnOff 5;
BA_ "GenSigSendType" SG_ 1364 ICC_RISD_Pixel498_OnOff 5;
BA_ "GenSigSendType" SG_ 1364 ICC_RISD_Pixel499_OnOff 5;
BA_ "GenSigSendType" SG_ 1364 ICC_RISD_Pixel500_OnOff 5;
BA_ "GenSigSendType" SG_ 1364 ICC_RISD_Pixel501_OnOff 5;
BA_ "GenSigSendType" SG_ 1364 ICC_RISD_Pixel502_OnOff 5;
BA_ "GenSigSendType" SG_ 1364 ICC_RISD_Pixel503_OnOff 5;
BA_ "GenSigSendType" SG_ 1364 ICC_RISD_Pixel504_OnOff 5;
BA_ "GenSigSendType" SG_ 1366 ReservationSentinelReq_556h 5;
BA_ "GenSigInvalidValue" SG_ 1366 TimeToStopSentinelMinutSet_556h 63;
BA_ "GenSigStartValue" SG_ 1366 TimeToStopSentinelMinutSet_556h 62;
BA_ "GenSigSendType" SG_ 1366 TimeToStopSentinelMinutSet_556h 5;
BA_ "GenSigSendType" SG_ 1366 SentinelMode_SensitivityReq_556h 0;
BA_ "GenSigInvalidValue" SG_ 1366 TimeToStopSentinelHourSet_556h 31;
BA_ "GenSigStartValue" SG_ 1366 TimeToStopSentinelHourSet_556h 30;
BA_ "GenSigSendType" SG_ 1366 TimeToStopSentinelHourSet_556h 5;
BA_ "GenSigSendType" SG_ 1366 SentinelModeSwitchReq_556h 5;
BA_ "GenSigInvalidValue" SG_ 1366 TimeToStartSentinelMinutSet_556h 63;
BA_ "GenSigStartValue" SG_ 1366 TimeToStartSentinelMinutSet_556h 62;
BA_ "GenSigSendType" SG_ 1366 TimeToStartSentinelMinutSet_556h 5;
BA_ "GenSigSendType" SG_ 1366 TimeToStartSentinelDaySet_556h 5;
BA_ "GenSigInvalidValue" SG_ 1366 TimeToStartSentinelHourSet_556h 31;
BA_ "GenSigStartValue" SG_ 1366 TimeToStartSentinelHourSet_556h 30;
BA_ "GenSigSendType" SG_ 1366 TimeToStartSentinelHourSet_556h 5;
BA_ "GenSigSendType" SG_ 1366 ICC_LKSSettingModSt 5;
BA_ "GenSigSendType" SG_ 1366 ICC_LDWWarnType 5;
BA_ "GenSigSendType" SG_ 1366 ICC_LDWLDPSnvtySet 5;
BA_ "GenSigSendType" SG_ 1366 ICC_ELKSettingSt 5;
BA_ "GenSigSendType" SG_ 1366 ICC_ICAEnableBtnSts 5;
BA_ "GenSigSendType" SG_ 1366 ICC_FCWSettingSt 5;
BA_ "GenSigSendType" SG_ 1366 ICC_AEBSettingSt 5;
BA_ "GenSigSendType" SG_ 1366 ICC_ISLIWarnMod 5;
BA_ "GenSigSendType" SG_ 1366 ICC_Reset 0;
BA_ "GenSigSendType" SG_ 1366 ICC_Customize_buttons 0;
BA_ "GenSigSendType" SG_ 1366 ICC_AVM_TouchEvt 5;
BA_ "GenSigSendType" SG_ 1366 ICC_AVM_BtnPressInputValueX 5;
BA_ "GenSigInvalidValue" SG_ 1366 ICC_AVM_BtnPressInputValueX 4095;
BA_ "GenSigStartValue" SG_ 1366 ICC_AVM_BtnPressInputValueX 4095;
BA_ "GenSigSendType" SG_ 1366 ICC_AVM_BtnPressInputValueY 5;
BA_ "GenSigInvalidValue" SG_ 1366 ICC_AVM_BtnPressInputValueY 4095;
BA_ "GenSigStartValue" SG_ 1366 ICC_AVM_BtnPressInputValueY 4095;
BA_ "GenSigSendType" SG_ 1354 ICC_SetMsgTotal 2;
BA_ "GenSigSendType" SG_ 1354 ICC_SetMSDTotal 2;
BA_ "GenSigSendType" SG_ 1354 ICC_SetCallTimeThreshold 2;
BA_ "GenSigSendType" SG_ 1354 ICC_SetTodayCallTimeThreshold 2;
BA_ "GenSigSendType" SG_ 1354 ICC_SetCurretnCallTime 2;
BA_ "GenSigSendType" SG_ 1354 ICC_SetCurretnMsgThreshold 2;
BA_ "GenSigSendType" SG_ 1354 ICC_SetMsgTotalThreshold 2;
BA_ "GenSigSendType" SG_ 1354 ICC_SetMsdThreshold 2;
BA_ "GenSigSendType" SG_ 1354 ICC_SetCurrenMsdCnt 2;
BA_ "GenSigSendType" SG_ 1354 ICC_SetCustomMsgThreshold 2;
BA_ "GenSigSendType" SG_ 1354 ICC_SetCurrentCustomMsgCnt 2;
BA_ "GenSigSendType" SG_ 1356 ICC_flag 2;
BA_ "GenSigSendType" SG_ 1356 ICC_ActiveTsp_Req 2;
BA_ "GenSigSendType" SG_ 1356 ICC_ActiveSim_Req 2;
BA_ "GenSigSendType" SG_ 1356 ICC_GetMac_req 2;
BA_ "GenSigSendType" SG_ 1356 ICC_GetIccid_Vin 2;
BA_ "GenSigSendType" SG_ 1356 ICC_GivePlatformNumber_Flag 2;
BA_ "GenSigSendType" SG_ 1356 ICC_Platform_Phonenub1 2;
BA_ "GenSigSendType" SG_ 1356 ICC_Platform_Phonenub2 2;
BA_ "GenSigSendType" SG_ 1356 ICC_Platform_Phonenub3 2;
BA_ "GenSigSendType" SG_ 1356 ICC_Platform_Phonenub4 2;
BA_ "GenSigSendType" SG_ 1356 ICC_Platform_Phonenub5 2;
BA_ "GenSigSendType" SG_ 1356 ICC_Platform_Phonenub6 2;
BA_ "GenSigSendType" SG_ 1356 ICC_Platform_Phonenub7 2;
BA_ "GenSigSendType" SG_ 1356 ICC_Platform_Phonenub8 2;
BA_ "GenSigSendType" SG_ 1356 ICC_Platform_Phonenub9 2;
BA_ "GenSigSendType" SG_ 1356 ICC_Platform_Phonenub10 2;
BA_ "GenSigSendType" SG_ 1356 ICC_Platform_Phonenub11 2;
BA_ "GenSigSendType" SG_ 1356 ICC_Platform_Phonenub12 2;
BA_ "GenSigSendType" SG_ 1356 ICC_Platform_Phonenub13 2;
BA_ "GenSigSendType" SG_ 1356 ICC_Platform_Phonenub14 2;
BA_ "GenSigSendType" SG_ 1356 ICC_Platform_Phonenub15 2;
BA_ "GenSigSendType" SG_ 1356 ICC_Platform_Phonenub16 2;
BA_ "GenSigSendType" SG_ 1356 ICC_Platform_Phonenub17 2;
BA_ "GenSigSendType" SG_ 1356 ICC_Platform_Phonenub18 2;
BA_ "GenSigSendType" SG_ 1356 ICC_Platform_Phonenub19 2;
BA_ "GenSigSendType" SG_ 1356 ICC_Platform_Phonenub20 2;
BA_ "GenSigSendType" SG_ 1356 ICC_Mac_Flag 2;
BA_ "GenSigSendType" SG_ 1356 ICC_Mac0 2;
BA_ "GenSigSendType" SG_ 1356 ICC_Mac1 2;
BA_ "GenSigSendType" SG_ 1356 ICC_Mac2 2;
BA_ "GenSigSendType" SG_ 1356 ICC_Mac3 2;
BA_ "GenSigSendType" SG_ 1356 ICC_Mac4 2;
BA_ "GenSigSendType" SG_ 1356 ICC_Mac5 2;
BA_ "GenSigSendType" SG_ 1453 ICC_CrossBorderMode 0;
BA_ "GenSigSendType" SG_ 1453 ICC_BedStatus 0;
BA_ "GenSigSendType" SG_ 1453 ICC_MemAttributeFL 0;
BA_ "GenSigSendType" SG_ 1453 ICC_MemAttributeFR 0;
BA_ "GenSigSendType" SG_ 1453 ICC_MemAttributeRL 0;
BA_ "GenSigSendType" SG_ 1453 ICC_MemAttributeRR 0;
BA_ "GenSigSendType" SG_ 1380 ICC_3rd_FRSeatBackAgtargetCmd 5;
BA_ "GenSigSendType" SG_ 1380 ICC_3rd_FLSeatBackAgtargetCmd 5;
BA_ "GenSigSendType" SG_ 1380 ICC_2nd_FRSeatLegSpprttargetCmd 5;
BA_ "GenSigSendType" SG_ 1380 ICC_2nd_FRSeatBackAgtargetCmd 5;
BA_ "GenSigSendType" SG_ 1380 ICC_2nd_FRSeatLvltargetCmd 5;
BA_ "GenSigSendType" SG_ 1380 ICC_2nd_FLSeatBackAgtargetCmd 5;
BA_ "GenSigSendType" SG_ 1380 ICC_2nd_FLSeatLvltargetCmd 5;
BA_ "GenSigSendType" SG_ 1380 ICC_QueenSeatSwitch 5;
BA_ "GenSigSendType" SG_ 1380 ICC_3rd_FRFrontFlipSwitch 5;
BA_ "GenSigSendType" SG_ 1380 ICC_3rd_FREnjoyableSeatSwitch 5;
BA_ "GenSigSendType" SG_ 1380 ICC_3rd_FLFrontFlipSwitch 5;
BA_ "GenSigSendType" SG_ 1380 ICC_3rd_FLEnjoyableSeatSwitch 5;
BA_ "GenSigSendType" SG_ 1380 ICC_2nd_FREnjoyableSeatSwitch 5;
BA_ "GenSigSendType" SG_ 1380 ICC_FRSeatliedownCmd2 5;
BA_ "GenSigSendType" SG_ 1380 ICC_FLSeatHeatLvlCmd2 5;
BA_ "GenSigSendType" SG_ 1380 ICC_RLSeatHeatLvlCmd2 5;
BA_ "GenSigSendType" SG_ 1380 ICC_FLSeatVentLvlCmd2 5;
BA_ "GenSigSendType" SG_ 1380 ICC_RLSeatVentLvlCmd2 5;
BA_ "GenSigSendType" SG_ 1380 ICC_FRSeatHeatLvlCmd2 5;
BA_ "GenSigSendType" SG_ 1380 ICC_RRSeatHeatLvlCmd2 5;
BA_ "GenSigSendType" SG_ 1380 ICC_FRSeatVentLvlCmd2 5;
BA_ "GenSigSendType" SG_ 1380 ICC_RRSeatVentLvlCmd2 5;
BA_ "GenSigSendType" SG_ 1395 ICC_VINcode_10 0;
BA_ "GenSigInvalidValue" SG_ 1395 ICC_VINcode_10 255;
BA_ "GenSigSendType" SG_ 1395 ICC_VINcode_11 0;
BA_ "GenSigInvalidValue" SG_ 1395 ICC_VINcode_11 255;
BA_ "GenSigSendType" SG_ 1395 ICC_VINcode_12 0;
BA_ "GenSigInvalidValue" SG_ 1395 ICC_VINcode_12 255;
BA_ "GenSigSendType" SG_ 1395 ICC_VINcode_13 0;
BA_ "GenSigInvalidValue" SG_ 1395 ICC_VINcode_13 255;
BA_ "GenSigSendType" SG_ 1395 ICC_VINcode_14 0;
BA_ "GenSigInvalidValue" SG_ 1395 ICC_VINcode_14 255;
BA_ "GenSigSendType" SG_ 1395 ICC_VINcode_15 0;
BA_ "GenSigInvalidValue" SG_ 1395 ICC_VINcode_15 255;
BA_ "GenSigSendType" SG_ 1395 ICC_VINcode_16 0;
BA_ "GenSigInvalidValue" SG_ 1395 ICC_VINcode_16 255;
BA_ "GenSigSendType" SG_ 1395 ICC_VINcode_17 0;
BA_ "GenSigInvalidValue" SG_ 1395 ICC_VINcode_17 255;
BA_ "GenSigSendType" SG_ 1116 ICC_Auth_IMMO 2;
BA_ "GenSigSendType" SG_ 1151 VCC_Teach_IMMO 2;
BA_ "GenSigSendType" SG_ 1312 ICC_TotalFaultNum 0;
BA_ "GenSigSendType" SG_ 1312 ICC_FrameIndex 0;
BA_ "GenSigSendType" SG_ 1312 ICC_SupplierNum 0;
BA_ "GenSigSendType" SG_ 1312 ICC_FaultNum1 0;
BA_ "GenSigSendType" SG_ 1312 ICC_FaultNum2 0;
BA_ "GenSigSendType" SG_ 1312 ICC_FaultNum3 0;
BA_ "GenSigSendType" SG_ 1312 ICC_FaultNum4 0;
BA_ "GenSigSendType" SG_ 1312 ICC_FaultNum5 0;
BA_ "GenSigSendType" SG_ 1312 ICC_FaultNum6 0;
BA_ "GenSigSendType" SG_ 1312 ICC_FaultNum7 0;
BA_ "GenSigSendType" SG_ 1312 ICC_FaultNum8 0;
BA_ "GenSigSendType" SG_ 1312 ICC_FaultNum9 0;
BA_ "GenSigSendType" SG_ 1312 ICC_FaultNum10 0;
BA_ "GenSigSendType" SG_ 1312 ICC_FaultNum11 0;
BA_ "GenSigSendType" SG_ 1312 ICC_FaultNum12 0;
BA_ "GenSigSendType" SG_ 1312 ICC_FaultNum13 0;
BA_ "GenSigSendType" SG_ 1312 ICC_FaultNum14 0;
BA_ "GenSigSendType" SG_ 1312 ICC_FaultNum15 0;
BA_ "GenSigSendType" SG_ 1312 ICC_FaultNum16 0;
BA_ "GenSigSendType" SG_ 1312 ICC_FaultNum17 0;
BA_ "GenSigSendType" SG_ 1312 ICC_FaultNum18 0;
BA_ "GenSigSendType" SG_ 1312 ICC_FaultNum19 0;
BA_ "GenSigSendType" SG_ 1312 ICC_FaultNum20 0;
BA_ "GenSigSendType" SG_ 1560 srcNodeID_ICC 0;
BA_ "GenSigStartValue" SG_ 1560 srcNodeID_ICC 24;
BA_ "GenSigSendType" SG_ 1560 RMR_ICC 0;
BA_ "GenSigSendType" SG_ 1560 NMm_ICC_Reserved1 0;
BA_ "GenSigSendType" SG_ 1560 ICC_Wakeup_Poweron 0;
BA_ "GenSigSendType" SG_ 1560 ICC_Wakeup_NM 0;
BA_ "GenSigSendType" SG_ 1560 ICC_Wakeup_Diag 0;
BA_ "GenSigSendType" SG_ 1560 ICC_Wakeup_PowerComfortable 0;
BA_ "GenSigSendType" SG_ 1560 ICC_Wakeup_HUD 0;
BA_ "GenSigSendType" SG_ 1560 ICC_Wakeup_EAMP 0;
BA_ "GenSigSendType" SG_ 1560 ICC_Awake_Poweron 0;
BA_ "GenSigSendType" SG_ 1560 ICC_Awake_NM 0;
BA_ "GenSigSendType" SG_ 1560 ICC_Awake_DiagETH 0;
BA_ "GenSigSendType" SG_ 1560 ICC_Awake_PowerComfortable 0;
BA_ "GenSigSendType" SG_ 1560 ICC_Awake_SentinelMode 0;
BA_ "GenSigSendType" SG_ 1560 ICC_Awake_PetMode 0;
BA_ "GenSigSendType" SG_ 1560 ICC_Awake_HUD 0;
BA_ "GenSigSendType" SG_ 1560 ICC_Awake_EAMP 0;
BA_ "GenSigSendType" SG_ 1560 ICC_Awake_FreezerFunction 0;
BA_ "GenSigSendType" SG_ 1560 ICC_Awake_PowerOffDelay 0;
BA_ "GenSigSendType" SG_ 859 RearDefrostSts 0;
BA_ "GRC_Sig_ASIL" SG_ 1181 FLZCU_9_PowerMode 3;
BA_ "GenSigSendType" SG_ 1181 FLZCU_9_PowerMode 0;
BA_ "GenSigSendType" SG_ 1181 FLZCU_9_ArmingSts 0;
BA_ "GRC_Sig_ASIL" SG_ 1030 RearViewFoldSts 3;
BA_ "GenSigSendType" SG_ 1030 RearViewFoldSts 0;
BA_ "GenSigSendType" SG_ 1030 FLZCU_AlrmSts 0;
BA_ "GenSigSendType" SG_ 1030 FLZCU_SteeringMode 0;
BA_ "GenSigSendType" SG_ 1030 FLZCU_SuspensionDamping 0;
BA_ "GenSigSendType" SG_ 1030 FLZCU_SuspensionHeight 0;
BA_ "GenSigSendType" SG_ 1030 FLZCU_OBDDiagOccupy 0;
BA_ "GenSigSendType" SG_ 1071 FLZCU_AutoFoldSts 0;
BA_ "GenSigSendType" SG_ 1071 FLZCU_AutolockSts 0;
BA_ "GenSigSendType" SG_ 1071 FLZCU_FGHeat_Req_CmdFeedback 0;
BA_ "GenSigSendType" SG_ 1071 FLZCU_WindowInhibitSts 0;
BA_ "GenSigSendType" SG_ 1071 FLZCU_AutoReadLightSts 0;
BA_ "GenSigSendType" SG_ 1071 FLZCU_HeatingSW 0;
BA_ "GenSigSendType" SG_ 1071 FLZCU_AutoHeatingFb 0;
BA_ "GenSigSendType" SG_ 1071 FLZCU_SteerNeedMemory 0;
BA_ "GenSigSendType" SG_ 1071 FLZCU_LowBeamFaults 0;
BA_ "GenSigSendType" SG_ 1071 FLZCU_RearNeedMemory 0;
BA_ "GenSigSendType" SG_ 1071 FLZCU_BrkLightFaults 0;
BA_ "GenSigSendType" SG_ 1071 FLZCU_TurnLiSwtSts 0;
BA_ "GenSigSendType" SG_ 1071 FLZCU_FLHandleFoldedStatus 0;
BA_ "GenSigSendType" SG_ 1071 FLZCU_RLHandleFoldedStatus 0;
BA_ "GenSigSendType" SG_ 1071 FLZCU_FRHandleFoldedStatus 0;
BA_ "GenSigSendType" SG_ 1071 FLZCU_RRHandleFoldedStatus 0;
BA_ "GenSigSendType" SG_ 1071 FLZCU_RvsExtMirrFbSts 0;
BA_ "GenSigSendType" SG_ 1071 FLZCU_LightMainSwitchSts 0;
BA_ "GenSigSendType" SG_ 1071 FLZCU_BeamDelaySts 0;
BA_ "GenSigSendType" SG_ 1071 FLZCU_LowBeamHighSts 0;
BA_ "GenSigSendType" SG_ 1071 FLZCU_WipeSensitivitySts 0;
BA_ "GenSigSendType" SG_ 1071 FLZCU_WipeMaintenanceSWSts 0;
BA_ "GenSigSendType" SG_ 1071 FLZCU_HiBeamSwtSts 0;
BA_ "GenSigSendType" SG_ 1071 FLZCU_ImmoRequest 0;
BA_ "GenSigSendType" SG_ 1071 FLZCU_AlarmWarnSetSW 0;
BA_ "GenSigSendType" SG_ 1071 FLZCU_CleanModeStatus 0;
BA_ "GenSigSendType" SG_ 1071 FLZCU_FLReleaseLockSts 0;
BA_ "GenSigSendType" SG_ 1071 FLZCU_RearFogLightSts 0;
BA_ "GenSigSendType" SG_ 1071 FLZCU_FRFoglightSts 0;
BA_ "GenSigSendType" SG_ 1071 FLZCU_FLFoglightSts 0;
BA_ "GenSigSendType" SG_ 1071 FLZCU_RearFogLightFaults 0;
BA_ "GenSigSendType" SG_ 1071 FLZCU_HighBeamFaults 0;
BA_ "GenSigSendType" SG_ 1071 FLZCU_HighBeamSts 0;
BA_ "GenSigSendType" SG_ 1071 FLZCU_LowBeamSts 0;
BA_ "GenSigSendType" SG_ 1071 FLZCU_ParkUnlockEnableFb 0;
BA_ "GenSigSendType" SG_ 1071 FLZCU_RLReleaseLockSts 0;
BA_ "GenSigSendType" SG_ 1071 FLZCU_EasyEntryExitFb 0;
BA_ "GenSigSendType" SG_ 1071 FLZCU_EmgyLiSwtSts 0;
BA_ "GenSigSendType" SG_ 1071 FLZCU_HMASwSts 0;
BA_ "GenSigSendType" SG_ 1071 FLZCU_DaytimeLight 0;
BA_ "GenSigSendType" SG_ 1071 FLZCU_FGHeatFaults 0;
BA_ "GenSigSendType" SG_ 1071 FLZCU_ParkLightFaults 0;
BA_ "GenSigSendType" SG_ 1071 FLZCU_LbatipVehPwrMod 0;
BA_ "GenSigSendType" SG_ 1071 FLZCU_LVPowICDsp 0;
BA_ "GenSigSendType" SG_ 1071 FLZCU_LockCarWinCloseFb 0;
BA_ "GenSigSendType" SG_ 1071 FLZCU_BrkLightSts 0;
BA_ "GenSigSendType" SG_ 1071 FLZCU_ReverseLightSts 0;
BA_ "GenSigSendType" SG_ 1071 FLZCU_LowWashLqdWarning 0;
BA_ "GenSigSendType" SG_ 1071 FLZCU_SteerWheelHeatingFb 0;
BA_ "GenSigSendType" SG_ 1071 FLZCU_FrontFogLightSts 0;
BA_ "GenSigSendType" SG_ 1071 FLZCU_NapAreaFb 0;
BA_ "GenSigSendType" SG_ 1071 FLZCU_NapTimeFb 0;
BA_ "GenSigSendType" SG_ 1071 FLZCU_NapAlarmStatus 0;
BA_ "GenSigSendType" SG_ 1071 FLZCU_NapFailCause 0;
BA_ "GenSigSendType" SG_ 1071 FLZCU_NapStatusFb 0;
BA_ "GenSigSendType" SG_ 1071 FLZCU_CleanModeFailCause 0;
BA_ "GenSigSendType" SG_ 1071 FLZCU_NapClosePrompt 0;
BA_ "GenSigSendType" SG_ 1071 FLZCU_AutoWipingInhibit 0;
BA_ "GenSigSendType" SG_ 1071 FLZCU_RLWinSts 0;
BA_ "GenSigSendType" SG_ 1071 FLZCU_FLWinSts 0;
BA_ "GenSigSendType" SG_ 1071 FLZCU_DaytimeLightFaults 0;
BA_ "GenSigSendType" SG_ 1071 FLZCU_FrontFogLightFaults 0;
BA_ "GenSigSendType" SG_ 1071 FLZCU_HomeLinkWelLightSetSts 0;
BA_ "GenSigSendType" SG_ 1071 FLZCU_HomeLinkArmHornSetSts 0;
BA_ "GenSigSendType" SG_ 1071 FLZCU_WelcomeOpenStas 0;
BA_ "GenSigSendType" SG_ 1071 FLZCU_WALOpenStas 0;
BA_ "GenSigSendType" SG_ 1071 FLZCU_UIROpenStas 0;
BA_ "GenSigStartValue" SG_ 1071 FLZCU_UIROpenStas 1;
BA_ "GenSigSendType" SG_ 1071 FLZCU_ExtLiSwtClsSts 0;
BA_ "GenSigInvalidValue" SG_ 1409 FLZCU_EVodometerbackup 16777215;
BA_ "GenSigSendType" SG_ 1409 FLZCU_EVodometerbackup 0;
BA_ "GenSigSendType" SG_ 1409 FLZCU_Totalodometerbackup 0;
BA_ "GenSigInvalidValue" SG_ 1409 FLZCU_Totalodometerbackup 16777215;
BA_ "GenSigSendType" SG_ 1211 FLZCU_DriverSeatMovFailCause 0;
BA_ "GenSigSendType" SG_ 1211 FLZCU_FLSeatHeiFb 0;
BA_ "GenSigInvalidValue" SG_ 1211 FLZCU_FLSeatHeiFb 127;
BA_ "GenSigSendType" SG_ 1211 FLZCU_FLSeatLvlFb 0;
BA_ "GenSigInvalidValue" SG_ 1211 FLZCU_FLSeatLvlFb 127;
BA_ "GenSigSendType" SG_ 1211 FLZCU_FLSeatBackAgFb 0;
BA_ "GenSigInvalidValue" SG_ 1211 FLZCU_FLSeatBackAgFb 127;
BA_ "GenSigSendType" SG_ 1211 FLZCU_FLSeatCushFb 0;
BA_ "GenSigInvalidValue" SG_ 1211 FLZCU_FLSeatCushFb 127;
BA_ "GenSigSendType" SG_ 1211 FLZCU_FLSeatLegSpprtFb 0;
BA_ "GenSigInvalidValue" SG_ 1211 FLZCU_FLSeatLegSpprtFb 127;
BA_ "GenSigSendType" SG_ 1211 FLZCU_SeatNeedMemory 0;
BA_ "GenSigSendType" SG_ 1211 FLZCU_MemoryFb 0;
BA_ "GenSigSendType" SG_ 1211 FLZCU_RecoverFb 0;
BA_ "GenSigSendType" SG_ 1429 FLZCU_VINcode_10 0;
BA_ "GenSigInvalidValue" SG_ 1429 FLZCU_VINcode_10 255;
BA_ "GenSigSendType" SG_ 1429 FLZCU_VINcode_11 0;
BA_ "GenSigInvalidValue" SG_ 1429 FLZCU_VINcode_11 255;
BA_ "GenSigSendType" SG_ 1429 FLZCU_VINcode_12 0;
BA_ "GenSigInvalidValue" SG_ 1429 FLZCU_VINcode_12 255;
BA_ "GenSigSendType" SG_ 1429 FLZCU_VINcode_13 0;
BA_ "GenSigInvalidValue" SG_ 1429 FLZCU_VINcode_13 255;
BA_ "GenSigSendType" SG_ 1429 FLZCU_VINcode_14 0;
BA_ "GenSigInvalidValue" SG_ 1429 FLZCU_VINcode_14 255;
BA_ "GenSigSendType" SG_ 1429 FLZCU_VINcode_15 0;
BA_ "GenSigInvalidValue" SG_ 1429 FLZCU_VINcode_15 255;
BA_ "GenSigSendType" SG_ 1429 FLZCU_VINcode_16 0;
BA_ "GenSigInvalidValue" SG_ 1429 FLZCU_VINcode_16 255;
BA_ "GenSigSendType" SG_ 1429 FLZCU_VINcode_17 0;
BA_ "GenSigInvalidValue" SG_ 1429 FLZCU_VINcode_17 255;
VAL_ 1364 ICC_RISD_FrameCounter 0 "FrameCounter 0" 1 "FrameCounter 1" 2 "FrameCounter 2" 3 "FrameCounter 3" ;
VAL_ 1364 ICC_RISD_RollingCounter 0 "Counter 0" 1 "Counter 1" 2 "Counter 2" ;
VAL_ 1364 ICC_RISD_Pixel1_OnOff 0 "Pixel On" 1 "Pixel Off" ;
VAL_ 1364 ICC_RISD_Pixel2_OnOff 0 "Pixel On" 1 "Pixel Off" ;
VAL_ 1364 ICC_RISD_Pixel3_OnOff 0 "Pixel On" 1 "Pixel Off" ;
VAL_ 1364 ICC_RISD_Pixel4_OnOff 0 "Pixel On" 1 "Pixel Off" ;
VAL_ 1364 ICC_RISD_Pixel5_OnOff 0 "Pixel On" 1 "Pixel Off" ;
VAL_ 1364 ICC_RISD_Pixel6_OnOff 0 "Pixel On" 1 "Pixel Off" ;
VAL_ 1364 ICC_RISD_Pixel7_OnOff 0 "Pixel On" 1 "Pixel Off" ;
VAL_ 1364 ICC_RISD_Pixel8_OnOff 0 "Pixel On" 1 "Pixel Off" ;
VAL_ 1364 ICC_RISD_Pixel9_OnOff 0 "Pixel On" 1 "Pixel Off" ;
VAL_ 1364 ICC_RISD_Pixel10_OnOff 0 "Pixel On" 1 "Pixel Off" ;
VAL_ 1364 ICC_RISD_Pixel11_OnOff 0 "Pixel On" 1 "Pixel Off" ;
VAL_ 1364 ICC_RISD_Pixel12_OnOff 0 "Pixel On" 1 "Pixel Off" ;
VAL_ 1364 ICC_RISD_Pixel13_OnOff 0 "Pixel On" 1 "Pixel Off" ;
VAL_ 1364 ICC_RISD_Pixel14_OnOff 0 "Pixel On" 1 "Pixel Off" ;
VAL_ 1364 ICC_RISD_Pixel15_OnOff 0 "Pixel On" 1 "Pixel Off" ;
VAL_ 1364 ICC_RISD_Pixel16_OnOff 0 "Pixel On" 1 "Pixel Off" ;
VAL_ 1364 ICC_RISD_Pixel17_OnOff 0 "Pixel On" 1 "Pixel Off" ;
VAL_ 1364 ICC_RISD_Pixel18_OnOff 0 "Pixel On" 1 "Pixel Off" ;
VAL_ 1364 ICC_RISD_Pixel19_OnOff 0 "Pixel On" 1 "Pixel Off" ;
VAL_ 1364 ICC_RISD_Pixel20_OnOff 0 "Pixel On" 1 "Pixel Off" ;
VAL_ 1364 ICC_RISD_Pixel21_OnOff 0 "Pixel On" 1 "Pixel Off" ;
VAL_ 1364 ICC_RISD_Pixel22_OnOff 0 "Pixel On" 1 "Pixel Off" ;
VAL_ 1364 ICC_RISD_Pixel23_OnOff 0 "Pixel On" 1 "Pixel Off" ;
VAL_ 1364 ICC_RISD_Pixel24_OnOff 0 "Pixel On" 1 "Pixel Off" ;
VAL_ 1364 ICC_RISD_Pixel25_OnOff 0 "Pixel On" 1 "Pixel Off" ;
VAL_ 1364 ICC_RISD_Pixel26_OnOff 0 "Pixel On" 1 "Pixel Off" ;
VAL_ 1364 ICC_RISD_Pixel27_OnOff 0 "Pixel On" 1 "Pixel Off" ;
VAL_ 1364 ICC_RISD_Pixel28_OnOff 0 "Pixel On" 1 "Pixel Off" ;
VAL_ 1364 ICC_RISD_Pixel29_OnOff 0 "Pixel On" 1 "Pixel Off" ;
VAL_ 1364 ICC_RISD_Pixel30_OnOff 0 "Pixel On" 1 "Pixel Off" ;
VAL_ 1364 ICC_RISD_Pixel31_OnOff 0 "Pixel On" 1 "Pixel Off" ;
VAL_ 1364 ICC_RISD_Pixel32_OnOff 0 "Pixel On" 1 "Pixel Off" ;
VAL_ 1364 ICC_RISD_Pixel33_OnOff 0 "Pixel On" 1 "Pixel Off" ;
VAL_ 1364 ICC_RISD_Pixel34_OnOff 0 "Pixel On" 1 "Pixel Off" ;
VAL_ 1364 ICC_RISD_Pixel35_OnOff 0 "Pixel On" 1 "Pixel Off" ;
VAL_ 1364 ICC_RISD_Pixel36_OnOff 0 "Pixel On" 1 "Pixel Off" ;
VAL_ 1364 ICC_RISD_Pixel37_OnOff 0 "Pixel On" 1 "Pixel Off" ;
VAL_ 1364 ICC_RISD_Pixel38_OnOff 0 "Pixel On" 1 "Pixel Off" ;
VAL_ 1364 ICC_RISD_Pixel39_OnOff 0 "Pixel On" 1 "Pixel Off" ;
VAL_ 1364 ICC_RISD_Pixel40_OnOff 0 "Pixel On" 1 "Pixel Off" ;
VAL_ 1364 ICC_RISD_Pixel41_OnOff 0 "Pixel On" 1 "Pixel Off" ;
VAL_ 1364 ICC_RISD_Pixel42_OnOff 0 "Pixel On" 1 "Pixel Off" ;
VAL_ 1364 ICC_RISD_Pixel43_OnOff 0 "Pixel On" 1 "Pixel Off" ;
VAL_ 1364 ICC_RISD_Pixel44_OnOff 0 "Pixel On" 1 "Pixel Off" ;
VAL_ 1364 ICC_RISD_Pixel45_OnOff 0 "Pixel On" 1 "Pixel Off" ;
VAL_ 1364 ICC_RISD_Pixel46_OnOff 0 "Pixel On" 1 "Pixel Off" ;
VAL_ 1364 ICC_RISD_Pixel47_OnOff 0 "Pixel On" 1 "Pixel Off" ;
VAL_ 1364 ICC_RISD_Pixel48_OnOff 0 "Pixel On" 1 "Pixel Off" ;
VAL_ 1364 ICC_RISD_Pixel49_OnOff 0 "Pixel On" 1 "Pixel Off" ;
VAL_ 1364 ICC_RISD_Pixel50_OnOff 0 "Pixel On" 1 "Pixel Off" ;
VAL_ 1364 ICC_RISD_Pixel51_OnOff 0 "Pixel On" 1 "Pixel Off" ;
VAL_ 1364 ICC_RISD_Pixel52_OnOff 0 "Pixel On" 1 "Pixel Off" ;
VAL_ 1364 ICC_RISD_Pixel53_OnOff 0 "Pixel On" 1 "Pixel Off" ;
VAL_ 1364 ICC_RISD_Pixel54_OnOff 0 "Pixel On" 1 "Pixel Off" ;
VAL_ 1364 ICC_RISD_Pixel55_OnOff 0 "Pixel On" 1 "Pixel Off" ;
VAL_ 1364 ICC_RISD_Pixel56_OnOff 0 "Pixel On" 1 "Pixel Off" ;
VAL_ 1364 ICC_RISD_Pixel57_OnOff 0 "Pixel On" 1 "Pixel Off" ;
VAL_ 1364 ICC_RISD_Pixel58_OnOff 0 "Pixel On" 1 "Pixel Off" ;
VAL_ 1364 ICC_RISD_Pixel59_OnOff 0 "Pixel On" 1 "Pixel Off" ;
VAL_ 1364 ICC_RISD_Pixel60_OnOff 0 "Pixel On" 1 "Pixel Off" ;
VAL_ 1364 ICC_RISD_Pixel61_OnOff 0 "Pixel On" 1 "Pixel Off" ;
VAL_ 1364 ICC_RISD_Pixel62_OnOff 0 "Pixel On" 1 "Pixel Off" ;
VAL_ 1364 ICC_RISD_Pixel63_OnOff 0 "Pixel On" 1 "Pixel Off" ;
VAL_ 1364 ICC_RISD_Pixel64_OnOff 0 "Pixel On" 1 "Pixel Off" ;
VAL_ 1364 ICC_RISD_Pixel65_OnOff 0 "Pixel On" 1 "Pixel Off" ;
VAL_ 1364 ICC_RISD_Pixel66_OnOff 0 "Pixel On" 1 "Pixel Off" ;
VAL_ 1364 ICC_RISD_Pixel67_OnOff 0 "Pixel On" 1 "Pixel Off" ;
VAL_ 1364 ICC_RISD_Pixel68_OnOff 0 "Pixel On" 1 "Pixel Off" ;
VAL_ 1364 ICC_RISD_Pixel69_OnOff 0 "Pixel On" 1 "Pixel Off" ;
VAL_ 1364 ICC_RISD_Pixel70_OnOff 0 "Pixel On" 1 "Pixel Off" ;
VAL_ 1364 ICC_RISD_Pixel71_OnOff 0 "Pixel On" 1 "Pixel Off" ;
VAL_ 1364 ICC_RISD_Pixel72_OnOff 0 "Pixel On" 1 "Pixel Off" ;
VAL_ 1364 ICC_RISD_Pixel73_OnOff 0 "Pixel On" 1 "Pixel Off" ;
VAL_ 1364 ICC_RISD_Pixel74_OnOff 0 "Pixel On" 1 "Pixel Off" ;
VAL_ 1364 ICC_RISD_Pixel75_OnOff 0 "Pixel On" 1 "Pixel Off" ;
VAL_ 1364 ICC_RISD_Pixel76_OnOff 0 "Pixel On" 1 "Pixel Off" ;
VAL_ 1364 ICC_RISD_Pixel77_OnOff 0 "Pixel On" 1 "Pixel Off" ;
VAL_ 1364 ICC_RISD_Pixel78_OnOff 0 "Pixel On" 1 "Pixel Off" ;
VAL_ 1364 ICC_RISD_Pixel79_OnOff 0 "Pixel On" 1 "Pixel Off" ;
VAL_ 1364 ICC_RISD_Pixel80_OnOff 0 "Pixel On" 1 "Pixel Off" ;
VAL_ 1364 ICC_RISD_Pixel81_OnOff 0 "Pixel On" 1 "Pixel Off" ;
VAL_ 1364 ICC_RISD_Pixel82_OnOff 0 "Pixel On" 1 "Pixel Off" ;
VAL_ 1364 ICC_RISD_Pixel83_OnOff 0 "Pixel On" 1 "Pixel Off" ;
VAL_ 1364 ICC_RISD_Pixel84_OnOff 0 "Pixel On" 1 "Pixel Off" ;
VAL_ 1364 ICC_RISD_Pixel85_OnOff 0 "Pixel On" 1 "Pixel Off" ;
VAL_ 1364 ICC_RISD_Pixel86_OnOff 0 "Pixel On" 1 "Pixel Off" ;
VAL_ 1364 ICC_RISD_Pixel87_OnOff 0 "Pixel On" 1 "Pixel Off" ;
VAL_ 1364 ICC_RISD_Pixel88_OnOff 0 "Pixel On" 1 "Pixel Off" ;
VAL_ 1364 ICC_RISD_Pixel89_OnOff 0 "Pixel On" 1 "Pixel Off" ;
VAL_ 1364 ICC_RISD_Pixel90_OnOff 0 "Pixel On" 1 "Pixel Off" ;
VAL_ 1364 ICC_RISD_Pixel91_OnOff 0 "Pixel On" 1 "Pixel Off" ;
VAL_ 1364 ICC_RISD_Pixel92_OnOff 0 "Pixel On" 1 "Pixel Off" ;
VAL_ 1364 ICC_RISD_Pixel93_OnOff 0 "Pixel On" 1 "Pixel Off" ;
VAL_ 1364 ICC_RISD_Pixel94_OnOff 0 "Pixel On" 1 "Pixel Off" ;
VAL_ 1364 ICC_RISD_Pixel95_OnOff 0 "Pixel On" 1 "Pixel Off" ;
VAL_ 1364 ICC_RISD_Pixel96_OnOff 0 "Pixel On" 1 "Pixel Off" ;
VAL_ 1364 ICC_RISD_Pixel97_OnOff 0 "Pixel On" 1 "Pixel Off" ;
VAL_ 1364 ICC_RISD_Pixel98_OnOff 0 "Pixel On" 1 "Pixel Off" ;
VAL_ 1364 ICC_RISD_Pixel99_OnOff 0 "Pixel On" 1 "Pixel Off" ;
VAL_ 1364 ICC_RISD_Pixel100_OnOff 0 "Pixel On" 1 "Pixel Off" ;
VAL_ 1364 ICC_RISD_Pixel101_OnOff 0 "Pixel On" 1 "Pixel Off" ;
VAL_ 1364 ICC_RISD_Pixel102_OnOff 0 "Pixel On" 1 "Pixel Off" ;
VAL_ 1364 ICC_RISD_Pixel103_OnOff 0 "Pixel On" 1 "Pixel Off" ;
VAL_ 1364 ICC_RISD_Pixel104_OnOff 0 "Pixel On" 1 "Pixel Off" ;
VAL_ 1364 ICC_RISD_Pixel105_OnOff 0 "Pixel On" 1 "Pixel Off" ;
VAL_ 1364 ICC_RISD_Pixel106_OnOff 0 "Pixel On" 1 "Pixel Off" ;
VAL_ 1364 ICC_RISD_Pixel107_OnOff 0 "Pixel On" 1 "Pixel Off" ;
VAL_ 1364 ICC_RISD_Pixel108_OnOff 0 "Pixel On" 1 "Pixel Off" ;
VAL_ 1364 ICC_RISD_Pixel109_OnOff 0 "Pixel On" 1 "Pixel Off" ;
VAL_ 1364 ICC_RISD_Pixel110_OnOff 0 "Pixel On" 1 "Pixel Off" ;
VAL_ 1364 ICC_RISD_Pixel111_OnOff 0 "Pixel On" 1 "Pixel Off" ;
VAL_ 1364 ICC_RISD_Pixel112_OnOff 0 "Pixel On" 1 "Pixel Off" ;
VAL_ 1364 ICC_RISD_Pixel113_OnOff 0 "Pixel On" 1 "Pixel Off" ;
VAL_ 1364 ICC_RISD_Pixel114_OnOff 0 "Pixel On" 1 "Pixel Off" ;
VAL_ 1364 ICC_RISD_Pixel115_OnOff 0 "Pixel On" 1 "Pixel Off" ;
VAL_ 1364 ICC_RISD_Pixel116_OnOff 0 "Pixel On" 1 "Pixel Off" ;
VAL_ 1364 ICC_RISD_Pixel117_OnOff 0 "Pixel On" 1 "Pixel Off" ;
VAL_ 1364 ICC_RISD_Pixel118_OnOff 0 "Pixel On" 1 "Pixel Off" ;
VAL_ 1364 ICC_RISD_Pixel119_OnOff 0 "Pixel On" 1 "Pixel Off" ;
VAL_ 1364 ICC_RISD_Pixel120_OnOff 0 "Pixel On" 1 "Pixel Off" ;
VAL_ 1364 ICC_RISD_Pixel121_OnOff 0 "Pixel On" 1 "Pixel Off" ;
VAL_ 1364 ICC_RISD_Pixel122_OnOff 0 "Pixel On" 1 "Pixel Off" ;
VAL_ 1364 ICC_RISD_Pixel123_OnOff 0 "Pixel On" 1 "Pixel Off" ;
VAL_ 1364 ICC_RISD_Pixel124_OnOff 0 "Pixel On" 1 "Pixel Off" ;
VAL_ 1364 ICC_RISD_Pixel125_OnOff 0 "Pixel On" 1 "Pixel Off" ;
VAL_ 1364 ICC_RISD_Pixel126_OnOff 0 "Pixel On" 1 "Pixel Off" ;
VAL_ 1364 ICC_RISD_Pixel127_OnOff 0 "Pixel On" 1 "Pixel Off" ;
VAL_ 1364 ICC_RISD_Pixel128_OnOff 0 "Pixel On" 1 "Pixel Off" ;
VAL_ 1364 ICC_RISD_Pixel129_OnOff 0 "Pixel On" 1 "Pixel Off" ;
VAL_ 1364 ICC_RISD_Pixel130_OnOff 0 "Pixel On" 1 "Pixel Off" ;
VAL_ 1364 ICC_RISD_Pixel131_OnOff 0 "Pixel On" 1 "Pixel Off" ;
VAL_ 1364 ICC_RISD_Pixel132_OnOff 0 "Pixel On" 1 "Pixel Off" ;
VAL_ 1364 ICC_RISD_Pixel133_OnOff 0 "Pixel On" 1 "Pixel Off" ;
VAL_ 1364 ICC_RISD_Pixel134_OnOff 0 "Pixel On" 1 "Pixel Off" ;
VAL_ 1364 ICC_RISD_Pixel135_OnOff 0 "Pixel On" 1 "Pixel Off" ;
VAL_ 1364 ICC_RISD_Pixel136_OnOff 0 "Pixel On" 1 "Pixel Off" ;
VAL_ 1364 ICC_RISD_Pixel137_OnOff 0 "Pixel On" 1 "Pixel Off" ;
VAL_ 1364 ICC_RISD_Pixel138_OnOff 0 "Pixel On" 1 "Pixel Off" ;
VAL_ 1364 ICC_RISD_Pixel139_OnOff 0 "Pixel On" 1 "Pixel Off" ;
VAL_ 1364 ICC_RISD_Pixel140_OnOff 0 "Pixel On" 1 "Pixel Off" ;
VAL_ 1364 ICC_RISD_Pixel141_OnOff 0 "Pixel On" 1 "Pixel Off" ;
VAL_ 1364 ICC_RISD_Pixel142_OnOff 0 "Pixel On" 1 "Pixel Off" ;
VAL_ 1364 ICC_RISD_Pixel143_OnOff 0 "Pixel On" 1 "Pixel Off" ;
VAL_ 1364 ICC_RISD_Pixel144_OnOff 0 "Pixel On" 1 "Pixel Off" ;
VAL_ 1364 ICC_RISD_Pixel145_OnOff 0 "Pixel On" 1 "Pixel Off" ;
VAL_ 1364 ICC_RISD_Pixel146_OnOff 0 "Pixel On" 1 "Pixel Off" ;
VAL_ 1364 ICC_RISD_Pixel147_OnOff 0 "Pixel On" 1 "Pixel Off" ;
VAL_ 1364 ICC_RISD_Pixel148_OnOff 0 "Pixel On" 1 "Pixel Off" ;
VAL_ 1364 ICC_RISD_Pixel149_OnOff 0 "Pixel On" 1 "Pixel Off" ;
VAL_ 1364 ICC_RISD_Pixel150_OnOff 0 "Pixel On" 1 "Pixel Off" ;
VAL_ 1364 ICC_RISD_Pixel151_OnOff 0 "Pixel On" 1 "Pixel Off" ;
VAL_ 1364 ICC_RISD_Pixel152_OnOff 0 "Pixel On" 1 "Pixel Off" ;
VAL_ 1364 ICC_RISD_Pixel153_OnOff 0 "Pixel On" 1 "Pixel Off" ;
VAL_ 1364 ICC_RISD_Pixel154_OnOff 0 "Pixel On" 1 "Pixel Off" ;
VAL_ 1364 ICC_RISD_Pixel155_OnOff 0 "Pixel On" 1 "Pixel Off" ;
VAL_ 1364 ICC_RISD_Pixel156_OnOff 0 "Pixel On" 1 "Pixel Off" ;
VAL_ 1364 ICC_RISD_Pixel157_OnOff 0 "Pixel On" 1 "Pixel Off" ;
VAL_ 1364 ICC_RISD_Pixel158_OnOff 0 "Pixel On" 1 "Pixel Off" ;
VAL_ 1364 ICC_RISD_Pixel159_OnOff 0 "Pixel On" 1 "Pixel Off" ;
VAL_ 1364 ICC_RISD_Pixel160_OnOff 0 "Pixel On" 1 "Pixel Off" ;
VAL_ 1364 ICC_RISD_Pixel161_OnOff 0 "Pixel On" 1 "Pixel Off" ;
VAL_ 1364 ICC_RISD_Pixel162_OnOff 0 "Pixel On" 1 "Pixel Off" ;
VAL_ 1364 ICC_RISD_Pixel163_OnOff 0 "Pixel On" 1 "Pixel Off" ;
VAL_ 1364 ICC_RISD_Pixel164_OnOff 0 "Pixel On" 1 "Pixel Off" ;
VAL_ 1364 ICC_RISD_Pixel165_OnOff 0 "Pixel On" 1 "Pixel Off" ;
VAL_ 1364 ICC_RISD_Pixel166_OnOff 0 "Pixel On" 1 "Pixel Off" ;
VAL_ 1364 ICC_RISD_Pixel167_OnOff 0 "Pixel On" 1 "Pixel Off" ;
VAL_ 1364 ICC_RISD_Pixel168_OnOff 0 "Pixel On" 1 "Pixel Off" ;
VAL_ 1364 ICC_RISD_Pixel169_OnOff 0 "Pixel On" 1 "Pixel Off" ;
VAL_ 1364 ICC_RISD_Pixel170_OnOff 0 "Pixel On" 1 "Pixel Off" ;
VAL_ 1364 ICC_RISD_Pixel171_OnOff 0 "Pixel On" 1 "Pixel Off" ;
VAL_ 1364 ICC_RISD_Pixel172_OnOff 0 "Pixel On" 1 "Pixel Off" ;
VAL_ 1364 ICC_RISD_Pixel173_OnOff 0 "Pixel On" 1 "Pixel Off" ;
VAL_ 1364 ICC_RISD_Pixel174_OnOff 0 "Pixel On" 1 "Pixel Off" ;
VAL_ 1364 ICC_RISD_Pixel175_OnOff 0 "Pixel On" 1 "Pixel Off" ;
VAL_ 1364 ICC_RISD_Pixel176_OnOff 0 "Pixel On" 1 "Pixel Off" ;
VAL_ 1364 ICC_RISD_Pixel177_OnOff 0 "Pixel On" 1 "Pixel Off" ;
VAL_ 1364 ICC_RISD_Pixel178_OnOff 0 "Pixel On" 1 "Pixel Off" ;
VAL_ 1364 ICC_RISD_Pixel179_OnOff 0 "Pixel On" 1 "Pixel Off" ;
VAL_ 1364 ICC_RISD_Pixel180_OnOff 0 "Pixel On" 1 "Pixel Off" ;
VAL_ 1364 ICC_RISD_Pixel181_OnOff 0 "Pixel On" 1 "Pixel Off" ;
VAL_ 1364 ICC_RISD_Pixel182_OnOff 0 "Pixel On" 1 "Pixel Off" ;
VAL_ 1364 ICC_RISD_Pixel183_OnOff 0 "Pixel On" 1 "Pixel Off" ;
VAL_ 1364 ICC_RISD_Pixel184_OnOff 0 "Pixel On" 1 "Pixel Off" ;
VAL_ 1364 ICC_RISD_Pixel185_OnOff 0 "Pixel On" 1 "Pixel Off" ;
VAL_ 1364 ICC_RISD_Pixel186_OnOff 0 "Pixel On" 1 "Pixel Off" ;
VAL_ 1364 ICC_RISD_Pixel187_OnOff 0 "Pixel On" 1 "Pixel Off" ;
VAL_ 1364 ICC_RISD_Pixel188_OnOff 0 "Pixel On" 1 "Pixel Off" ;
VAL_ 1364 ICC_RISD_Pixel189_OnOff 0 "Pixel On" 1 "Pixel Off" ;
VAL_ 1364 ICC_RISD_Pixel190_OnOff 0 "Pixel On" 1 "Pixel Off" ;
VAL_ 1364 ICC_RISD_Pixel191_OnOff 0 "Pixel On" 1 "Pixel Off" ;
VAL_ 1364 ICC_RISD_Pixel192_OnOff 0 "Pixel On" 1 "Pixel Off" ;
VAL_ 1364 ICC_RISD_Pixel193_OnOff 0 "Pixel On" 1 "Pixel Off" ;
VAL_ 1364 ICC_RISD_Pixel194_OnOff 0 "Pixel On" 1 "Pixel Off" ;
VAL_ 1364 ICC_RISD_Pixel195_OnOff 0 "Pixel On" 1 "Pixel Off" ;
VAL_ 1364 ICC_RISD_Pixel196_OnOff 0 "Pixel On" 1 "Pixel Off" ;
VAL_ 1364 ICC_RISD_Pixel197_OnOff 0 "Pixel On" 1 "Pixel Off" ;
VAL_ 1364 ICC_RISD_Pixel198_OnOff 0 "Pixel On" 1 "Pixel Off" ;
VAL_ 1364 ICC_RISD_Pixel199_OnOff 0 "Pixel On" 1 "Pixel Off" ;
VAL_ 1364 ICC_RISD_Pixel200_OnOff 0 "Pixel On" 1 "Pixel Off" ;
VAL_ 1364 ICC_RISD_Pixel201_OnOff 0 "Pixel On" 1 "Pixel Off" ;
VAL_ 1364 ICC_RISD_Pixel202_OnOff 0 "Pixel On" 1 "Pixel Off" ;
VAL_ 1364 ICC_RISD_Pixel203_OnOff 0 "Pixel On" 1 "Pixel Off" ;
VAL_ 1364 ICC_RISD_Pixel204_OnOff 0 "Pixel On" 1 "Pixel Off" ;
VAL_ 1364 ICC_RISD_Pixel205_OnOff 0 "Pixel On" 1 "Pixel Off" ;
VAL_ 1364 ICC_RISD_Pixel206_OnOff 0 "Pixel On" 1 "Pixel Off" ;
VAL_ 1364 ICC_RISD_Pixel207_OnOff 0 "Pixel On" 1 "Pixel Off" ;
VAL_ 1364 ICC_RISD_Pixel208_OnOff 0 "Pixel On" 1 "Pixel Off" ;
VAL_ 1364 ICC_RISD_Pixel209_OnOff 0 "Pixel On" 1 "Pixel Off" ;
VAL_ 1364 ICC_RISD_Pixel210_OnOff 0 "Pixel On" 1 "Pixel Off" ;
VAL_ 1364 ICC_RISD_Pixel211_OnOff 0 "Pixel On" 1 "Pixel Off" ;
VAL_ 1364 ICC_RISD_Pixel212_OnOff 0 "Pixel On" 1 "Pixel Off" ;
VAL_ 1364 ICC_RISD_Pixel213_OnOff 0 "Pixel On" 1 "Pixel Off" ;
VAL_ 1364 ICC_RISD_Pixel214_OnOff 0 "Pixel On" 1 "Pixel Off" ;
VAL_ 1364 ICC_RISD_Pixel215_OnOff 0 "Pixel On" 1 "Pixel Off" ;
VAL_ 1364 ICC_RISD_Pixel216_OnOff 0 "Pixel On" 1 "Pixel Off" ;
VAL_ 1364 ICC_RISD_Pixel217_OnOff 0 "Pixel On" 1 "Pixel Off" ;
VAL_ 1364 ICC_RISD_Pixel218_OnOff 0 "Pixel On" 1 "Pixel Off" ;
VAL_ 1364 ICC_RISD_Pixel219_OnOff 0 "Pixel On" 1 "Pixel Off" ;
VAL_ 1364 ICC_RISD_Pixel220_OnOff 0 "Pixel On" 1 "Pixel Off" ;
VAL_ 1364 ICC_RISD_Pixel221_OnOff 0 "Pixel On" 1 "Pixel Off" ;
VAL_ 1364 ICC_RISD_Pixel222_OnOff 0 "Pixel On" 1 "Pixel Off" ;
VAL_ 1364 ICC_RISD_Pixel223_OnOff 0 "Pixel On" 1 "Pixel Off" ;
VAL_ 1364 ICC_RISD_Pixel224_OnOff 0 "Pixel On" 1 "Pixel Off" ;
VAL_ 1364 ICC_RISD_Pixel225_OnOff 0 "Pixel On" 1 "Pixel Off" ;
VAL_ 1364 ICC_RISD_Pixel226_OnOff 0 "Pixel On" 1 "Pixel Off" ;
VAL_ 1364 ICC_RISD_Pixel227_OnOff 0 "Pixel On" 1 "Pixel Off" ;
VAL_ 1364 ICC_RISD_Pixel228_OnOff 0 "Pixel On" 1 "Pixel Off" ;
VAL_ 1364 ICC_RISD_Pixel229_OnOff 0 "Pixel On" 1 "Pixel Off" ;
VAL_ 1364 ICC_RISD_Pixel230_OnOff 0 "Pixel On" 1 "Pixel Off" ;
VAL_ 1364 ICC_RISD_Pixel231_OnOff 0 "Pixel On" 1 "Pixel Off" ;
VAL_ 1364 ICC_RISD_Pixel232_OnOff 0 "Pixel On" 1 "Pixel Off" ;
VAL_ 1364 ICC_RISD_Pixel233_OnOff 0 "Pixel On" 1 "Pixel Off" ;
VAL_ 1364 ICC_RISD_Pixel234_OnOff 0 "Pixel On" 1 "Pixel Off" ;
VAL_ 1364 ICC_RISD_Pixel235_OnOff 0 "Pixel On" 1 "Pixel Off" ;
VAL_ 1364 ICC_RISD_Pixel236_OnOff 0 "Pixel On" 1 "Pixel Off" ;
VAL_ 1364 ICC_RISD_Pixel237_OnOff 0 "Pixel On" 1 "Pixel Off" ;
VAL_ 1364 ICC_RISD_Pixel238_OnOff 0 "Pixel On" 1 "Pixel Off" ;
VAL_ 1364 ICC_RISD_Pixel239_OnOff 0 "Pixel On" 1 "Pixel Off" ;
VAL_ 1364 ICC_RISD_Pixel240_OnOff 0 "Pixel On" 1 "Pixel Off" ;
VAL_ 1364 ICC_RISD_Pixel241_OnOff 0 "Pixel On" 1 "Pixel Off" ;
VAL_ 1364 ICC_RISD_Pixel242_OnOff 0 "Pixel On" 1 "Pixel Off" ;
VAL_ 1364 ICC_RISD_Pixel243_OnOff 0 "Pixel On" 1 "Pixel Off" ;
VAL_ 1364 ICC_RISD_Pixel244_OnOff 0 "Pixel On" 1 "Pixel Off" ;
VAL_ 1364 ICC_RISD_Pixel245_OnOff 0 "Pixel On" 1 "Pixel Off" ;
VAL_ 1364 ICC_RISD_Pixel246_OnOff 0 "Pixel On" 1 "Pixel Off" ;
VAL_ 1364 ICC_RISD_Pixel247_OnOff 0 "Pixel On" 1 "Pixel Off" ;
VAL_ 1364 ICC_RISD_Pixel248_OnOff 0 "Pixel On" 1 "Pixel Off" ;
VAL_ 1364 ICC_RISD_Pixel249_OnOff 0 "Pixel On" 1 "Pixel Off" ;
VAL_ 1364 ICC_RISD_Pixel250_OnOff 0 "Pixel On" 1 "Pixel Off" ;
VAL_ 1364 ICC_RISD_Pixel251_OnOff 0 "Pixel On" 1 "Pixel Off" ;
VAL_ 1364 ICC_RISD_Pixel252_OnOff 0 "Pixel On" 1 "Pixel Off" ;
VAL_ 1364 ICC_RISD_Pixel253_OnOff 0 "Pixel On" 1 "Pixel Off" ;
VAL_ 1364 ICC_RISD_Pixel254_OnOff 0 "Pixel On" 1 "Pixel Off" ;
VAL_ 1364 ICC_RISD_Pixel255_OnOff 0 "Pixel On" 1 "Pixel Off" ;
VAL_ 1364 ICC_RISD_Pixel256_OnOff 0 "Pixel On" 1 "Pixel Off" ;
VAL_ 1364 ICC_RISD_Pixel257_OnOff 0 "Pixel On" 1 "Pixel Off" ;
VAL_ 1364 ICC_RISD_Pixel258_OnOff 0 "Pixel On" 1 "Pixel Off" ;
VAL_ 1364 ICC_RISD_Pixel259_OnOff 0 "Pixel On" 1 "Pixel Off" ;
VAL_ 1364 ICC_RISD_Pixel260_OnOff 0 "Pixel On" 1 "Pixel Off" ;
VAL_ 1364 ICC_RISD_Pixel261_OnOff 0 "Pixel On" 1 "Pixel Off" ;
VAL_ 1364 ICC_RISD_Pixel262_OnOff 0 "Pixel On" 1 "Pixel Off" ;
VAL_ 1364 ICC_RISD_Pixel263_OnOff 0 "Pixel On" 1 "Pixel Off" ;
VAL_ 1364 ICC_RISD_Pixel264_OnOff 0 "Pixel On" 1 "Pixel Off" ;
VAL_ 1364 ICC_RISD_Pixel265_OnOff 0 "Pixel On" 1 "Pixel Off" ;
VAL_ 1364 ICC_RISD_Pixel266_OnOff 0 "Pixel On" 1 "Pixel Off" ;
VAL_ 1364 ICC_RISD_Pixel267_OnOff 0 "Pixel On" 1 "Pixel Off" ;
VAL_ 1364 ICC_RISD_Pixel268_OnOff 0 "Pixel On" 1 "Pixel Off" ;
VAL_ 1364 ICC_RISD_Pixel269_OnOff 0 "Pixel On" 1 "Pixel Off" ;
VAL_ 1364 ICC_RISD_Pixel270_OnOff 0 "Pixel On" 1 "Pixel Off" ;
VAL_ 1364 ICC_RISD_Pixel271_OnOff 0 "Pixel On" 1 "Pixel Off" ;
VAL_ 1364 ICC_RISD_Pixel272_OnOff 0 "Pixel On" 1 "Pixel Off" ;
VAL_ 1364 ICC_RISD_Pixel273_OnOff 0 "Pixel On" 1 "Pixel Off" ;
VAL_ 1364 ICC_RISD_Pixel274_OnOff 0 "Pixel On" 1 "Pixel Off" ;
VAL_ 1364 ICC_RISD_Pixel275_OnOff 0 "Pixel On" 1 "Pixel Off" ;
VAL_ 1364 ICC_RISD_Pixel276_OnOff 0 "Pixel On" 1 "Pixel Off" ;
VAL_ 1364 ICC_RISD_Pixel277_OnOff 0 "Pixel On" 1 "Pixel Off" ;
VAL_ 1364 ICC_RISD_Pixel278_OnOff 0 "Pixel On" 1 "Pixel Off" ;
VAL_ 1364 ICC_RISD_Pixel279_OnOff 0 "Pixel On" 1 "Pixel Off" ;
VAL_ 1364 ICC_RISD_Pixel280_OnOff 0 "Pixel On" 1 "Pixel Off" ;
VAL_ 1364 ICC_RISD_Pixel281_OnOff 0 "Pixel On" 1 "Pixel Off" ;
VAL_ 1364 ICC_RISD_Pixel282_OnOff 0 "Pixel On" 1 "Pixel Off" ;
VAL_ 1364 ICC_RISD_Pixel283_OnOff 0 "Pixel On" 1 "Pixel Off" ;
VAL_ 1364 ICC_RISD_Pixel284_OnOff 0 "Pixel On" 1 "Pixel Off" ;
VAL_ 1364 ICC_RISD_Pixel285_OnOff 0 "Pixel On" 1 "Pixel Off" ;
VAL_ 1364 ICC_RISD_Pixel286_OnOff 0 "Pixel On" 1 "Pixel Off" ;
VAL_ 1364 ICC_RISD_Pixel287_OnOff 0 "Pixel On" 1 "Pixel Off" ;
VAL_ 1364 ICC_RISD_Pixel288_OnOff 0 "Pixel On" 1 "Pixel Off" ;
VAL_ 1364 ICC_RISD_Pixel289_OnOff 0 "Pixel On" 1 "Pixel Off" ;
VAL_ 1364 ICC_RISD_Pixel290_OnOff 0 "Pixel On" 1 "Pixel Off" ;
VAL_ 1364 ICC_RISD_Pixel291_OnOff 0 "Pixel On" 1 "Pixel Off" ;
VAL_ 1364 ICC_RISD_Pixel292_OnOff 0 "Pixel On" 1 "Pixel Off" ;
VAL_ 1364 ICC_RISD_Pixel293_OnOff 0 "Pixel On" 1 "Pixel Off" ;
VAL_ 1364 ICC_RISD_Pixel294_OnOff 0 "Pixel On" 1 "Pixel Off" ;
VAL_ 1364 ICC_RISD_Pixel295_OnOff 0 "Pixel On" 1 "Pixel Off" ;
VAL_ 1364 ICC_RISD_Pixel296_OnOff 0 "Pixel On" 1 "Pixel Off" ;
VAL_ 1364 ICC_RISD_Pixel297_OnOff 0 "Pixel On" 1 "Pixel Off" ;
VAL_ 1364 ICC_RISD_Pixel298_OnOff 0 "Pixel On" 1 "Pixel Off" ;
VAL_ 1364 ICC_RISD_Pixel299_OnOff 0 "Pixel On" 1 "Pixel Off" ;
VAL_ 1364 ICC_RISD_Pixel300_OnOff 0 "Pixel On" 1 "Pixel Off" ;
VAL_ 1364 ICC_RISD_Pixel301_OnOff 0 "Pixel On" 1 "Pixel Off" ;
VAL_ 1364 ICC_RISD_Pixel302_OnOff 0 "Pixel On" 1 "Pixel Off" ;
VAL_ 1364 ICC_RISD_Pixel303_OnOff 0 "Pixel On" 1 "Pixel Off" ;
VAL_ 1364 ICC_RISD_Pixel304_OnOff 0 "Pixel On" 1 "Pixel Off" ;
VAL_ 1364 ICC_RISD_Pixel305_OnOff 0 "Pixel On" 1 "Pixel Off" ;
VAL_ 1364 ICC_RISD_Pixel306_OnOff 0 "Pixel On" 1 "Pixel Off" ;
VAL_ 1364 ICC_RISD_Pixel307_OnOff 0 "Pixel On" 1 "Pixel Off" ;
VAL_ 1364 ICC_RISD_Pixel308_OnOff 0 "Pixel On" 1 "Pixel Off" ;
VAL_ 1364 ICC_RISD_Pixel309_OnOff 0 "Pixel On" 1 "Pixel Off" ;
VAL_ 1364 ICC_RISD_Pixel310_OnOff 0 "Pixel On" 1 "Pixel Off" ;
VAL_ 1364 ICC_RISD_Pixel311_OnOff 0 "Pixel On" 1 "Pixel Off" ;
VAL_ 1364 ICC_RISD_Pixel312_OnOff 0 "Pixel On" 1 "Pixel Off" ;
VAL_ 1364 ICC_RISD_Pixel313_OnOff 0 "Pixel On" 1 "Pixel Off" ;
VAL_ 1364 ICC_RISD_Pixel314_OnOff 0 "Pixel On" 1 "Pixel Off" ;
VAL_ 1364 ICC_RISD_Pixel315_OnOff 0 "Pixel On" 1 "Pixel Off" ;
VAL_ 1364 ICC_RISD_Pixel316_OnOff 0 "Pixel On" 1 "Pixel Off" ;
VAL_ 1364 ICC_RISD_Pixel317_OnOff 0 "Pixel On" 1 "Pixel Off" ;
VAL_ 1364 ICC_RISD_Pixel318_OnOff 0 "Pixel On" 1 "Pixel Off" ;
VAL_ 1364 ICC_RISD_Pixel319_OnOff 0 "Pixel On" 1 "Pixel Off" ;
VAL_ 1364 ICC_RISD_Pixel320_OnOff 0 "Pixel On" 1 "Pixel Off" ;
VAL_ 1364 ICC_RISD_Pixel321_OnOff 0 "Pixel On" 1 "Pixel Off" ;
VAL_ 1364 ICC_RISD_Pixel322_OnOff 0 "Pixel On" 1 "Pixel Off" ;
VAL_ 1364 ICC_RISD_Pixel323_OnOff 0 "Pixel On" 1 "Pixel Off" ;
VAL_ 1364 ICC_RISD_Pixel324_OnOff 0 "Pixel On" 1 "Pixel Off" ;
VAL_ 1364 ICC_RISD_Pixel325_OnOff 0 "Pixel On" 1 "Pixel Off" ;
VAL_ 1364 ICC_RISD_Pixel326_OnOff 0 "Pixel On" 1 "Pixel Off" ;
VAL_ 1364 ICC_RISD_Pixel327_OnOff 0 "Pixel On" 1 "Pixel Off" ;
VAL_ 1364 ICC_RISD_Pixel328_OnOff 0 "Pixel On" 1 "Pixel Off" ;
VAL_ 1364 ICC_RISD_Pixel329_OnOff 0 "Pixel On" 1 "Pixel Off" ;
VAL_ 1364 ICC_RISD_Pixel330_OnOff 0 "Pixel On" 1 "Pixel Off" ;
VAL_ 1364 ICC_RISD_Pixel331_OnOff 0 "Pixel On" 1 "Pixel Off" ;
VAL_ 1364 ICC_RISD_Pixel332_OnOff 0 "Pixel On" 1 "Pixel Off" ;
VAL_ 1364 ICC_RISD_Pixel333_OnOff 0 "Pixel On" 1 "Pixel Off" ;
VAL_ 1364 ICC_RISD_Pixel334_OnOff 0 "Pixel On" 1 "Pixel Off" ;
VAL_ 1364 ICC_RISD_Pixel335_OnOff 0 "Pixel On" 1 "Pixel Off" ;
VAL_ 1364 ICC_RISD_Pixel336_OnOff 0 "Pixel On" 1 "Pixel Off" ;
VAL_ 1364 ICC_RISD_Pixel337_OnOff 0 "Pixel On" 1 "Pixel Off" ;
VAL_ 1364 ICC_RISD_Pixel338_OnOff 0 "Pixel On" 1 "Pixel Off" ;
VAL_ 1364 ICC_RISD_Pixel339_OnOff 0 "Pixel On" 1 "Pixel Off" ;
VAL_ 1364 ICC_RISD_Pixel340_OnOff 0 "Pixel On" 1 "Pixel Off" ;
VAL_ 1364 ICC_RISD_Pixel341_OnOff 0 "Pixel On" 1 "Pixel Off" ;
VAL_ 1364 ICC_RISD_Pixel342_OnOff 0 "Pixel On" 1 "Pixel Off" ;
VAL_ 1364 ICC_RISD_Pixel343_OnOff 0 "Pixel On" 1 "Pixel Off" ;
VAL_ 1364 ICC_RISD_Pixel344_OnOff 0 "Pixel On" 1 "Pixel Off" ;
VAL_ 1364 ICC_RISD_Pixel345_OnOff 0 "Pixel On" 1 "Pixel Off" ;
VAL_ 1364 ICC_RISD_Pixel346_OnOff 0 "Pixel On" 1 "Pixel Off" ;
VAL_ 1364 ICC_RISD_Pixel347_OnOff 0 "Pixel On" 1 "Pixel Off" ;
VAL_ 1364 ICC_RISD_Pixel348_OnOff 0 "Pixel On" 1 "Pixel Off" ;
VAL_ 1364 ICC_RISD_Pixel349_OnOff 0 "Pixel On" 1 "Pixel Off" ;
VAL_ 1364 ICC_RISD_Pixel350_OnOff 0 "Pixel On" 1 "Pixel Off" ;
VAL_ 1364 ICC_RISD_Pixel351_OnOff 0 "Pixel On" 1 "Pixel Off" ;
VAL_ 1364 ICC_RISD_Pixel352_OnOff 0 "Pixel On" 1 "Pixel Off" ;
VAL_ 1364 ICC_RISD_Pixel353_OnOff 0 "Pixel On" 1 "Pixel Off" ;
VAL_ 1364 ICC_RISD_Pixel354_OnOff 0 "Pixel On" 1 "Pixel Off" ;
VAL_ 1364 ICC_RISD_Pixel355_OnOff 0 "Pixel On" 1 "Pixel Off" ;
VAL_ 1364 ICC_RISD_Pixel356_OnOff 0 "Pixel On" 1 "Pixel Off" ;
VAL_ 1364 ICC_RISD_Pixel357_OnOff 0 "Pixel On" 1 "Pixel Off" ;
VAL_ 1364 ICC_RISD_Pixel358_OnOff 0 "Pixel On" 1 "Pixel Off" ;
VAL_ 1364 ICC_RISD_Pixel359_OnOff 0 "Pixel On" 1 "Pixel Off" ;
VAL_ 1364 ICC_RISD_Pixel360_OnOff 0 "Pixel On" 1 "Pixel Off" ;
VAL_ 1364 ICC_RISD_Pixel361_OnOff 0 "Pixel On" 1 "Pixel Off" ;
VAL_ 1364 ICC_RISD_Pixel362_OnOff 0 "Pixel On" 1 "Pixel Off" ;
VAL_ 1364 ICC_RISD_Pixel363_OnOff 0 "Pixel On" 1 "Pixel Off" ;
VAL_ 1364 ICC_RISD_Pixel364_OnOff 0 "Pixel On" 1 "Pixel Off" ;
VAL_ 1364 ICC_RISD_Pixel365_OnOff 0 "Pixel On" 1 "Pixel Off" ;
VAL_ 1364 ICC_RISD_Pixel366_OnOff 0 "Pixel On" 1 "Pixel Off" ;
VAL_ 1364 ICC_RISD_Pixel367_OnOff 0 "Pixel On" 1 "Pixel Off" ;
VAL_ 1364 ICC_RISD_Pixel368_OnOff 0 "Pixel On" 1 "Pixel Off" ;
VAL_ 1364 ICC_RISD_Pixel369_OnOff 0 "Pixel On" 1 "Pixel Off" ;
VAL_ 1364 ICC_RISD_Pixel370_OnOff 0 "Pixel On" 1 "Pixel Off" ;
VAL_ 1364 ICC_RISD_Pixel371_OnOff 0 "Pixel On" 1 "Pixel Off" ;
VAL_ 1364 ICC_RISD_Pixel372_OnOff 0 "Pixel On" 1 "Pixel Off" ;
VAL_ 1364 ICC_RISD_Pixel373_OnOff 0 "Pixel On" 1 "Pixel Off" ;
VAL_ 1364 ICC_RISD_Pixel374_OnOff 0 "Pixel On" 1 "Pixel Off" ;
VAL_ 1364 ICC_RISD_Pixel375_OnOff 0 "Pixel On" 1 "Pixel Off" ;
VAL_ 1364 ICC_RISD_Pixel376_OnOff 0 "Pixel On" 1 "Pixel Off" ;
VAL_ 1364 ICC_RISD_Pixel377_OnOff 0 "Pixel On" 1 "Pixel Off" ;
VAL_ 1364 ICC_RISD_Pixel378_OnOff 0 "Pixel On" 1 "Pixel Off" ;
VAL_ 1364 ICC_RISD_Pixel379_OnOff 0 "Pixel On" 1 "Pixel Off" ;
VAL_ 1364 ICC_RISD_Pixel380_OnOff 0 "Pixel On" 1 "Pixel Off" ;
VAL_ 1364 ICC_RISD_Pixel381_OnOff 0 "Pixel On" 1 "Pixel Off" ;
VAL_ 1364 ICC_RISD_Pixel382_OnOff 0 "Pixel On" 1 "Pixel Off" ;
VAL_ 1364 ICC_RISD_Pixel383_OnOff 0 "Pixel On" 1 "Pixel Off" ;
VAL_ 1364 ICC_RISD_Pixel384_OnOff 0 "Pixel On" 1 "Pixel Off" ;
VAL_ 1364 ICC_RISD_Pixel385_OnOff 0 "Pixel On" 1 "Pixel Off" ;
VAL_ 1364 ICC_RISD_Pixel386_OnOff 0 "Pixel On" 1 "Pixel Off" ;
VAL_ 1364 ICC_RISD_Pixel387_OnOff 0 "Pixel On" 1 "Pixel Off" ;
VAL_ 1364 ICC_RISD_Pixel388_OnOff 0 "Pixel On" 1 "Pixel Off" ;
VAL_ 1364 ICC_RISD_Pixel389_OnOff 0 "Pixel On" 1 "Pixel Off" ;
VAL_ 1364 ICC_RISD_Pixel390_OnOff 0 "Pixel On" 1 "Pixel Off" ;
VAL_ 1364 ICC_RISD_Pixel391_OnOff 0 "Pixel On" 1 "Pixel Off" ;
VAL_ 1364 ICC_RISD_Pixel392_OnOff 0 "Pixel On" 1 "Pixel Off" ;
VAL_ 1364 ICC_RISD_Pixel393_OnOff 0 "Pixel On" 1 "Pixel Off" ;
VAL_ 1364 ICC_RISD_Pixel394_OnOff 0 "Pixel On" 1 "Pixel Off" ;
VAL_ 1364 ICC_RISD_Pixel395_OnOff 0 "Pixel On" 1 "Pixel Off" ;
VAL_ 1364 ICC_RISD_Pixel396_OnOff 0 "Pixel On" 1 "Pixel Off" ;
VAL_ 1364 ICC_RISD_Pixel397_OnOff 0 "Pixel On" 1 "Pixel Off" ;
VAL_ 1364 ICC_RISD_Pixel398_OnOff 0 "Pixel On" 1 "Pixel Off" ;
VAL_ 1364 ICC_RISD_Pixel399_OnOff 0 "Pixel On" 1 "Pixel Off" ;
VAL_ 1364 ICC_RISD_Pixel400_OnOff 0 "Pixel On" 1 "Pixel Off" ;
VAL_ 1364 ICC_RISD_Pixel401_OnOff 0 "Pixel On" 1 "Pixel Off" ;
VAL_ 1364 ICC_RISD_Pixel402_OnOff 0 "Pixel On" 1 "Pixel Off" ;
VAL_ 1364 ICC_RISD_Pixel403_OnOff 0 "Pixel On" 1 "Pixel Off" ;
VAL_ 1364 ICC_RISD_Pixel404_OnOff 0 "Pixel On" 1 "Pixel Off" ;
VAL_ 1364 ICC_RISD_Pixel405_OnOff 0 "Pixel On" 1 "Pixel Off" ;
VAL_ 1364 ICC_RISD_Pixel406_OnOff 0 "Pixel On" 1 "Pixel Off" ;
VAL_ 1364 ICC_RISD_Pixel407_OnOff 0 "Pixel On" 1 "Pixel Off" ;
VAL_ 1364 ICC_RISD_Pixel408_OnOff 0 "Pixel On" 1 "Pixel Off" ;
VAL_ 1364 ICC_RISD_Pixel409_OnOff 0 "Pixel On" 1 "Pixel Off" ;
VAL_ 1364 ICC_RISD_Pixel410_OnOff 0 "Pixel On" 1 "Pixel Off" ;
VAL_ 1364 ICC_RISD_Pixel411_OnOff 0 "Pixel On" 1 "Pixel Off" ;
VAL_ 1364 ICC_RISD_Pixel412_OnOff 0 "Pixel On" 1 "Pixel Off" ;
VAL_ 1364 ICC_RISD_Pixel413_OnOff 0 "Pixel On" 1 "Pixel Off" ;
VAL_ 1364 ICC_RISD_Pixel414_OnOff 0 "Pixel On" 1 "Pixel Off" ;
VAL_ 1364 ICC_RISD_Pixel415_OnOff 0 "Pixel On" 1 "Pixel Off" ;
VAL_ 1364 ICC_RISD_Pixel416_OnOff 0 "Pixel On" 1 "Pixel Off" ;
VAL_ 1364 ICC_RISD_Pixel417_OnOff 0 "Pixel On" 1 "Pixel Off" ;
VAL_ 1364 ICC_RISD_Pixel418_OnOff 0 "Pixel On" 1 "Pixel Off" ;
VAL_ 1364 ICC_RISD_Pixel419_OnOff 0 "Pixel On" 1 "Pixel Off" ;
VAL_ 1364 ICC_RISD_Pixel420_OnOff 0 "Pixel On" 1 "Pixel Off" ;
VAL_ 1364 ICC_RISD_Pixel421_OnOff 0 "Pixel On" 1 "Pixel Off" ;
VAL_ 1364 ICC_RISD_Pixel422_OnOff 0 "Pixel On" 1 "Pixel Off" ;
VAL_ 1364 ICC_RISD_Pixel423_OnOff 0 "Pixel On" 1 "Pixel Off" ;
VAL_ 1364 ICC_RISD_Pixel424_OnOff 0 "Pixel On" 1 "Pixel Off" ;
VAL_ 1364 ICC_RISD_Pixel425_OnOff 0 "Pixel On" 1 "Pixel Off" ;
VAL_ 1364 ICC_RISD_Pixel426_OnOff 0 "Pixel On" 1 "Pixel Off" ;
VAL_ 1364 ICC_RISD_Pixel427_OnOff 0 "Pixel On" 1 "Pixel Off" ;
VAL_ 1364 ICC_RISD_Pixel428_OnOff 0 "Pixel On" 1 "Pixel Off" ;
VAL_ 1364 ICC_RISD_Pixel429_OnOff 0 "Pixel On" 1 "Pixel Off" ;
VAL_ 1364 ICC_RISD_Pixel430_OnOff 0 "Pixel On" 1 "Pixel Off" ;
VAL_ 1364 ICC_RISD_Pixel431_OnOff 0 "Pixel On" 1 "Pixel Off" ;
VAL_ 1364 ICC_RISD_Pixel432_OnOff 0 "Pixel On" 1 "Pixel Off" ;
VAL_ 1364 ICC_RISD_Pixel433_OnOff 0 "Pixel On" 1 "Pixel Off" ;
VAL_ 1364 ICC_RISD_Pixel434_OnOff 0 "Pixel On" 1 "Pixel Off" ;
VAL_ 1364 ICC_RISD_Pixel435_OnOff 0 "Pixel On" 1 "Pixel Off" ;
VAL_ 1364 ICC_RISD_Pixel436_OnOff 0 "Pixel On" 1 "Pixel Off" ;
VAL_ 1364 ICC_RISD_Pixel437_OnOff 0 "Pixel On" 1 "Pixel Off" ;
VAL_ 1364 ICC_RISD_Pixel438_OnOff 0 "Pixel On" 1 "Pixel Off" ;
VAL_ 1364 ICC_RISD_Pixel439_OnOff 0 "Pixel On" 1 "Pixel Off" ;
VAL_ 1364 ICC_RISD_Pixel440_OnOff 0 "Pixel On" 1 "Pixel Off" ;
VAL_ 1364 ICC_RISD_Pixel441_OnOff 0 "Pixel On" 1 "Pixel Off" ;
VAL_ 1364 ICC_RISD_Pixel442_OnOff 0 "Pixel On" 1 "Pixel Off" ;
VAL_ 1364 ICC_RISD_Pixel443_OnOff 0 "Pixel On" 1 "Pixel Off" ;
VAL_ 1364 ICC_RISD_Pixel444_OnOff 0 "Pixel On" 1 "Pixel Off" ;
VAL_ 1364 ICC_RISD_Pixel445_OnOff 0 "Pixel On" 1 "Pixel Off" ;
VAL_ 1364 ICC_RISD_Pixel446_OnOff 0 "Pixel On" 1 "Pixel Off" ;
VAL_ 1364 ICC_RISD_Pixel447_OnOff 0 "Pixel On" 1 "Pixel Off" ;
VAL_ 1364 ICC_RISD_Pixel448_OnOff 0 "Pixel On" 1 "Pixel Off" ;
VAL_ 1364 ICC_RISD_Pixel449_OnOff 0 "Pixel On" 1 "Pixel Off" ;
VAL_ 1364 ICC_RISD_Pixel450_OnOff 0 "Pixel On" 1 "Pixel Off" ;
VAL_ 1364 ICC_RISD_Pixel451_OnOff 0 "Pixel On" 1 "Pixel Off" ;
VAL_ 1364 ICC_RISD_Pixel452_OnOff 0 "Pixel On" 1 "Pixel Off" ;
VAL_ 1364 ICC_RISD_Pixel453_OnOff 0 "Pixel On" 1 "Pixel Off" ;
VAL_ 1364 ICC_RISD_Pixel454_OnOff 0 "Pixel On" 1 "Pixel Off" ;
VAL_ 1364 ICC_RISD_Pixel455_OnOff 0 "Pixel On" 1 "Pixel Off" ;
VAL_ 1364 ICC_RISD_Pixel456_OnOff 0 "Pixel On" 1 "Pixel Off" ;
VAL_ 1364 ICC_RISD_Pixel457_OnOff 0 "Pixel On" 1 "Pixel Off" ;
VAL_ 1364 ICC_RISD_Pixel458_OnOff 0 "Pixel On" 1 "Pixel Off" ;
VAL_ 1364 ICC_RISD_Pixel459_OnOff 0 "Pixel On" 1 "Pixel Off" ;
VAL_ 1364 ICC_RISD_Pixel460_OnOff 0 "Pixel On" 1 "Pixel Off" ;
VAL_ 1364 ICC_RISD_Pixel461_OnOff 0 "Pixel On" 1 "Pixel Off" ;
VAL_ 1364 ICC_RISD_Pixel462_OnOff 0 "Pixel On" 1 "Pixel Off" ;
VAL_ 1364 ICC_RISD_Pixel463_OnOff 0 "Pixel On" 1 "Pixel Off" ;
VAL_ 1364 ICC_RISD_Pixel464_OnOff 0 "Pixel On" 1 "Pixel Off" ;
VAL_ 1364 ICC_RISD_Pixel465_OnOff 0 "Pixel On" 1 "Pixel Off" ;
VAL_ 1364 ICC_RISD_Pixel466_OnOff 0 "Pixel On" 1 "Pixel Off" ;
VAL_ 1364 ICC_RISD_Pixel467_OnOff 0 "Pixel On" 1 "Pixel Off" ;
VAL_ 1364 ICC_RISD_Pixel468_OnOff 0 "Pixel On" 1 "Pixel Off" ;
VAL_ 1364 ICC_RISD_Pixel469_OnOff 0 "Pixel On" 1 "Pixel Off" ;
VAL_ 1364 ICC_RISD_Pixel470_OnOff 0 "Pixel On" 1 "Pixel Off" ;
VAL_ 1364 ICC_RISD_Pixel471_OnOff 0 "Pixel On" 1 "Pixel Off" ;
VAL_ 1364 ICC_RISD_Pixel472_OnOff 0 "Pixel On" 1 "Pixel Off" ;
VAL_ 1364 ICC_RISD_Pixel473_OnOff 0 "Pixel On" 1 "Pixel Off" ;
VAL_ 1364 ICC_RISD_Pixel474_OnOff 0 "Pixel On" 1 "Pixel Off" ;
VAL_ 1364 ICC_RISD_Pixel475_OnOff 0 "Pixel On" 1 "Pixel Off" ;
VAL_ 1364 ICC_RISD_Pixel476_OnOff 0 "Pixel On" 1 "Pixel Off" ;
VAL_ 1364 ICC_RISD_Pixel477_OnOff 0 "Pixel On" 1 "Pixel Off" ;
VAL_ 1364 ICC_RISD_Pixel478_OnOff 0 "Pixel On" 1 "Pixel Off" ;
VAL_ 1364 ICC_RISD_Pixel479_OnOff 0 "Pixel On" 1 "Pixel Off" ;
VAL_ 1364 ICC_RISD_Pixel480_OnOff 0 "Pixel On" 1 "Pixel Off" ;
VAL_ 1364 ICC_RISD_Pixel481_OnOff 0 "Pixel On" 1 "Pixel Off" ;
VAL_ 1364 ICC_RISD_Pixel482_OnOff 0 "Pixel On" 1 "Pixel Off" ;
VAL_ 1364 ICC_RISD_Pixel483_OnOff 0 "Pixel On" 1 "Pixel Off" ;
VAL_ 1364 ICC_RISD_Pixel484_OnOff 0 "Pixel On" 1 "Pixel Off" ;
VAL_ 1364 ICC_RISD_Pixel485_OnOff 0 "Pixel On" 1 "Pixel Off" ;
VAL_ 1364 ICC_RISD_Pixel486_OnOff 0 "Pixel On" 1 "Pixel Off" ;
VAL_ 1364 ICC_RISD_Pixel487_OnOff 0 "Pixel On" 1 "Pixel Off" ;
VAL_ 1364 ICC_RISD_Pixel488_OnOff 0 "Pixel On" 1 "Pixel Off" ;
VAL_ 1364 ICC_RISD_Pixel489_OnOff 0 "Pixel On" 1 "Pixel Off" ;
VAL_ 1364 ICC_RISD_Pixel490_OnOff 0 "Pixel On" 1 "Pixel Off" ;
VAL_ 1364 ICC_RISD_Pixel491_OnOff 0 "Pixel On" 1 "Pixel Off" ;
VAL_ 1364 ICC_RISD_Pixel492_OnOff 0 "Pixel On" 1 "Pixel Off" ;
VAL_ 1364 ICC_RISD_Pixel493_OnOff 0 "Pixel On" 1 "Pixel Off" ;
VAL_ 1364 ICC_RISD_Pixel494_OnOff 0 "Pixel On" 1 "Pixel Off" ;
VAL_ 1364 ICC_RISD_Pixel495_OnOff 0 "Pixel On" 1 "Pixel Off" ;
VAL_ 1364 ICC_RISD_Pixel496_OnOff 0 "Pixel On" 1 "Pixel Off" ;
VAL_ 1364 ICC_RISD_Pixel497_OnOff 0 "Pixel On" 1 "Pixel Off" ;
VAL_ 1364 ICC_RISD_Pixel498_OnOff 0 "Pixel On" 1 "Pixel Off" ;
VAL_ 1364 ICC_RISD_Pixel499_OnOff 0 "Pixel On" 1 "Pixel Off" ;
VAL_ 1364 ICC_RISD_Pixel500_OnOff 0 "Pixel On" 1 "Pixel Off" ;
VAL_ 1364 ICC_RISD_Pixel501_OnOff 0 "Pixel On" 1 "Pixel Off" ;
VAL_ 1364 ICC_RISD_Pixel502_OnOff 0 "Pixel On" 1 "Pixel Off" ;
VAL_ 1364 ICC_RISD_Pixel503_OnOff 0 "Pixel On" 1 "Pixel Off" ;
VAL_ 1364 ICC_RISD_Pixel504_OnOff 0 "Pixel On" 1 "Pixel Off" ;
VAL_ 1366 ICC_LKSSettingModSt 0 "Not Active" 1 "Warning" 2 "Warning And Intervention" 3 "OFF" ;
VAL_ 1366 ICC_LDWWarnType 0 "Not Active" 1 "Warning Only" 2 "Vibration  Only" 3 "Warning And Vibration" ;
VAL_ 1366 ICC_LDWLDPSnvtySet 0 "Not Active" 1 "High" 2 "Low" 3 "reserve" ;
VAL_ 1366 ICC_ELKSettingSt 0 "Not Active" 1 "ON" 2 "OFF" 3 "Reserved" ;
VAL_ 1366 ICC_ICAEnableBtnSts 0 "Not Active" 1 "ON" 2 "OFF" 3 "Reserved" ;
VAL_ 1366 ICC_FCWSettingSt 0 "Not Active" 1 "OFF" 2 "High" 3 "Middle" 4 "Low" 5 "Reserved" 6 "Reserved" 7 "Reserved" ;
VAL_ 1366 ICC_AEBSettingSt 0 "Not Active" 1 "ON" 2 "OFF" 3 "Reserved" ;
VAL_ 1366 ICC_ISLIWarnMod 0 "Not Active" 1 "Display warning" 2 "Sound And Display Warning" 3 "OFF" ;
VAL_ 1366 ICC_Reset 0 "Not_Active" 1 "ON" ;
VAL_ 1366 ICC_Customize_buttons 0 "Not Active" 1 "APA" 2 "TJA/ICA/ACC/NOA" 3 "Offroad AutoPilot" 4 "HPA" 5 "Not used" 6 "Not used" 7 "Not used" ;
VAL_ 1366 ICC_AVM_TouchEvt 0 "Not active" 1 "Press down" 2 "Moving" 3 "Lift up" ;
VAL_ 1356 ICC_flag 0 "invalid" 1 "sim" 2 "tsp register" ;
VAL_ 1356 ICC_ActiveTsp_Req 0 "invalid" 1 "Do not initiate TSP registration" 2 "initiate TSP registration" ;
VAL_ 1356 ICC_ActiveSim_Req 0 "invalid" 1 "sim not activate" 2 "sim activate" ;
VAL_ 1356 ICC_GetMac_req 0 "invalid" 1 "search" ;
VAL_ 1356 ICC_GetIccid_Vin 0 "invalid" 1 "search" ;
VAL_ 1356 ICC_GivePlatformNumber_Flag 0 "platform_number invalid" 1 "platform_number valid" ;
VAL_ 1356 ICC_Mac_Flag 0 "IccMacInvalid" 1 "IccMacValid" ;
VAL_ 1453 ICC_BedStatus 0 "Not Active" 1 "Large Bed At Home" 2 "Single Bed" 3 "Sofa For Parking" 4 "Reserved" 5 "Reserved" 6 "Reserved" 7 "OFF" ;
VAL_ 1453 ICC_MemAttributeFL 0 "Not Active" 1 "Children" 2 "Youth" 3 "Oldman" 4 "reserved" 5 "reserved" 6 "reserved" 7 "reserved" ;
VAL_ 1453 ICC_MemAttributeFR 0 "Not Active" 1 "Children" 2 "Youth" 3 "Oldman" 4 "reserved" 5 "reserved" 6 "reserved" 7 "reserved" ;
VAL_ 1453 ICC_MemAttributeRL 0 "Not Active" 1 "Children" 2 "Youth" 3 "Oldman" 4 "reserved" 5 "reserved" 6 "reserved" 7 "reserved" ;
VAL_ 1453 ICC_MemAttributeRR 0 "Not Active" 1 "Children" 2 "Youth" 3 "Oldman" 4 "reserved" 5 "reserved" 6 "reserved" 7 "reserved" ;
VAL_ 1380 ICC_FLSeatHeatLvlCmd2 0 "Not active" 1 "OFF" 2 "Seat heating Level1" 3 "Seat heating Level2" 4 "Seat heating Level3" 5 "Seat heating Level4" 6 "Seat heating Level5" 7 "Seat heating Level6" 8 "Seat heating Level7" 9 "Seat heating Level8" 10 "Seat heating Level9" 11 "Reserved" ;
VAL_ 1380 ICC_RLSeatHeatLvlCmd2 0 "Not active" 1 "OFF" 2 "Seat heating Level1" 3 "Seat heating Level2" 4 "Seat heating Level3" 5 "Seat heating Level4" 6 "Seat heating Level5" 7 "Seat heating Level6" 8 "Seat heating Level7" 9 "Seat heating Level8" 10 "Seat heating Level9" 11 "Reserved" ;
VAL_ 1380 ICC_FLSeatVentLvlCmd2 0 "Not Active" 1 "OFF" 2 "Seat Ventilation Level1" 3 "Seat Ventilation Level2" 4 "Seat Ventilation Level3" 5 "Seat Ventilation Level4" 6 "Seat Ventilation Level5" 7 "Seat Ventilation Level6" 8 "Seat Ventilation Level7" 9 "Seat Ventilation Level8" 10 "Seat Ventilation Level9" 11 "Reserved" ;
VAL_ 1380 ICC_RLSeatVentLvlCmd2 0 "Not Active" 1 "OFF" 2 "Seat Ventilation Level1" 3 "Seat Ventilation Level2" 4 "Seat Ventilation Level3" 5 "Seat Ventilation Level4" 6 "Seat Ventilation Level5" 7 "Seat Ventilation Level6" 8 "Seat Ventilation Level7" 9 "Seat Ventilation Level8" 10 "Seat Ventilation Level9" 11 "Reserved" ;
VAL_ 1380 ICC_FRSeatHeatLvlCmd2 0 "Not active" 1 "OFF" 2 "Seat heating Level1" 3 "Seat heating Level2" 4 "Seat heating Level3" 5 "Seat heating Level4" 6 "Seat heating Level5" 7 "Seat heating Level6" 8 "Seat heating Level7" 9 "Seat heating Level8" 10 "Seat heating Level9" 11 "Reserved" ;
VAL_ 1380 ICC_RRSeatHeatLvlCmd2 0 "Not active" 1 "OFF" 2 "Seat heating Level1" 3 "Seat heating Level2" 4 "Seat heating Level3" 5 "Seat heating Level4" 6 "Seat heating Level5" 7 "Seat heating Level6" 8 "Seat heating Level7" 9 "Seat heating Level8" 10 "Seat heating Level9" 11 "Reserved" ;
VAL_ 1380 ICC_FRSeatVentLvlCmd2 0 "Not Active" 1 "OFF" 2 "Seat Ventilation Level1" 3 "Seat Ventilation Level2" 4 "Seat Ventilation Level3" 5 "Seat Ventilation Level4" 6 "Seat Ventilation Level5" 7 "Seat Ventilation Level6" 8 "Seat Ventilation Level7" 9 "Seat Ventilation Level8" 10 "Seat Ventilation Level9" 11 "Reserved" ;
VAL_ 1380 ICC_RRSeatVentLvlCmd2 0 "Not Active" 1 "OFF" 2 "Seat Ventilation Level1" 3 "Seat Ventilation Level2" 4 "Seat Ventilation Level3" 5 "Seat Ventilation Level4" 6 "Seat Ventilation Level5" 7 "Seat Ventilation Level6" 8 "Seat Ventilation Level7" 9 "Seat Ventilation Level8" 10 "Seat Ventilation Level9" 11 "Reserved" ;
VAL_ 1560 RMR_ICC 0 "Inactive" 1 "Active" ;
VAL_ 1560 ICC_Wakeup_Poweron 0 "Inactive" 1 "Active" ;
VAL_ 1560 ICC_Wakeup_NM 0 "Inactive" 1 "Active" ;
VAL_ 1560 ICC_Wakeup_Diag 0 "Inactive" 1 "Active" ;
VAL_ 1560 ICC_Wakeup_PowerComfortable 0 "Inactive" 1 "Active" ;
VAL_ 1560 ICC_Wakeup_HUD 0 "Inactive" 1 "Active" ;
VAL_ 1560 ICC_Wakeup_EAMP 0 "Inactive" 1 "Active" ;
VAL_ 1560 ICC_Awake_Poweron 0 "Inactive" 1 "Active" ;
VAL_ 1560 ICC_Awake_NM 0 "Inactive" 1 "Active" ;
VAL_ 1560 ICC_Awake_DiagETH 0 "Inactive" 1 "Active" ;
VAL_ 1560 ICC_Awake_PowerComfortable 0 "Inactive" 1 "Active" ;
VAL_ 1560 ICC_Awake_SentinelMode 0 "Inactive" 1 "Active" ;
VAL_ 1560 ICC_Awake_PetMode 0 "Inactive" 1 "Active" ;
VAL_ 1560 ICC_Awake_HUD 0 "Inactive" 1 "Active" ;
VAL_ 1560 ICC_Awake_EAMP 0 "Inactive" 1 "Active" ;
VAL_ 1560 ICC_Awake_FreezerFunction 0 "Inactive" 1 "Active" ;
VAL_ 1560 ICC_Awake_PowerOffDelay 0 "Inactive" 1 "Active" ;
VAL_ 859 RearDefrostSts 0 "OFF" 1 "ON" ;
VAL_ 1181 FLZCU_9_PowerMode 0 "Off" 1 "Comfortable" 2 "ON" 3 "Reserved" ;
VAL_ 1181 FLZCU_9_ArmingSts 0 "Not active" 1 "Arming successful" 2 "Disarming successful" 3 "Invalid" ;
VAL_ 1030 RearViewFoldSts 0 "invalid" 1 "Fold" 2 "unFold" ;
VAL_ 1030 FLZCU_AlrmSts 0 "Not active" 1 "Arming Mode" 2 "Pre_rearming Mode" 3 "Trunk Opening Mode" 4 "Alarm Mode" 5 "Disarm Mode" 6 "Arming Fault Mode" 7 "reserved" ;
VAL_ 1030 FLZCU_SteeringMode 0 "Not Active" 1 "Normal" 2 "Sport" 3 "Light" ;
VAL_ 1030 FLZCU_SuspensionDamping 0 "Not Active" 1 "Soft" 2 "Middle" 3 "Hard" ;
VAL_ 1030 FLZCU_SuspensionHeight 0 "Not Active" 1 "Very Low" 2 "Low" 3 "Normal" 4 "High" 5 "Very High" ;
VAL_ 1030 FLZCU_OBDDiagOccupy 0 "Not Occupy" 1 "Occupy" ;
VAL_ 1071 FLZCU_AutoFoldSts 0 "Not autofold mode" 1 "Autofold mode" ;
VAL_ 1071 FLZCU_AutolockSts 0 "Not autolock mode" 1 "Autolock mode" ;
VAL_ 1071 FLZCU_FGHeat_Req_CmdFeedback 0 "Off" 1 "On" ;
VAL_ 1071 FLZCU_WindowInhibitSts 0 "Permit" 1 "Inhibit" ;
VAL_ 1071 FLZCU_AutoReadLightSts 0 "Close" 1 "Open" ;
VAL_ 1071 FLZCU_HeatingSW 0 "Off" 1 "On" ;
VAL_ 1071 FLZCU_AutoHeatingFb 0 "Close" 1 "Open" ;
VAL_ 1071 FLZCU_SteerNeedMemory 0 "NO Request" 1 "Request" ;
VAL_ 1071 FLZCU_LowBeamFaults 0 "Not Faults" 1 "Faults" ;
VAL_ 1071 FLZCU_RearNeedMemory 0 "NO Request" 1 "Request" ;
VAL_ 1071 FLZCU_BrkLightFaults 0 "Not Faults" 1 "Faults" ;
VAL_ 1071 FLZCU_TurnLiSwtSts 0 "OFF" 1 "turn left" 2 "turn right" 3 "left change" 4 "right change" 5 "Reserved" 6 "Reserved" 7 "fault" ;
VAL_ 1071 FLZCU_FLHandleFoldedStatus 0 "Fold" 1 "Unfold" 2 "Unknown" 3 "Reserved" ;
VAL_ 1071 FLZCU_RLHandleFoldedStatus 0 "Fold" 1 "Unfold" 2 "Unknown" 3 "Reserved" ;
VAL_ 1071 FLZCU_FRHandleFoldedStatus 0 "Fold" 1 "Unfold" 2 "Unknown" 3 "Reserved" ;
VAL_ 1071 FLZCU_RRHandleFoldedStatus 0 "Fold" 1 "Unfold" 2 "Unknown" 3 "Reserved" ;
VAL_ 1071 FLZCU_RvsExtMirrFbSts 0 "OFF" 1 "Only Right Side" 2 "Only Left Side" 3 "Both Sides" ;
VAL_ 1071 FLZCU_LightMainSwitchSts 0 "Not active" 1 "Off Position" 2 "Auto Position" 3 "PositionLampSwitch Position" 4 "LowBeamSwitch Position" 5 "Reserved" 6 "Reserved" 7 "Reserved" ;
VAL_ 1071 FLZCU_BeamDelaySts 0 "Not Active" 1 "0s" 2 "10s" 3 "20s" 4 "30s" 5 "60s" 6 "Reserved" 7 "Reserved" ;
VAL_ 1071 FLZCU_LowBeamHighSts 0 "Level 0" 1 "Level 1" 2 "Level 2" 3 "Level 3" 4 "Reserved" 5 "Reserved" 6 "Reserved" 7 "Reserved" ;
VAL_ 1071 FLZCU_WipeSensitivitySts 0 "Not Active" 1 "Level 1" 2 "Level 2" 3 "Level 3" 4 "Level 4" 5 "Reserved" 6 "Reserved" 7 "Reserved" ;
VAL_ 1071 FLZCU_WipeMaintenanceSWSts 0 "Not Active" 1 "Front Wiper" 2 "Rear Wiper" 3 "Both Wiper" ;
VAL_ 1071 FLZCU_HiBeamSwtSts 0 "reserved" 1 "high beam" 2 "flash" 3 "fault" ;
VAL_ 1071 FLZCU_ImmoRequest 0 "no Request" 1 "Request" 2 "BNCM Request" 3 "OTA Request" 4 "TBOX Request" 5 "RMCU Request" 6 "Reserved" 7 "Reserved" ;
VAL_ 1071 FLZCU_AlarmWarnSetSW 0 "Not Active" 1 "OFF" 2 "Only Lighting" 3 "Sound and Lighting" 4 "Reserved" 5 "Reserved" 6 "Reserved" 7 "Reserved" ;
VAL_ 1071 FLZCU_CleanModeStatus 0 "Not active" 1 "OFF" 2 "ON" 3 "Reserved" ;
VAL_ 1071 FLZCU_FLReleaseLockSts 0 "None" 1 "Releasing" 2 "Released" 3 "Reset" 4 "Resetting" 5 "Reserved" 6 "Reserved" 7 "Reserved" ;
VAL_ 1071 FLZCU_RearFogLightSts 0 "OFF" 1 "ON" ;
VAL_ 1071 FLZCU_FRFoglightSts 0 "OFF" 1 "ON" ;
VAL_ 1071 FLZCU_FLFoglightSts 0 "OFF" 1 "ON" ;
VAL_ 1071 FLZCU_RearFogLightFaults 0 "Not Faults" 1 "Faults" ;
VAL_ 1071 FLZCU_HighBeamFaults 0 "Not Faults" 1 "Faults" ;
VAL_ 1071 FLZCU_HighBeamSts 0 "Close" 1 "Open" ;
VAL_ 1071 FLZCU_LowBeamSts 0 "Close" 1 "Open" ;
VAL_ 1071 FLZCU_ParkUnlockEnableFb 0 "Disable" 1 "Enable" ;
VAL_ 1071 FLZCU_RLReleaseLockSts 0 "None" 1 "Releasing" 2 "Released" 3 "Reset" 4 "Resetting" 5 "Reserved" 6 "Reserved" 7 "Reserved" ;
VAL_ 1071 FLZCU_EasyEntryExitFb 0 "Not Active" 1 "ON" 2 "OFF" 3 "Not Used" ;
VAL_ 1071 FLZCU_EmgyLiSwtSts 0 "No Pressed" 1 "Pressed ON" ;
VAL_ 1071 FLZCU_HMASwSts 0 "Not active" 1 "Active" ;
VAL_ 1071 FLZCU_DaytimeLight 0 "None" 1 "Left" 2 "Right" 3 "Both" ;
VAL_ 1071 FLZCU_FGHeatFaults 0 "Not Faults" 1 "Faults" ;
VAL_ 1071 FLZCU_ParkLightFaults 0 "Not Faults" 1 "Faults" ;
VAL_ 1071 FLZCU_LbatipVehPwrMod 0 "No warning" 1 "Warning" ;
VAL_ 1071 FLZCU_LVPowICDsp 0 "Normal" 1 "ChargeFault" 2 "LVBatFaultSt" 3 "BatteryVoltLow" 4 "Reserved" 5 "Reserved" 6 "Reserved" 7 "Reserved" ;
VAL_ 1071 FLZCU_LockCarWinCloseFb 0 "Enable" 1 "Disable" 2 "Reserved" 3 "Reserved" ;
VAL_ 1071 FLZCU_BrkLightSts 0 "Close" 1 "Open" 2 "Reserved" 3 "Reserved" ;
VAL_ 1071 FLZCU_ReverseLightSts 0 "Close" 1 "Open" 2 "Reserved" 3 "Reserved" ;
VAL_ 1071 FLZCU_LowWashLqdWarning 0 "Not Warning" 1 "Warning" 2 "Reserved" 3 "Reserved" ;
VAL_ 1071 FLZCU_SteerWheelHeatingFb 0 "Not Active" 1 "Level1" 2 "Level2" 3 "Level3" 4 "OFF" 5 "Reserved" 6 "Reserved" 7 "Reserved" ;
VAL_ 1071 FLZCU_FrontFogLightSts 0 "OFF" 1 "ON" ;
VAL_ 1071 FLZCU_NapAreaFb 0 "Not Active" 1 "Front Left" 2 "Front Right" 3 "Front Left and Right" ;
VAL_ 1071 FLZCU_NapAlarmStatus 0 "OFF" 1 "ON" 2 "Reserved" 3 "Reserved" ;
VAL_ 1071 FLZCU_NapFailCause 0 "Not Active" 1 "Gear Not P" 2 "Vehicle Speed≠0km/h" 3 "Hood Unlock" 4 "Trunk Unlock" 5 "FLDoor Unlock" 6 "FRDoor Unlock" 7 "RLDoor Unlock" 8 "RRDoor Unlock" 9 "Low Voltage Battery Voltage Low" 10 "High Voltage Battery Low" 11 "Brake Pedal Depressed" 12 "PowerMode Not Comfortable" 13 "Reserved" 14 "Reserved" 15 "Reserved" ;
VAL_ 1071 FLZCU_NapStatusFb 0 "OFF" 1 "ON" 2 "Reserved" 3 "Reserved" ;
VAL_ 1071 FLZCU_CleanModeFailCause 0 "Not Fail" 1 "Fail" 2 "Reserved" 3 "Reserved" ;
VAL_ 1071 FLZCU_NapClosePrompt 0 "Not Active" 1 "Low Voltage Battery Low" 2 "High Voltage Battery Low" 3 "Reserved" ;
VAL_ 1071 FLZCU_AutoWipingInhibit 0 "Not Inhibit" 1 "Inhibit" 2 "Reserved" 3 "Reserved" ;
VAL_ 1071 FLZCU_RLWinSts 0 "Not Active" 1 "Comfort" 2 "Close" 3 "Open" 4 "Other Position" 5 "Closing" 6 "Opening" 7 "Reserved" ;
VAL_ 1071 FLZCU_FLWinSts 0 "Not Active" 1 "Comfort" 2 "Close" 3 "Open" 4 "Other Position" 5 "Closing" 6 "Opening" 7 "Reserved" ;
VAL_ 1071 FLZCU_DaytimeLightFaults 0 "Not Faults" 1 "Faults" ;
VAL_ 1071 FLZCU_FrontFogLightFaults 0 "Not Faults" 1 "Faults" ;
VAL_ 1071 FLZCU_HomeLinkWelLightSetSts 0 "OFF" 1 "ON" 2 "Reserved" 3 "Reserved" ;
VAL_ 1071 FLZCU_HomeLinkArmHornSetSts 0 "OFF" 1 "ON" 2 "Reserved" 3 "Reserved" ;
VAL_ 1071 FLZCU_WelcomeOpenStas 0 "OFF" 1 "ON" ;
VAL_ 1071 FLZCU_WALOpenStas 0 "OFF" 1 "ON" ;
VAL_ 1071 FLZCU_UIROpenStas 0 "OFF" 1 "ON" ;
VAL_ 1071 FLZCU_ExtLiSwtClsSts 0 "Not Active" 1 "OFF" 2 "ON" 3 "Reserved" ;
VAL_ 1211 FLZCU_FLSeatHeiFb 0 "Not active" ;
VAL_ 1211 FLZCU_FLSeatLvlFb 0 "Not active" ;
VAL_ 1211 FLZCU_FLSeatBackAgFb 0 "Not active" ;
VAL_ 1211 FLZCU_FLSeatCushFb 0 "Not active" ;
VAL_ 1211 FLZCU_FLSeatLegSpprtFb 0 "Not active" ;
VAL_ 1211 FLZCU_SeatNeedMemory 0 "NO Request" 1 "Request" ;
VAL_ 1211 FLZCU_MemoryFb 0 "Not Active" 1 "Success" 2 "Fail" 3 "Ongoing" ;
VAL_ 1211 FLZCU_RecoverFb 0 "Not Active" 1 "Success" 2 "Fail" 3 "Ongoing" ;
SIG_GROUP_ 1364 New_Signal_Group_554 1 : ICC_RISD_Pixel504_OnOff ICC_RISD_Pixel503_OnOff ICC_RISD_Pixel502_OnOff ICC_RISD_Pixel501_OnOff ICC_RISD_Pixel500_OnOff ICC_RISD_Pixel499_OnOff ICC_RISD_Pixel498_OnOff ICC_RISD_Pixel497_OnOff ICC_RISD_Pixel496_OnOff ICC_RISD_Pixel495_OnOff ICC_RISD_Pixel494_OnOff ICC_RISD_Pixel493_OnOff ICC_RISD_Pixel492_OnOff ICC_RISD_Pixel491_OnOff ICC_RISD_Pixel490_OnOff ICC_RISD_Pixel489_OnOff ICC_RISD_Pixel488_OnOff ICC_RISD_Pixel487_OnOff ICC_RISD_Pixel486_OnOff ICC_RISD_Pixel485_OnOff ICC_RISD_Pixel484_OnOff ICC_RISD_Pixel483_OnOff ICC_RISD_Pixel482_OnOff ICC_RISD_Pixel481_OnOff ICC_RISD_Pixel480_OnOff ICC_RISD_Pixel479_OnOff ICC_RISD_Pixel478_OnOff ICC_RISD_Pixel476_OnOff ICC_RISD_Pixel477_OnOff ICC_RISD_Pixel475_OnOff ICC_RISD_Pixel474_OnOff ICC_RISD_Pixel473_OnOff ICC_RISD_Pixel472_OnOff ICC_RISD_Pixel471_OnOff ICC_RISD_Pixel470_OnOff ICC_RISD_Pixel469_OnOff ICC_RISD_Pixel468_OnOff ICC_RISD_Pixel467_OnOff ICC_RISD_Pixel466_OnOff ICC_RISD_Pixel465_OnOff ICC_RISD_Pixel464_OnOff ICC_RISD_Pixel463_OnOff ICC_RISD_Pixel462_OnOff ICC_RISD_Pixel461_OnOff ICC_RISD_Pixel460_OnOff ICC_RISD_Pixel459_OnOff ICC_RISD_Pixel458_OnOff ICC_RISD_Pixel457_OnOff ICC_RISD_Pixel456_OnOff ICC_RISD_Pixel455_OnOff ICC_RISD_Pixel454_OnOff ICC_RISD_Pixel453_OnOff ICC_RISD_Pixel452_OnOff ICC_RISD_Pixel451_OnOff ICC_RISD_Pixel450_OnOff ICC_RISD_Pixel449_OnOff ICC_RISD_Pixel448_OnOff ICC_RISD_Pixel447_OnOff ICC_RISD_Pixel446_OnOff ICC_RISD_Pixel445_OnOff ICC_RISD_Pixel444_OnOff ICC_RISD_Pixel443_OnOff ICC_RISD_Pixel442_OnOff ICC_RISD_Pixel441_OnOff ICC_RISD_Pixel440_OnOff ICC_RISD_Pixel439_OnOff ICC_RISD_Pixel438_OnOff ICC_RISD_Pixel437_OnOff ICC_RISD_Pixel436_OnOff ICC_RISD_Pixel435_OnOff ICC_RISD_Pixel434_OnOff ICC_RISD_Pixel433_OnOff ICC_RISD_Pixel432_OnOff ICC_RISD_Pixel431_OnOff ICC_RISD_Pixel430_OnOff ICC_RISD_Pixel429_OnOff ICC_RISD_Pixel428_OnOff ICC_RISD_Pixel427_OnOff ICC_RISD_Pixel426_OnOff ICC_RISD_Pixel425_OnOff ICC_RISD_Pixel424_OnOff ICC_RISD_Pixel423_OnOff ICC_RISD_Pixel422_OnOff ICC_RISD_Pixel421_OnOff ICC_RISD_Pixel420_OnOff ICC_RISD_Pixel419_OnOff ICC_RISD_Pixel418_OnOff ICC_RISD_Pixel417_OnOff ICC_RISD_Pixel416_OnOff ICC_RISD_Pixel415_OnOff ICC_RISD_Pixel414_OnOff ICC_RISD_Pixel413_OnOff ICC_RISD_Pixel412_OnOff ICC_RISD_Pixel411_OnOff ICC_RISD_Pixel410_OnOff ICC_RISD_Pixel409_OnOff ICC_RISD_Pixel408_OnOff ICC_RISD_Pixel407_OnOff ICC_RISD_Pixel406_OnOff ICC_RISD_Pixel405_OnOff ICC_RISD_Pixel404_OnOff ICC_RISD_Pixel403_OnOff ICC_RISD_Pixel402_OnOff ICC_RISD_Pixel401_OnOff ICC_RISD_Pixel400_OnOff ICC_RISD_Pixel399_OnOff ICC_RISD_Pixel398_OnOff ICC_RISD_Pixel397_OnOff ICC_RISD_Pixel396_OnOff ICC_RISD_Pixel395_OnOff ICC_RISD_Pixel394_OnOff ICC_RISD_Pixel393_OnOff ICC_RISD_Pixel392_OnOff ICC_RISD_Pixel391_OnOff ICC_RISD_Pixel390_OnOff ICC_RISD_Pixel389_OnOff ICC_RISD_Pixel388_OnOff ICC_RISD_Pixel387_OnOff ICC_RISD_Pixel386_OnOff ICC_RISD_Pixel385_OnOff ICC_RISD_Pixel384_OnOff ICC_RISD_Pixel383_OnOff ICC_RISD_Pixel382_OnOff ICC_RISD_Pixel381_OnOff ICC_RISD_Pixel380_OnOff ICC_RISD_Pixel379_OnOff ICC_RISD_Pixel378_OnOff ICC_RISD_Pixel377_OnOff ICC_RISD_Pixel376_OnOff ICC_RISD_Pixel375_OnOff ICC_RISD_Pixel374_OnOff ICC_RISD_Pixel373_OnOff ICC_RISD_Pixel372_OnOff ICC_RISD_Pixel371_OnOff ICC_RISD_Pixel370_OnOff ICC_RISD_Pixel369_OnOff ICC_RISD_Pixel368_OnOff ICC_RISD_Pixel367_OnOff ICC_RISD_Pixel366_OnOff ICC_RISD_Pixel365_OnOff ICC_RISD_Pixel364_OnOff ICC_RISD_Pixel363_OnOff ICC_RISD_Pixel362_OnOff ICC_RISD_Pixel361_OnOff ICC_RISD_Pixel360_OnOff ICC_RISD_Pixel359_OnOff ICC_RISD_Pixel358_OnOff ICC_RISD_Pixel357_OnOff ICC_RISD_Pixel356_OnOff ICC_RISD_Pixel355_OnOff ICC_RISD_Pixel354_OnOff ICC_RISD_Pixel353_OnOff ICC_RISD_Pixel352_OnOff ICC_RISD_Pixel351_OnOff ICC_RISD_Pixel350_OnOff ICC_RISD_Pixel349_OnOff ICC_RISD_Pixel348_OnOff ICC_RISD_Pixel347_OnOff ICC_RISD_Pixel346_OnOff ICC_RISD_Pixel345_OnOff ICC_RISD_Pixel344_OnOff ICC_RISD_Pixel343_OnOff ICC_RISD_Pixel342_OnOff ICC_RISD_Pixel341_OnOff ICC_RISD_Pixel340_OnOff ICC_RISD_Pixel339_OnOff ICC_RISD_Pixel338_OnOff ICC_RISD_Pixel337_OnOff ICC_RISD_Pixel336_OnOff ICC_RISD_Pixel335_OnOff ICC_RISD_Pixel334_OnOff ICC_RISD_Pixel333_OnOff ICC_RISD_Pixel332_OnOff ICC_RISD_Pixel331_OnOff ICC_RISD_Pixel330_OnOff ICC_RISD_Pixel329_OnOff ICC_RISD_Pixel328_OnOff ICC_RISD_Pixel327_OnOff ICC_RISD_Pixel326_OnOff ICC_RISD_Pixel325_OnOff ICC_RISD_Pixel324_OnOff ICC_RISD_Pixel323_OnOff ICC_RISD_Pixel322_OnOff ICC_RISD_Pixel321_OnOff ICC_RISD_Pixel320_OnOff ICC_RISD_Pixel319_OnOff ICC_RISD_Pixel318_OnOff ICC_RISD_Pixel317_OnOff ICC_RISD_Pixel316_OnOff ICC_RISD_Pixel315_OnOff ICC_RISD_Pixel314_OnOff ICC_RISD_Pixel313_OnOff ICC_RISD_Pixel312_OnOff ICC_RISD_Pixel311_OnOff ICC_RISD_Pixel310_OnOff ICC_RISD_Pixel309_OnOff ICC_RISD_Pixel308_OnOff ICC_RISD_Pixel307_OnOff ICC_RISD_Pixel306_OnOff ICC_RISD_Pixel305_OnOff ICC_RISD_Pixel304_OnOff ICC_RISD_Pixel303_OnOff ICC_RISD_Pixel302_OnOff ICC_RISD_Pixel301_OnOff ICC_RISD_Pixel300_OnOff ICC_RISD_Pixel299_OnOff ICC_RISD_Pixel298_OnOff ICC_RISD_Pixel297_OnOff ICC_RISD_Pixel296_OnOff ICC_RISD_Pixel295_OnOff ICC_RISD_Pixel294_OnOff ICC_RISD_Pixel293_OnOff ICC_RISD_Pixel292_OnOff ICC_RISD_Pixel291_OnOff ICC_RISD_Pixel290_OnOff ICC_RISD_Pixel289_OnOff ICC_RISD_Pixel288_OnOff ICC_RISD_Pixel287_OnOff ICC_RISD_Pixel286_OnOff ICC_RISD_Pixel285_OnOff ICC_RISD_Pixel284_OnOff ICC_RISD_Pixel283_OnOff ICC_RISD_Pixel282_OnOff ICC_RISD_Pixel281_OnOff ICC_RISD_Pixel280_OnOff ICC_RISD_Pixel279_OnOff ICC_RISD_Pixel278_OnOff ICC_RISD_Pixel277_OnOff ICC_RISD_Pixel276_OnOff ICC_RISD_Pixel275_OnOff ICC_RISD_Pixel274_OnOff ICC_RISD_Pixel273_OnOff ICC_RISD_Pixel272_OnOff ICC_RISD_Pixel271_OnOff ICC_RISD_Pixel270_OnOff ICC_RISD_Pixel269_OnOff ICC_RISD_Pixel268_OnOff ICC_RISD_Pixel267_OnOff ICC_RISD_Pixel266_OnOff ICC_RISD_Pixel265_OnOff ICC_RISD_Pixel264_OnOff ICC_RISD_Pixel263_OnOff ICC_RISD_Pixel262_OnOff ICC_RISD_Pixel261_OnOff ICC_RISD_Pixel260_OnOff ICC_RISD_Pixel259_OnOff ICC_RISD_Pixel258_OnOff ICC_RISD_Pixel257_OnOff ICC_RISD_Pixel256_OnOff ICC_RISD_Pixel255_OnOff ICC_RISD_Pixel254_OnOff ICC_RISD_Pixel253_OnOff ICC_RISD_Pixel252_OnOff ICC_RISD_Pixel251_OnOff ICC_RISD_Pixel250_OnOff ICC_RISD_Pixel249_OnOff ICC_RISD_Pixel248_OnOff ICC_RISD_Pixel247_OnOff ICC_RISD_Pixel246_OnOff ICC_RISD_Pixel245_OnOff ICC_RISD_Pixel244_OnOff ICC_RISD_Pixel243_OnOff ICC_RISD_Pixel242_OnOff ICC_RISD_Pixel241_OnOff ICC_RISD_Pixel240_OnOff ICC_RISD_Pixel239_OnOff ICC_RISD_Pixel238_OnOff ICC_RISD_Pixel237_OnOff ICC_RISD_Pixel236_OnOff ICC_RISD_Pixel235_OnOff ICC_RISD_Pixel234_OnOff ICC_RISD_Pixel233_OnOff ICC_RISD_Pixel232_OnOff ICC_RISD_Pixel231_OnOff ICC_RISD_Pixel230_OnOff ICC_RISD_Pixel229_OnOff ICC_RISD_Pixel228_OnOff ICC_RISD_Pixel227_OnOff ICC_RISD_Pixel226_OnOff ICC_RISD_Pixel225_OnOff ICC_RISD_Pixel224_OnOff ICC_RISD_Pixel223_OnOff ICC_RISD_Pixel222_OnOff ICC_RISD_Pixel221_OnOff ICC_RISD_Pixel220_OnOff ICC_RISD_Pixel219_OnOff ICC_RISD_Pixel218_OnOff ICC_RISD_Pixel217_OnOff ICC_RISD_Pixel216_OnOff ICC_RISD_Pixel215_OnOff ICC_RISD_Pixel214_OnOff ICC_RISD_Pixel213_OnOff ICC_RISD_Pixel212_OnOff ICC_RISD_Pixel211_OnOff ICC_RISD_Pixel210_OnOff ICC_RISD_Pixel209_OnOff ICC_RISD_Pixel208_OnOff ICC_RISD_Pixel207_OnOff ICC_RISD_Pixel206_OnOff ICC_RISD_Pixel205_OnOff ICC_RISD_Pixel204_OnOff ICC_RISD_Pixel203_OnOff ICC_RISD_Pixel202_OnOff ICC_RISD_Pixel201_OnOff ICC_RISD_Pixel200_OnOff ICC_RISD_Pixel199_OnOff ICC_RISD_Pixel198_OnOff ICC_RISD_Pixel197_OnOff ICC_RISD_Pixel196_OnOff ICC_RISD_Pixel195_OnOff ICC_RISD_Pixel194_OnOff ICC_RISD_Pixel193_OnOff ICC_RISD_Pixel192_OnOff ICC_RISD_Pixel191_OnOff ICC_RISD_Pixel190_OnOff ICC_RISD_Pixel189_OnOff ICC_RISD_Pixel188_OnOff ICC_RISD_Pixel187_OnOff ICC_RISD_Pixel186_OnOff ICC_RISD_Pixel185_OnOff ICC_RISD_Pixel184_OnOff ICC_RISD_Pixel183_OnOff ICC_RISD_Pixel182_OnOff ICC_RISD_Pixel181_OnOff ICC_RISD_Pixel180_OnOff ICC_RISD_Pixel179_OnOff ICC_RISD_Pixel178_OnOff ICC_RISD_Pixel177_OnOff ICC_RISD_Pixel176_OnOff ICC_RISD_Pixel175_OnOff ICC_RISD_Pixel174_OnOff ICC_RISD_Pixel173_OnOff ICC_RISD_Pixel172_OnOff ICC_RISD_Pixel171_OnOff ICC_RISD_Pixel170_OnOff ICC_RISD_Pixel169_OnOff ICC_RISD_Pixel168_OnOff ICC_RISD_Pixel167_OnOff ICC_RISD_Pixel166_OnOff ICC_RISD_Pixel165_OnOff ICC_RISD_Pixel164_OnOff ICC_RISD_Pixel163_OnOff ICC_RISD_Pixel162_OnOff ICC_RISD_Pixel161_OnOff ICC_RISD_Pixel160_OnOff ICC_RISD_Pixel159_OnOff ICC_RISD_Pixel158_OnOff ICC_RISD_Pixel157_OnOff ICC_RISD_Pixel156_OnOff ICC_RISD_Pixel155_OnOff ICC_RISD_Pixel154_OnOff ICC_RISD_Pixel153_OnOff ICC_RISD_Pixel152_OnOff ICC_RISD_Pixel151_OnOff ICC_RISD_Pixel150_OnOff ICC_RISD_Pixel149_OnOff ICC_RISD_Pixel148_OnOff ICC_RISD_Pixel147_OnOff ICC_RISD_Pixel146_OnOff ICC_RISD_Pixel145_OnOff ICC_RISD_Pixel144_OnOff ICC_RISD_Pixel143_OnOff ICC_RISD_Pixel142_OnOff ICC_RISD_Pixel141_OnOff ICC_RISD_Pixel140_OnOff ICC_RISD_Pixel139_OnOff ICC_RISD_Pixel138_OnOff ICC_RISD_Pixel137_OnOff ICC_RISD_Pixel136_OnOff ICC_RISD_Pixel135_OnOff ICC_RISD_Pixel134_OnOff ICC_RISD_Pixel133_OnOff ICC_RISD_Pixel132_OnOff ICC_RISD_Pixel131_OnOff ICC_RISD_Pixel130_OnOff ICC_RISD_Pixel129_OnOff ICC_RISD_Pixel128_OnOff ICC_RISD_Pixel127_OnOff ICC_RISD_Pixel126_OnOff ICC_RISD_Pixel125_OnOff ICC_RISD_Pixel124_OnOff ICC_RISD_Pixel123_OnOff ICC_RISD_Pixel122_OnOff ICC_RISD_Pixel121_OnOff ICC_RISD_Pixel120_OnOff ICC_RISD_Pixel119_OnOff ICC_RISD_Pixel118_OnOff ICC_RISD_Pixel117_OnOff ICC_RISD_Pixel116_OnOff ICC_RISD_Pixel115_OnOff ICC_RISD_Pixel114_OnOff ICC_RISD_Pixel113_OnOff ICC_RISD_Pixel112_OnOff ICC_RISD_Pixel111_OnOff ICC_RISD_Pixel110_OnOff ICC_RISD_Pixel109_OnOff ICC_RISD_Pixel108_OnOff ICC_RISD_Pixel107_OnOff ICC_RISD_Pixel106_OnOff ICC_RISD_Pixel105_OnOff ICC_RISD_Pixel104_OnOff ICC_RISD_Pixel103_OnOff ICC_RISD_Pixel102_OnOff ICC_RISD_Pixel101_OnOff ICC_RISD_Pixel100_OnOff ICC_RISD_Pixel99_OnOff ICC_RISD_Pixel98_OnOff ICC_RISD_Pixel97_OnOff ICC_RISD_Pixel96_OnOff ICC_RISD_Pixel95_OnOff ICC_RISD_Pixel94_OnOff ICC_RISD_Pixel93_OnOff ICC_RISD_Pixel92_OnOff ICC_RISD_Pixel91_OnOff ICC_RISD_Pixel90_OnOff ICC_RISD_Pixel89_OnOff ICC_RISD_Pixel88_OnOff ICC_RISD_Pixel87_OnOff ICC_RISD_Pixel86_OnOff ICC_RISD_Pixel85_OnOff ICC_RISD_Pixel84_OnOff ICC_RISD_Pixel83_OnOff ICC_RISD_Pixel82_OnOff ICC_RISD_Pixel81_OnOff ICC_RISD_Pixel80_OnOff ICC_RISD_Pixel79_OnOff ICC_RISD_Pixel78_OnOff ICC_RISD_Pixel77_OnOff ICC_RISD_Pixel76_OnOff ICC_RISD_Pixel75_OnOff ICC_RISD_Pixel74_OnOff ICC_RISD_Pixel73_OnOff ICC_RISD_Pixel72_OnOff ICC_RISD_Pixel71_OnOff ICC_RISD_Pixel70_OnOff ICC_RISD_Pixel69_OnOff ICC_RISD_Pixel68_OnOff ICC_RISD_Pixel67_OnOff ICC_RISD_Pixel66_OnOff ICC_RISD_Pixel65_OnOff ICC_RISD_Pixel64_OnOff ICC_RISD_Pixel63_OnOff ICC_RISD_Pixel62_OnOff ICC_RISD_Pixel61_OnOff ICC_RISD_Pixel60_OnOff ICC_RISD_Pixel59_OnOff ICC_RISD_Pixel58_OnOff ICC_RISD_Pixel57_OnOff ICC_RISD_Pixel56_OnOff ICC_RISD_Pixel55_OnOff ICC_RISD_Pixel54_OnOff ICC_RISD_Pixel53_OnOff ICC_RISD_Pixel52_OnOff ICC_RISD_Pixel51_OnOff ICC_RISD_Pixel50_OnOff ICC_RISD_Pixel49_OnOff ICC_RISD_Pixel48_OnOff ICC_RISD_Pixel47_OnOff ICC_RISD_Pixel46_OnOff ICC_RISD_Pixel45_OnOff ICC_RISD_Pixel44_OnOff ICC_RISD_Pixel43_OnOff ICC_RISD_Pixel42_OnOff ICC_RISD_Pixel41_OnOff ICC_RISD_Pixel40_OnOff ICC_RISD_Pixel39_OnOff ICC_RISD_Pixel38_OnOff ICC_RISD_Pixel37_OnOff ICC_RISD_Pixel36_OnOff ICC_RISD_Pixel35_OnOff ICC_RISD_Pixel34_OnOff ICC_RISD_Pixel33_OnOff ICC_RISD_Pixel32_OnOff ICC_RISD_Pixel31_OnOff ICC_RISD_Pixel30_OnOff ICC_RISD_Pixel29_OnOff ICC_RISD_Pixel28_OnOff ICC_RISD_Pixel27_OnOff ICC_RISD_Pixel26_OnOff ICC_RISD_Pixel25_OnOff ICC_RISD_Pixel24_OnOff ICC_RISD_Pixel23_OnOff ICC_RISD_Pixel22_OnOff ICC_RISD_Pixel21_OnOff ICC_RISD_Pixel20_OnOff ICC_RISD_Pixel19_OnOff ICC_RISD_Pixel18_OnOff ICC_RISD_Pixel17_OnOff ICC_RISD_Pixel16_OnOff ICC_RISD_Pixel15_OnOff ICC_RISD_Pixel14_OnOff ICC_RISD_Pixel13_OnOff ICC_RISD_Pixel12_OnOff ICC_RISD_Pixel11_OnOff ICC_RISD_Pixel10_OnOff ICC_RISD_Pixel9_OnOff ICC_RISD_Pixel8_OnOff ICC_RISD_Pixel7_OnOff ICC_RISD_Pixel6_OnOff ICC_RISD_Pixel5_OnOff ICC_RISD_Pixel4_OnOff ICC_RISD_Pixel3_OnOff ICC_RISD_Pixel2_OnOff ICC_RISD_Pixel1_OnOff ICC_RISD_RollingCounter ICC_RISD_FrameCounter;
SIG_GROUP_ 1366 New_Signal_Group_556 1 : TimeToStartSentinelHourSet_556h TimeToStartSentinelDaySet_556h TimeToStartSentinelMinutSet_556h SentinelModeSwitchReq_556h TimeToStopSentinelHourSet_556h SentinelMode_SensitivityReq_556h TimeToStopSentinelMinutSet_556h ReservationSentinelReq_556h ICC_AVM_BtnPressInputValueY ICC_AVM_BtnPressInputValueX ICC_AVM_TouchEvt ICC_Customize_buttons ICC_Reset ICC_ISLIWarnMod ICC_AEBSettingSt ICC_FCWSettingSt ICC_ICAEnableBtnSts ICC_ELKSettingSt ICC_LDWLDPSnvtySet ICC_LDWWarnType ICC_LKSSettingModSt;
